VERSION "created by canmatrix"

NS_ :

BS_:

BU_: IPD

BO_ 172 RZCU_PTCANFD_10ms_FrP90: 20 Vector__XXX
 SG_ RZCU_10ms_Group90_CRC : 7|8@0+ (1,0) [0|255] "null" IPD
 SG_ RZCU_10ms_Group90_RC : 11|4@0+ (1,0) [0|15] "null" IPD
 SG_ RZCU_10ms_Group90_Reserved15 : 15|4@0+ (1,0) [0|15] "null" IPD
 SG_ RZCU_10ms_Group90_Reserved23 : 23|8@0+ (1,0) [0|255] "null" IPD
 SG_ RZCU_10ms_Group90_Reserved31 : 31|8@0+ (1,0) [0|255] "null" IPD
 SG_ RZCU_10ms_Group90_Reserved39 : 39|8@0+ (1,0) [0|255] "null" IPD
 SG_ RZCU_10ms_Group90_Reserved47 : 47|8@0+ (1,0) [0|255] "null" IPD
 SG_ RZCU_10ms_Group90_Reserved55 : 55|8@0+ (1,0) [0|255] "null" IPD
 SG_ RZCU_10ms_Group90_Reserved63 : 63|8@0+ (1,0) [0|255] "null" IPD
 SG_ RZCU_10ms_Group90_Reserved71 : 71|8@0+ (1,0) [0|255] "null" IPD
 SG_ RZCU_10ms_Group90_Reserved79 : 79|8@0+ (1,0) [0|255] "null" IPD
 SG_ RZCU_10ms_Group90_Reserved83 : 83|4@0+ (1,0) [0|15] "null" IPD
 SG_ VCU_ISAOvSpdOvRd : 85|2@0+ (1,0) [0|3] "null" IPD
 SG_ RZCU_10ms_Group90_Reserved87 : 87|2@0+ (1,0) [0|3] "null" IPD
 SG_ RZCU_10ms_Group90_Reserved95 : 95|8@0+ (1,0) [0|255] "null" IPD
 SG_ RZCU_10ms_Group90_Reserved103 : 103|8@0+ (1,0) [0|255] "null" IPD
 SG_ RZCU_10ms_Group90_Reserved111 : 111|8@0+ (1,0) [0|255] "null" IPD
 SG_ RZCU_10ms_Group90_Reserved119 : 119|8@0+ (1,0) [0|255] "null" IPD
 SG_ RZCU_10ms_Group90_Reserved127 : 127|8@0+ (1,0) [0|255] "null" IPD
 SG_ RZCU_10ms_Group90_Reserved135 : 135|8@0+ (1,0) [0|255] "null" IPD
 SG_ RZCU_10ms_Group90_Reserved143 : 143|8@0+ (1,0) [0|255] "null" IPD
 SG_ RZCU_10ms_Group90_Reserved151 : 151|8@0+ (1,0) [0|255] "null" IPD
 SG_ RZCU_10ms_Group90_Reserved159 : 159|8@0+ (1,0) [0|255] "null" IPD

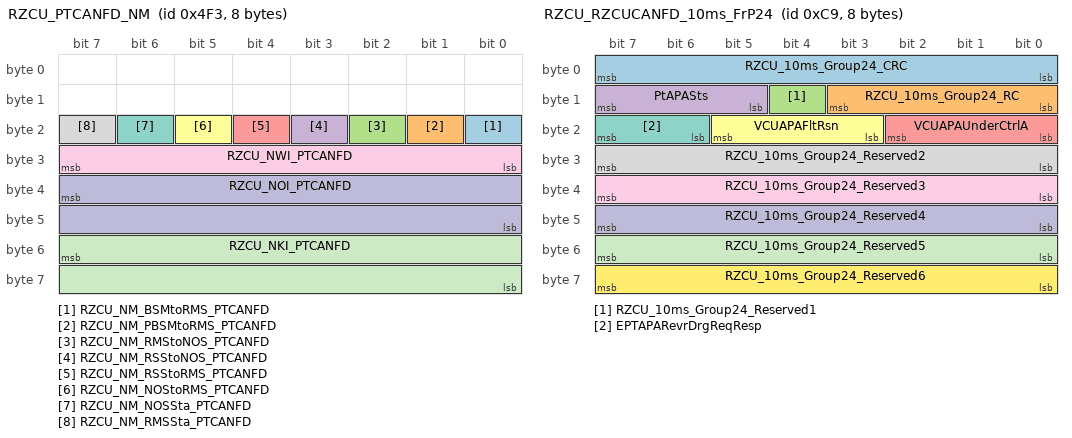
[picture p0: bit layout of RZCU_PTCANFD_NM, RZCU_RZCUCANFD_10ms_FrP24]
BO_ 1267 RZCU_PTCANFD_NM: 8 Vector__XXX
 SG_ RZCU_NM_BSMtoRMS_PTCANFD : 16|1@0+ (1,0) [0|1] "null" Vector__XXX
 SG_ RZCU_NM_PBSMtoRMS_PTCANFD : 17|1@0+ (1,0) [0|1] "null" Vector__XXX
 SG_ RZCU_NM_RMStoNOS_PTCANFD : 18|1@0+ (1,0) [0|1] "null" Vector__XXX
 SG_ RZCU_NM_RSStoNOS_PTCANFD : 19|1@0+ (1,0) [0|1] "null" Vector__XXX
 SG_ RZCU_NM_RSStoRMS_PTCANFD : 20|1@0+ (1,0) [0|1] "null" Vector__XXX
 SG_ RZCU_NM_NOStoRMS_PTCANFD : 21|1@0+ (1,0) [0|1] "null" Vector__XXX
 SG_ RZCU_NM_NOSSta_PTCANFD : 22|1@0+ (1,0) [0|1] "null" Vector__XXX
 SG_ RZCU_NM_RMSSta_PTCANFD : 23|1@0+ (1,0) [0|1] "null" Vector__XXX
 SG_ RZCU_NWI_PTCANFD : 31|8@0+ (1,0) [0|255] "null" Vector__XXX
 SG_ RZCU_NOI_PTCANFD : 39|16@0+ (1,0) [0|65535] "null" Vector__XXX
 SG_ RZCU_NKI_PTCANFD : 55|16@0+ (1,0) [0|65535] "null" Vector__XXX

BO_ 1611 RZCU_RZCUCANFD_1000ms_FrP67: 16 Vector__XXX
 SG_ IMU_SN : 16|96@1- (1,0) [-3.961408125713216879677197517E+028|3.961408125713216879677197517E+028] "null" IPD

BO_ 247 RZCU_RZCUCANFD_10ms_FrP22_NoSecO: 12 Vector__XXX
 SG_ RZCU_10ms_Group22_CRC : 7|8@0+ (1,0) [0|255] "null" IPD
 SG_ RZCU_10ms_Group22_RC : 11|4@0+ (1,0) [0|15] "null" IPD
 SG_ VMCTarWhlTqMaxLmtV : 12|1@0+ (1,0) [0|1] "null" IPD
 SG_ VMCTarReWhlTqMaxLmtV : 13|1@0+ (1,0) [0|1] "null" IPD
 SG_ EPTTrOtptShaftTotMinAvlblToqV : 14|1@0+ (1,0) [0|1] "null" IPD
 SG_ EPTTrOtptShaftTotMaxAvlblToqV : 15|1@0+ (1,0) [0|1] "null" IPD
 SG_ EPTTrOtptShaftTotMaxAvlblToq : 23|12@0+ (0.5,-848) [-848|1199.5] "Nm" IPD
 SG_ EPTTrOtptShaftTotMinAvlblToq : 27|12@0+ (0.5,-848) [-848|1199.5] "Nm" IPD
 SG_ EPTTrOtptShaftTotToq : 43|12@0+ (0.5,-848) [-848|1199.5] "Nm" IPD
 SG_ EPTTrOtptShaftTotToqV : 44|1@0+ (1,0) [0|1] "null" IPD
 SG_ RZCU_10ms_Group22_Reserved47 : 47|3@0+ (1,0) [0|7] "null" IPD
 SG_ VMCTarWhlTqMaxLmt : 63|16@0+ (1,-32767) [-32767|32768] "Nm" IPD
 SG_ VMCTarReWhlTqMaxLmt : 79|16@0+ (1,-32767) [-32767|32768] "Nm" IPD
 SG_ RZCU_10ms_Group22_Reserved95 : 95|8@0+ (1,0) [0|255] "null" IPD

BO_ 225 RZCU_RZCUCANFD_10ms_FrP23: 16 Vector__XXX
 SG_ RZCU_10ms_Group23_CRC : 7|8@0+ (1,0) [0|255] "null" IPD
 SG_ RZCU_10ms_Group23_RC : 11|4@0+ (1,0) [0|15] "null" IPD
 SG_ RZCU_10ms_Group23_Reserved1 : 12|1@0+ (1,0) [0|1] "null" IPD
 SG_ PtAPAToqReqResp : 15|3@0+ (1,0) [0|7] "null" IPD
 SG_ RZCU_10ms_Group23_Reserved3 : 18|3@0+ (1,0) [0|7] "null" IPD
 SG_ AutodDrvngToqReqResp : 21|3@0+ (1,0) [0|7] "null" IPD
 SG_ RZCU_10ms_Group23_Reserved2 : 23|2@0+ (1,0) [0|3] "null" IPD
 SG_ RZCU_10ms_Group23_Reserved4 : 28|5@0+ (1,0) [0|31] "null" IPD
 SG_ PtACCToqReqResp : 31|3@0+ (1,0) [0|7] "null" IPD
 SG_ AIPilotSysSaBrSts : 35|4@0+ (1,0) [0|15] "null" IPD
 SG_ AIPilotSysSaBrInh : 39|4@0+ (1,0) [0|15] "null" IPD
 SG_ RZCU_10ms_Group23_Reserved5 : 47|8@0+ (1,0) [0|255] "null" IPD
 SG_ RZCU_10ms_Group23_Reserved6 : 54|7@0+ (1,0) [0|127] "null" IPD
 SG_ AccelOvrd : 55|1@0+ (1,0) [0|1] "null" IPD
 SG_ RZCU_10ms_Group23_Reserved7 : 63|8@0+ (1,0) [0|255] "null" IPD
 SG_ RZCU_10ms_Group23_Reserved8 : 71|8@0+ (1,0) [0|255] "null" IPD
 SG_ RZCU_10ms_Group23_Reserved9 : 79|8@0+ (1,0) [0|255] "null" IPD
 SG_ RZCU_10ms_Group23_Reserved10 : 87|8@0+ (1,0) [0|255] "null" IPD
 SG_ RZCU_10ms_Group23_Reserved11 : 95|8@0+ (1,0) [0|255] "null" IPD
 SG_ RZCU_10ms_Group23_Reserved12 : 103|8@0+ (1,0) [0|255] "null" IPD
 SG_ RZCU_10ms_Group23_Reserved13 : 111|8@0+ (1,0) [0|255] "null" IPD
 SG_ RZCU_10ms_Group23_Reserved14 : 119|8@0+ (1,0) [0|255] "null" IPD
 SG_ RZCU_10ms_Group23_Reserved15 : 127|8@0+ (1,0) [0|255] "null" IPD

BO_ 201 RZCU_RZCUCANFD_10ms_FrP24: 8 Vector__XXX
 SG_ RZCU_10ms_Group24_CRC : 7|8@0+ (1,0) [0|255] "null" IPD
 SG_ RZCU_10ms_Group24_RC : 11|4@0+ (1,0) [0|15] "null" IPD
 SG_ RZCU_10ms_Group24_Reserved1 : 12|1@0+ (1,0) [0|1] "null" IPD
 SG_ PtAPASts : 15|3@0+ (1,0) [0|7] "null" IPD
 SG_ VCUAPAUnderCtrlA : 18|3@0+ (1,0) [0|7] "null" IPD
 SG_ VCUAPAFltRsn : 21|3@0+ (1,0) [0|7] "null" IPD
 SG_ EPTAPARevrDrgReqResp : 23|2@0+ (1,0) [0|3] "null" IPD
 SG_ RZCU_10ms_Group24_Reserved2 : 31|8@0+ (1,0) [0|255] "null" IPD
 SG_ RZCU_10ms_Group24_Reserved3 : 39|8@0+ (1,0) [0|255] "null" IPD
 SG_ RZCU_10ms_Group24_Reserved4 : 47|8@0+ (1,0) [0|255] "null" IPD
 SG_ RZCU_10ms_Group24_Reserved5 : 55|8@0+ (1,0) [0|255] "null" IPD
 SG_ RZCU_10ms_Group24_Reserved6 : 63|8@0+ (1,0) [0|255] "null" IPD

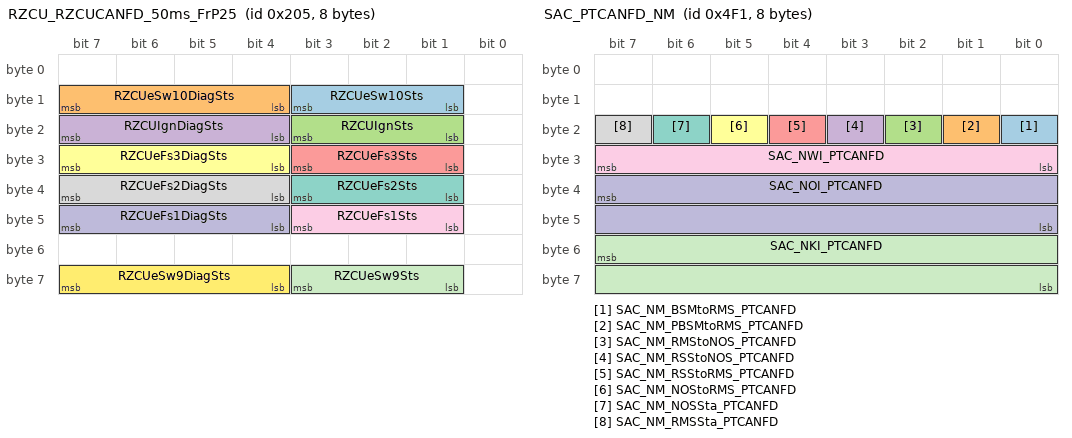
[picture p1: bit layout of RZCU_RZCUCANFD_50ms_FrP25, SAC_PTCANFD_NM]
BO_ 517 RZCU_RZCUCANFD_50ms_FrP25: 8 Vector__XXX
 SG_ RZCUeSw10Sts : 11|3@0+ (1,0) [0|7] "null" Vector__XXX
 SG_ RZCUeSw10DiagSts : 15|4@0+ (1,0) [0|15] "null" Vector__XXX
 SG_ RZCUIgnSts : 19|3@0+ (1,0) [0|7] "null" IPD
 SG_ RZCUIgnDiagSts : 23|4@0+ (1,0) [0|15] "null" IPD
 SG_ RZCUeFs3Sts : 27|3@0+ (1,0) [0|7] "null" Vector__XXX
 SG_ RZCUeFs3DiagSts : 31|4@0+ (1,0) [0|15] "null" Vector__XXX
 SG_ RZCUeFs2Sts : 35|3@0+ (1,0) [0|7] "null" Vector__XXX
 SG_ RZCUeFs2DiagSts : 39|4@0+ (1,0) [0|15] "null" Vector__XXX
 SG_ RZCUeFs1Sts : 43|3@0+ (1,0) [0|7] "null" Vector__XXX
 SG_ RZCUeFs1DiagSts : 47|4@0+ (1,0) [0|15] "null" Vector__XXX
 SG_ RZCUeSw9Sts : 59|3@0+ (1,0) [0|7] "null" Vector__XXX
 SG_ RZCUeSw9DiagSts : 63|4@0+ (1,0) [0|15] "null" Vector__XXX

BO_ 1265 SAC_PTCANFD_NM: 8 Vector__XXX
 SG_ SAC_NM_BSMtoRMS_PTCANFD : 16|1@0+ (1,0) [0|1] "null" Vector__XXX
 SG_ SAC_NM_PBSMtoRMS_PTCANFD : 17|1@0+ (1,0) [0|1] "null" Vector__XXX
 SG_ SAC_NM_RMStoNOS_PTCANFD : 18|1@0+ (1,0) [0|1] "null" Vector__XXX
 SG_ SAC_NM_RSStoNOS_PTCANFD : 19|1@0+ (1,0) [0|1] "null" Vector__XXX
 SG_ SAC_NM_RSStoRMS_PTCANFD : 20|1@0+ (1,0) [0|1] "null" Vector__XXX
 SG_ SAC_NM_NOStoRMS_PTCANFD : 21|1@0+ (1,0) [0|1] "null" Vector__XXX
 SG_ SAC_NM_NOSSta_PTCANFD : 22|1@0+ (1,0) [0|1] "null" Vector__XXX
 SG_ SAC_NM_RMSSta_PTCANFD : 23|1@0+ (1,0) [0|1] "null" Vector__XXX
 SG_ SAC_NWI_PTCANFD : 31|8@0+ (1,0) [0|255] "null" Vector__XXX
 SG_ SAC_NOI_PTCANFD : 39|16@0+ (1,0) [0|65535] "null" Vector__XXX
 SG_ SAC_NKI_PTCANFD : 55|16@0+ (1,0) [0|65535] "null" Vector__XXX

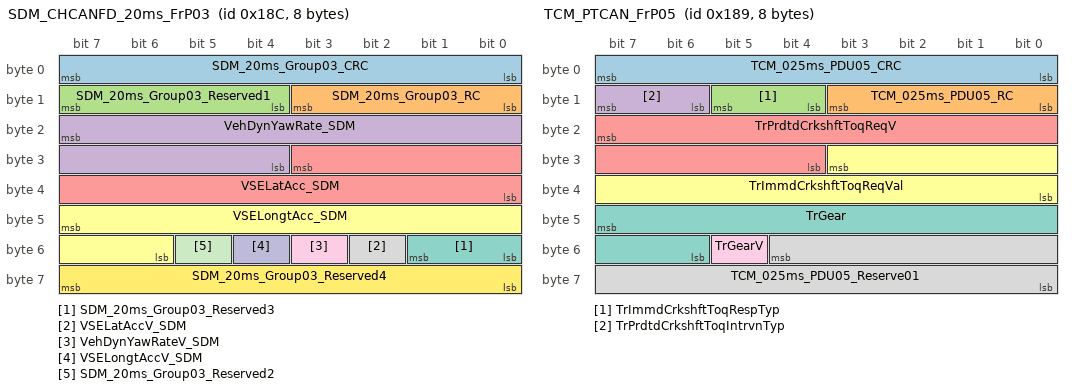
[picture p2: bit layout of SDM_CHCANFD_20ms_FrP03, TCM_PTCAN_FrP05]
BO_ 396 SDM_CHCANFD_20ms_FrP03: 8 Vector__XXX
 SG_ SDM_20ms_Group03_CRC : 7|8@0+ (1,0) [0|255] "null" IPD
 SG_ SDM_20ms_Group03_RC : 11|4@0+ (1,0) [0|15] "null" IPD
 SG_ SDM_20ms_Group03_Reserved1 : 15|4@0+ (1,0) [0|15] "null" IPD
 SG_ VehDynYawRate_SDM : 23|12@0- (0.0625,0) [-128.0000|127.9375] "°/s" IPD
 SG_ VSELatAcc_SDM : 27|12@0- (0.015625,0) [-32.000000|31.984375] "Acceleration" IPD
 SG_ VSELongtAcc_SDM : 47|10@0- (0.03,0) [-15.36|15.33] "Acceleration" IPD
 SG_ SDM_20ms_Group03_Reserved3 : 49|2@0+ (1,0) [0|3] "null" IPD
 SG_ VSELatAccV_SDM : 50|1@0+ (1,0) [0|1] "null" IPD
 SG_ VehDynYawRateV_SDM : 51|1@0+ (1,0) [0|1] "null" IPD
 SG_ VSELongtAccV_SDM : 52|1@0+ (1,0) [0|1] "null" IPD
 SG_ SDM_20ms_Group03_Reserved2 : 53|1@0+ (1,0) [0|1] "null" IPD
 SG_ SDM_20ms_Group03_Reserved4 : 63|8@0+ (1,0) [0|255] "null" IPD

BO_ 485 TCM_PTCAN_FrP02: 8 Vector__XXX
 SG_ TCM_025ms_PDU02_CRC : 7|8@0+ (1,0) [0|255] "null" IPD
 SG_ TCM_025ms_PDU02_RC : 11|4@0+ (1,0) [0|15] "null" IPD
 SG_ AutocTrCmddGear_TCM : 15|4@0+ (1,0) [0|15] "null" IPD
 SG_ DrvrShftCtrlTrgtGear_TCM : 19|4@0+ (1,0) [0|15] "null" IPD
 SG_ TrEPBAppReq : 20|1@0+ (1,0) [0|1] "null" IPD
 SG_ DrvrShftCtrlReqDndIO : 21|1@0+ (1,0) [0|1] "null" IPD
 SG_ TCM_025ms_Group02_Reserved1 : 23|2@0+ (1,0) [0|3] "null" IPD
 SG_ TrShftLvrPos_TCM : 27|4@0+ (1,0) [0|15] "null" IPD
 SG_ TrShftLvrPosV_TCM : 28|1@0+ (1,0) [0|1] "null" IPD
 SG_ TrPrkSysF : 29|1@0+ (1,0) [0|1] "null" IPD
 SG_ TrPrkPos : 31|2@0+ (1,0) [0|3] "null" IPD
 SG_ TrTrgtShftLvrPos : 35|4@0+ (1,0) [0|15] "null" IPD
 SG_ TrEstdGear_TCM : 39|4@0+ (1,0) [0|15] "null" IPD
 SG_ TrTapUpTapDwnMdSts_TCM : 41|2@0+ (1,0) [0|3] "null" IPD
 SG_ TrShftPtrnASts_TCM : 44|3@0+ (1,0) [0|7] "null" IPD
 SG_ TrEstdGearV_TCM : 45|1@0+ (1,0) [0|1] "null" IPD
 SG_ TrCrpMdA_TCM : 46|1@0+ (1,0) [0|1] "null" IPD
 SG_ TCM_025ms_Group02_Reserved2 : 47|1@0+ (1,0) [0|1] "null" IPD
 SG_ TrEngdSta_TCM : 49|2@0+ (1,0) [0|3] "null" IPD
 SG_ TrEngdStaV_TCM : 50|1@0+ (1,0) [0|1] "null" IPD
 SG_ TrIntnlSwPos : 54|4@0+ (1,0) [0|15] "null" IPD
 SG_ TrIntnlSwPosV : 55|1@0+ (1,0) [0|1] "null" IPD
 SG_ TCM_025ms_Group02_Reserved3 : 63|8@0+ (1,0) [0|255] "null" IPD

BO_ 393 TCM_PTCAN_FrP05: 8 Vector__XXX
 SG_ TCM_025ms_PDU05_CRC : 7|8@0+ (1,0) [0|255] "null" IPD
 SG_ TCM_025ms_PDU05_RC : 11|4@0+ (1,0) [0|15] "null" IPD
 SG_ TrImmdCrkshftToqRespTyp : 13|2@0+ (1,0) [0|3] "null" IPD
 SG_ TrPrdtdCrkshftToqIntrvnTyp : 15|2@0+ (1,0) [0|3] "null" IPD
 SG_ TrPrdtdCrkshftToqReqV : 23|12@0+ (0.5,-848) [-848|1199.5] "null" IPD
 SG_ TrImmdCrkshftToqReqVal : 27|12@0+ (0.5,-848) [-848|1199.5] "null" IPD
 SG_ TrGear : 47|10@0+ (0.03125,0) [0.00000|31.96875] "null" IPD
 SG_ TCM_025ms_PDU05_Reserve01 : 52|13@0+ (1,0) [0|8191] "null" IPD
 SG_ TrGearV : 53|1@0+ (1,0) [0|1] "null" IPD

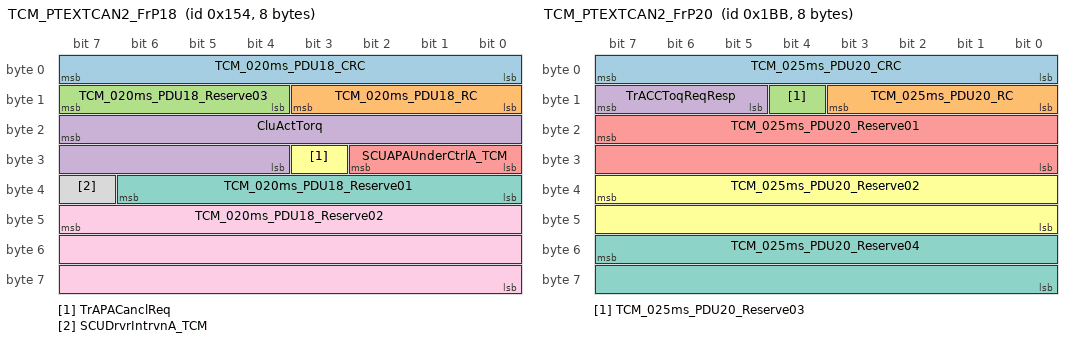
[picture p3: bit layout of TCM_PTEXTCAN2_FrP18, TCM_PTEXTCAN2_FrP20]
BO_ 340 TCM_PTEXTCAN2_FrP18: 8 Vector__XXX
 SG_ TCM_020ms_PDU18_CRC : 7|8@0+ (1,0) [0|255] "null" IPD
 SG_ TCM_020ms_PDU18_RC : 11|4@0+ (1,0) [0|15] "null" IPD
 SG_ TCM_020ms_PDU18_Reserve03 : 15|4@0+ (1,0) [0|15] "null" IPD
 SG_ CluActTorq : 23|12@0+ (1,0) [0|4095] "null" IPD
 SG_ SCUAPAUnderCtrlA_TCM : 26|3@0+ (1,0) [0|7] "null" IPD
 SG_ TrAPACanclReq : 27|1@0+ (1,0) [0|1] "null" IPD
 SG_ TCM_020ms_PDU18_Reserve01 : 38|7@0+ (1,0) [0|127] "null" IPD
 SG_ SCUDrvrIntrvnA_TCM : 39|1@0+ (1,0) [0|1] "null" IPD
 SG_ TCM_020ms_PDU18_Reserve02 : 47|24@0+ (1,0) [0|16777215] "null" IPD

BO_ 443 TCM_PTEXTCAN2_FrP20: 8 Vector__XXX
 SG_ TCM_025ms_PDU20_CRC : 7|8@0+ (1,0) [0|255] "null" IPD
 SG_ TCM_025ms_PDU20_RC : 11|4@0+ (1,0) [0|15] "null" IPD
 SG_ TCM_025ms_PDU20_Reserve03 : 12|1@0+ (1,0) [0|1] "null" IPD
 SG_ TrACCToqReqResp : 15|3@0+ (1,0) [0|7] "null" IPD
 SG_ TCM_025ms_PDU20_Reserve01 : 23|16@0+ (1,0) [0|65535] "null" IPD
 SG_ TCM_025ms_PDU20_Reserve02 : 39|16@0+ (1,0) [0|65535] "null" IPD
 SG_ TCM_025ms_PDU20_Reserve04 : 55|16@0+ (1,0) [0|65535] "null" IPD

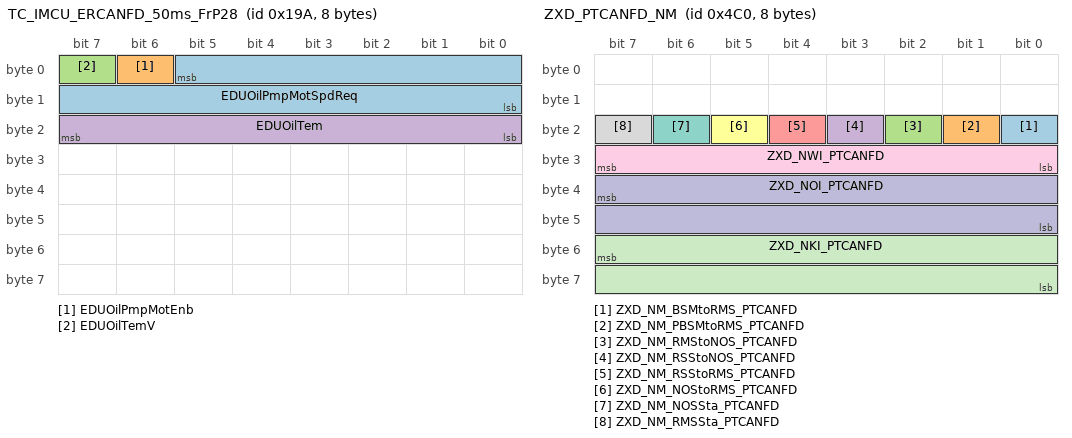
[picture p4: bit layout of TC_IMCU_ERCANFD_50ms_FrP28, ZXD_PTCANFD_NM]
BO_ 410 TC_IMCU_ERCANFD_50ms_FrP28: 8 Vector__XXX
 SG_ EDUOilPmpMotSpdReq : 5|14@0+ (1,-8191) [-8191|8192] "rpm" Vector__XXX
 SG_ EDUOilPmpMotEnb : 6|1@0+ (1,0) [0|1] "null" Vector__XXX
 SG_ EDUOilTemV : 7|1@0+ (1,0) [0|1] "null" IPD
 SG_ EDUOilTem : 23|8@0+ (1,-50) [-50|205] "null" IPD

BO_ 534 ZXD_BKBCANFD_50ms_FrP256: 16 Vector__XXX
 SG_ ICBVC_50ms_Group256_CRC : 7|8@0+ (1,0) [0|255] "null" IPD
 SG_ ICBVC_50ms_Group256_RC : 11|4@0+ (1,0) [0|15] "null" IPD
 SG_ SWSPB3SwStuckL : 12|1@0+ (1,0) [0|1] "null" IPD
 SG_ SWSSelRSwStuckL : 13|1@0+ (1,0) [0|1] "null" IPD
 SG_ SWSSelLSwStuckL : 14|1@0+ (1,0) [0|1] "null" IPD
 SG_ SWSPB2SwStuckL : 15|1@0+ (1,0) [0|1] "null" IPD
 SG_ RoadCrvt : 23|18@0+ (0.005,-655.36) [-655.360|655.355] "null" IPD
 SG_ RoadSlope : 35|12@0+ (0.2,-450) [-450|369] "null" IPD
 SG_ SWSLFnChngSwA : 36|1@0+ (1,0) [0|1] "null" IPD
 SG_ SWSCnfmSwStuckL : 37|1@0+ (1,0) [0|1] "null" IPD
 SG_ RoadCrvtDist : 55|10@0+ (1,0) [0|1023] "null" IPD
 SG_ RoadSlopeDist : 57|10@0+ (1,0) [0|1023] "null" IPD
 SG_ SWSPB1SwStuckL : 58|1@0+ (1,0) [0|1] "null" IPD
 SG_ DMSSts : 61|3@0+ (1,0) [0|7] "null" IPD
 SG_ RoughRoaddetectionDist : 79|10@0+ (1,0) [0|1023] "null" IPD
 SG_ ICBVC_50ms_Group256_Reserved85 : 85|6@0+ (1,0) [0|63] "null" IPD
 SG_ ICBVC_50ms_Group256_Reserved95 : 95|8@0+ (1,0) [0|255] "null" IPD
 SG_ ICBVC_50ms_Group256_Reserved96 : 96|1@0+ (1,0) [0|1] "null" IPD
 SG_ VehboardSetting : 98|2@0+ (1,0) [0|3] "null" IPD
 SG_ ICBVC_50ms_Group256_Reserved100 : 100|2@0+ (1,0) [0|3] "null" IPD
 SG_ RoughRoaddetection : 101|1@0+ (1,0) [0|1] "null" IPD
 SG_ ICBVC_50ms_Group256_Reserved103 : 103|2@0+ (1,0) [0|3] "null" IPD
 SG_ ICBVC_50ms_Group256_Reserved111 : 111|8@0+ (1,0) [0|255] "null" IPD
 SG_ ICBVC_50ms_Group256_Reserved119 : 119|8@0+ (1,0) [0|255] "null" IPD
 SG_ ICBVC_50ms_Group256_Reserved127 : 127|8@0+ (1,0) [0|255] "null" IPD

BO_ 1216 ZXD_PTCANFD_NM: 8 Vector__XXX
 SG_ ZXD_NM_BSMtoRMS_PTCANFD : 16|1@0+ (1,0) [0|1] "null" Vector__XXX
 SG_ ZXD_NM_PBSMtoRMS_PTCANFD : 17|1@0+ (1,0) [0|1] "null" Vector__XXX
 SG_ ZXD_NM_RMStoNOS_PTCANFD : 18|1@0+ (1,0) [0|1] "null" Vector__XXX
 SG_ ZXD_NM_RSStoNOS_PTCANFD : 19|1@0+ (1,0) [0|1] "null" Vector__XXX
 SG_ ZXD_NM_RSStoRMS_PTCANFD : 20|1@0+ (1,0) [0|1] "null" Vector__XXX
 SG_ ZXD_NM_NOStoRMS_PTCANFD : 21|1@0+ (1,0) [0|1] "null" Vector__XXX
 SG_ ZXD_NM_NOSSta_PTCANFD : 22|1@0+ (1,0) [0|1] "null" Vector__XXX
 SG_ ZXD_NM_RMSSta_PTCANFD : 23|1@0+ (1,0) [0|1] "null" Vector__XXX
 SG_ ZXD_NWI_PTCANFD : 31|8@0+ (1,0) [0|255] "null" Vector__XXX
 SG_ ZXD_NOI_PTCANFD : 39|16@0+ (1,0) [0|65535] "null" Vector__XXX
 SG_ ZXD_NKI_PTCANFD : 55|16@0+ (1,0) [0|65535] "null" Vector__XXX

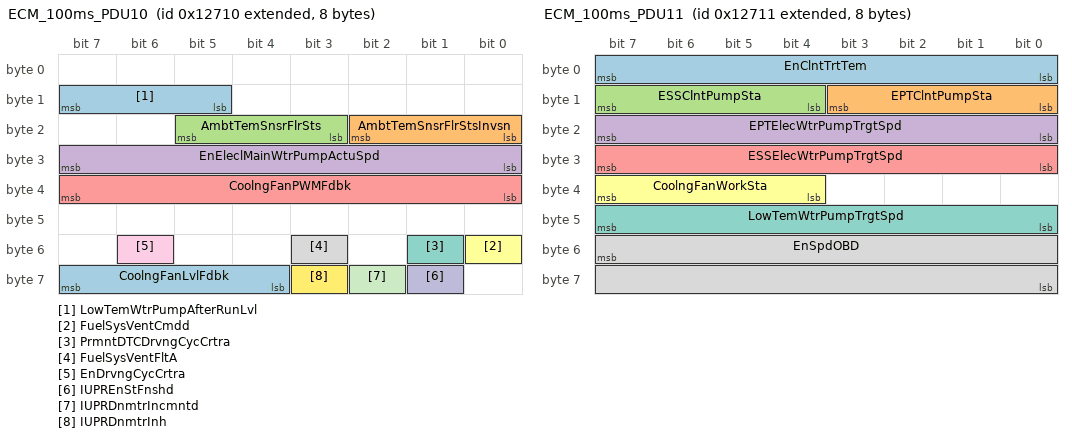
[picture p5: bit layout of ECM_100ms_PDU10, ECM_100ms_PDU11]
BO_ 2147559184 ECM_100ms_PDU10: 8 Vector__XXX
 SG_ LowTemWtrPumpAfterRunLvl : 15|3@0+ (1,0) [0|7] "null" Vector__XXX
 SG_ AmbtTemSnsrFlrStsInvsn : 18|3@0+ (1,0) [0|7] "null" Vector__XXX
 SG_ AmbtTemSnsrFlrSts : 21|3@0+ (1,0) [0|7] "null" Vector__XXX
 SG_ EnEleclMainWtrPumpActuSpd : 31|8@0+ (20,0) [0|5100] "RPM" Vector__XXX
 SG_ CoolngFanPWMFdbk : 39|8@0+ (0.4,0) [0|102] "null" Vector__XXX
 SG_ FuelSysVentCmdd : 48|1@0+ (1,0) [0|1] "null" Vector__XXX
 SG_ PrmntDTCDrvngCycCrtra : 49|1@0+ (1,0) [0|1] "null" Vector__XXX
 SG_ FuelSysVentFltA : 51|1@0+ (1,0) [0|1] "null" Vector__XXX
 SG_ EnDrvngCycCrtra : 54|1@0+ (1,0) [0|1] "null" Vector__XXX
 SG_ IUPREnStFnshd : 57|1@0+ (1,0) [0|1] "null" Vector__XXX
 SG_ IUPRDnmtrIncmntd : 58|1@0+ (1,0) [0|1] "null" Vector__XXX
 SG_ IUPRDnmtrInh : 59|1@0+ (1,0) [0|1] "null" Vector__XXX
 SG_ CoolngFanLvlFdbk : 63|4@0+ (1,0) [0|15] "null" Vector__XXX

BO_ 2147559185 ECM_100ms_PDU11: 8 Vector__XXX
 SG_ EnClntTrtTem : 7|8@0+ (1,-40) [-40|215] "null" Vector__XXX
 SG_ EPTClntPumpSta : 11|4@0+ (1,0) [0|15] "null" IPD
 SG_ ESSClntPumpSta : 15|4@0+ (1,0) [0|15] "null" Vector__XXX
 SG_ EPTElecWtrPumpTrgtSpd : 23|8@0+ (0.4,0) [0|102] "null" Vector__XXX
 SG_ ESSElecWtrPumpTrgtSpd : 31|8@0+ (0.4,0) [0|102] "null" Vector__XXX
 SG_ CoolngFanWorkSta : 39|4@0+ (1,0) [0|15] "null" Vector__XXX
 SG_ LowTemWtrPumpTrgtSpd : 47|8@0+ (0.4,0) [0|102] "null" Vector__XXX
 SG_ EnSpdOBD : 55|16@0+ (0.25,0) [0.00|16383.75] "null" Vector__XXX

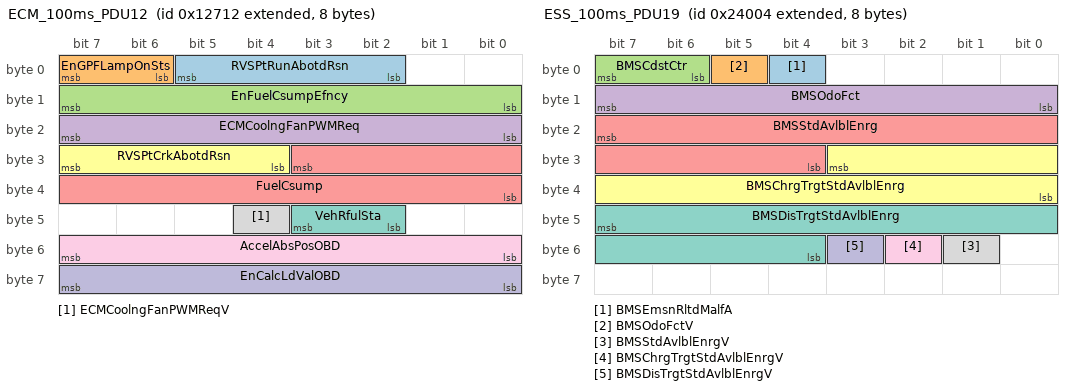
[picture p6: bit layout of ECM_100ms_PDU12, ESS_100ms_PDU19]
BO_ 2147559186 ECM_100ms_PDU12: 8 Vector__XXX
 SG_ RVSPtRunAbotdRsn : 5|4@0+ (1,0) [0|15] "null" Vector__XXX
 SG_ EnGPFLampOnSts : 7|2@0+ (1,0) [0|3] "null" Vector__XXX
 SG_ EnFuelCsumpEfncy : 15|8@0+ (0.392157,0) [0.000000|100.000035] "null" Vector__XXX
 SG_ ECMCoolngFanPWMReq : 23|8@0+ (0.4,0) [0|102] "null" Vector__XXX
 SG_ FuelCsump : 27|12@0+ (16,0) [0|65520] "null" Vector__XXX
 SG_ RVSPtCrkAbotdRsn : 31|4@0+ (1,0) [0|15] "null" Vector__XXX
 SG_ VehRfulSta : 43|2@0+ (1,0) [0|3] "null" Vector__XXX
 SG_ ECMCoolngFanPWMReqV : 44|1@0+ (1,0) [0|1] "null" Vector__XXX
 SG_ AccelAbsPosOBD : 55|8@0+ (0.392157,0) [0.000000|100.000035] "null" Vector__XXX
 SG_ EnCalcLdValOBD : 63|8@0+ (0.392157,0) [0.000000|100.000035] "null" Vector__XXX

BO_ 2147631108 ESS_100ms_PDU19: 8 Vector__XXX
 SG_ BMSEmsnRltdMalfA : 4|1@0+ (1,0) [0|1] "null" Vector__XXX
 SG_ BMSOdoFctV : 5|1@0+ (1,0) [0|1] "null" Vector__XXX
 SG_ BMSCdstCtr : 7|2@0+ (1,0) [0|3] "null" Vector__XXX
 SG_ BMSOdoFct : 15|8@0+ (0.5,0) [0|127.5] "Percent" Vector__XXX
 SG_ BMSStdAvlblEnrg : 23|12@0+ (0.05,0) [0.00|204.75] "kwh" Vector__XXX
 SG_ BMSChrgTrgtStdAvlblEnrg : 27|12@0+ (0.05,0) [0.00|204.75] "kwh" Vector__XXX
 SG_ BMSDisTrgtStdAvlblEnrg : 47|12@0+ (0.05,0) [0.00|204.75] "kwh" Vector__XXX
 SG_ BMSStdAvlblEnrgV : 49|1@0+ (1,0) [0|1] "null" Vector__XXX
 SG_ BMSChrgTrgtStdAvlblEnrgV : 50|1@0+ (1,0) [0|1] "null" Vector__XXX
 SG_ BMSDisTrgtStdAvlblEnrgV : 51|1@0+ (1,0) [0|1] "null" Vector__XXX

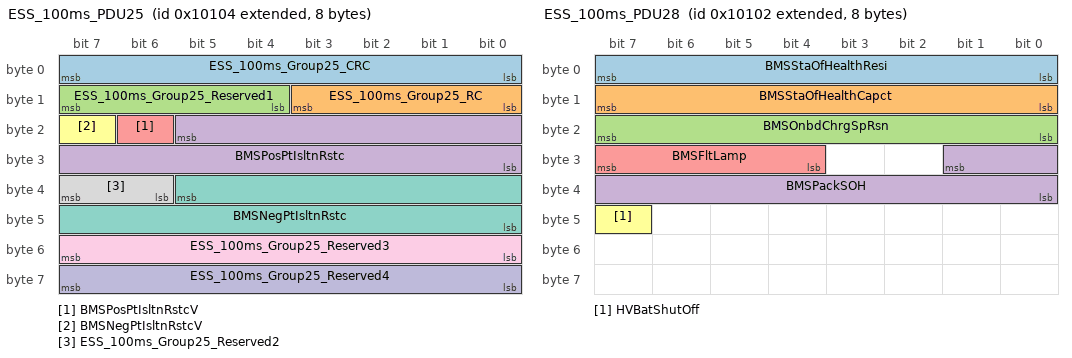
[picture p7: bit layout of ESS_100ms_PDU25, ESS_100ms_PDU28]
BO_ 2147549444 ESS_100ms_PDU25: 8 Vector__XXX
 SG_ ESS_100ms_Group25_CRC : 7|8@0+ (1,0) [0|255] "null" Vector__XXX
 SG_ ESS_100ms_Group25_RC : 11|4@0+ (1,0) [0|15] "null" Vector__XXX
 SG_ ESS_100ms_Group25_Reserved1 : 15|4@0+ (1,0) [0|15] "null" Vector__XXX
 SG_ BMSPosPtIsltnRstc : 21|14@0+ (0.5,0) [0|8191.5] "kOhm" Vector__XXX
 SG_ BMSPosPtIsltnRstcV : 22|1@0+ (1,0) [0|1] "null" Vector__XXX
 SG_ BMSNegPtIsltnRstcV : 23|1@0+ (1,0) [0|1] "null" Vector__XXX
 SG_ BMSNegPtIsltnRstc : 37|14@0+ (0.5,0) [0|8191.5] "kOhm" Vector__XXX
 SG_ ESS_100ms_Group25_Reserved2 : 39|2@0+ (1,0) [0|3] "null" Vector__XXX
 SG_ ESS_100ms_Group25_Reserved3 : 55|8@0+ (1,0) [0|255] "null" Vector__XXX
 SG_ ESS_100ms_Group25_Reserved4 : 63|8@0+ (1,0) [0|255] "null" Vector__XXX

BO_ 2147549442 ESS_100ms_PDU28: 8 Vector__XXX
 SG_ BMSStaOfHealthResi : 7|8@0+ (0.5,0) [0|127.5] "null" Vector__XXX
 SG_ BMSStaOfHealthCapct : 15|8@0+ (0.5,0) [0|127.5] "null" Vector__XXX
 SG_ BMSOnbdChrgSpRsn : 23|8@0+ (1,0) [0|255] "null" Vector__XXX
 SG_ BMSPackSOH : 25|10@0+ (0.1,0) [0|102.3] "null" Vector__XXX
 SG_ BMSFltLamp : 31|4@0+ (1,0) [0|15] "null" Vector__XXX
 SG_ HVBatShutOff : 47|1@0+ (1,0) [0|1] "null" Vector__XXX

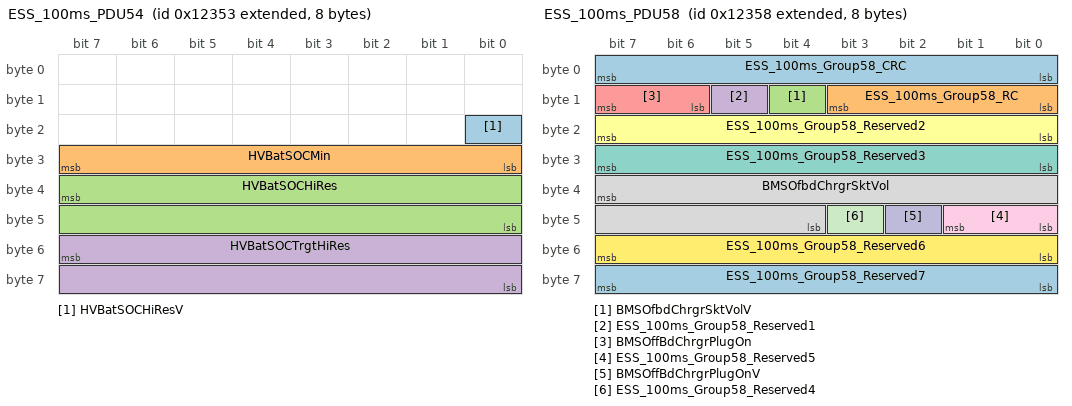
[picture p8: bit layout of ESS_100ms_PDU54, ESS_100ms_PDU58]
BO_ 2147558227 ESS_100ms_PDU54: 8 Vector__XXX
 SG_ HVBatSOCHiResV : 16|1@0+ (1,0) [0|1] "null" Vector__XXX
 SG_ HVBatSOCMin : 31|8@0+ (0.392157,0) [0.000000|100.000035] "null" Vector__XXX
 SG_ HVBatSOCHiRes : 39|16@0+ (0.00152593,0) [0E-008|100.00182255] "null" Vector__XXX
 SG_ HVBatSOCTrgtHiRes : 55|16@0+ (0.001526,0) [0.000000|100.006410] "null" Vector__XXX

BO_ 2147558232 ESS_100ms_PDU58: 8 Vector__XXX
 SG_ ESS_100ms_Group58_CRC : 7|8@0+ (1,0) [0|255] "null" IPD
 SG_ ESS_100ms_Group58_RC : 11|4@0+ (1,0) [0|15] "null" IPD
 SG_ BMSOfbdChrgrSktVolV : 12|1@0+ (1,0) [0|1] "null" IPD
 SG_ ESS_100ms_Group58_Reserved1 : 13|1@0+ (1,0) [0|1] "null" IPD
 SG_ BMSOffBdChrgrPlugOn : 15|2@0+ (1,0) [0|3] "null" IPD
 SG_ ESS_100ms_Group58_Reserved2 : 23|8@0+ (1,0) [0|255] "null" IPD
 SG_ ESS_100ms_Group58_Reserved3 : 31|8@0+ (1,0) [0|255] "null" IPD
 SG_ BMSOfbdChrgrSktVol : 39|12@0+ (0.25,0) [0.00|1023.75] "null" IPD
 SG_ ESS_100ms_Group58_Reserved5 : 41|2@0+ (1,0) [0|3] "null" IPD
 SG_ BMSOffBdChrgrPlugOnV : 42|1@0+ (1,0) [0|1] "null" IPD
 SG_ ESS_100ms_Group58_Reserved4 : 43|1@0+ (1,0) [0|1] "null" IPD
 SG_ ESS_100ms_Group58_Reserved6 : 55|8@0+ (1,0) [0|255] "null" IPD
 SG_ ESS_100ms_Group58_Reserved7 : 63|8@0+ (1,0) [0|255] "null" IPD

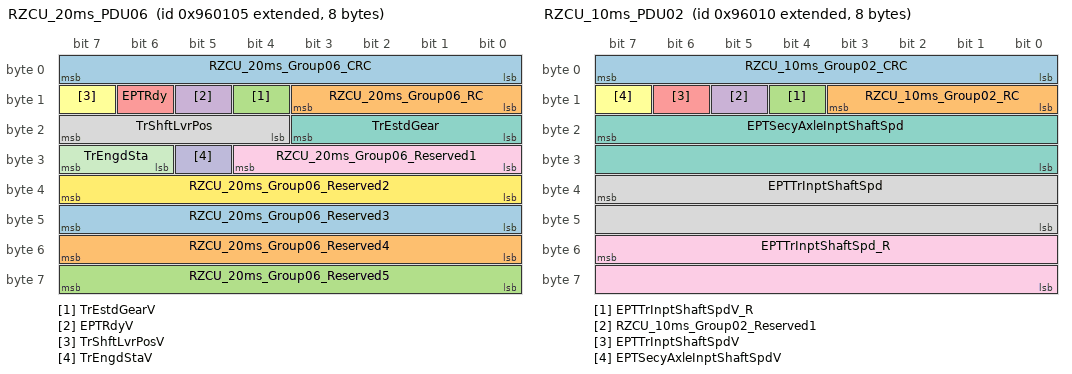
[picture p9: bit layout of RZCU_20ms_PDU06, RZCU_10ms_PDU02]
BO_ 2157314309 RZCU_20ms_PDU06: 8 Vector__XXX
 SG_ RZCU_20ms_Group06_CRC : 7|8@0+ (1,0) [0|255] "null" IPD
 SG_ RZCU_20ms_Group06_RC : 11|4@0+ (1,0) [0|15] "null" IPD
 SG_ TrEstdGearV : 12|1@0+ (1,0) [0|1] "null" IPD
 SG_ EPTRdyV : 13|1@0+ (1,0) [0|1] "null" IPD
 SG_ EPTRdy : 14|1@0+ (1,0) [0|1] "null" IPD
 SG_ TrShftLvrPosV : 15|1@0+ (1,0) [0|1] "null" IPD
 SG_ TrEstdGear : 19|4@0+ (1,0) [0|15] "null" IPD
 SG_ TrShftLvrPos : 23|4@0+ (1,0) [0|15] "null" IPD
 SG_ RZCU_20ms_Group06_Reserved1 : 28|5@0+ (1,0) [0|31] "null" IPD
 SG_ TrEngdStaV : 29|1@0+ (1,0) [0|1] "null" IPD
 SG_ TrEngdSta : 31|2@0+ (1,0) [0|3] "null" IPD
 SG_ RZCU_20ms_Group06_Reserved2 : 39|8@0+ (1,0) [0|255] "null" IPD
 SG_ RZCU_20ms_Group06_Reserved3 : 47|8@0+ (1,0) [0|255] "null" IPD
 SG_ RZCU_20ms_Group06_Reserved4 : 55|8@0+ (1,0) [0|255] "null" IPD
 SG_ RZCU_20ms_Group06_Reserved5 : 63|8@0+ (1,0) [0|255] "null" IPD

BO_ 2157314311 RZCU_20ms_PDU07: 8 Vector__XXX
 SG_ EPTRunCrkTrmlSts : 13|2@0+ (1,0) [0|3] "null" Vector__XXX
 SG_ EPTSimEnSpd : 23|16@0+ (0.25,0) [0.00|16383.75] "rpm" Vector__XXX

BO_ 2148098050 RZCU_10ms_PDU01: 8 Vector__XXX
 SG_ RZCU_10ms_Group01_CRC : 7|8@0+ (1,0) [0|255] "null" IPD
 SG_ RZCU_10ms_Group01_RC : 11|4@0+ (1,0) [0|15] "null" IPD
 SG_ ElecMotEmgcShutDwn : 12|1@0+ (1,0) [0|1] "null" IPD
 SG_ EPTHVEmgcPwrOffReq : 13|1@0+ (1,0) [0|1] "null" IPD
 SG_ EPTMainRelayDrvReq : 15|2@0+ (1,0) [0|3] "null" IPD
 SG_ EPTStCmdOn : 16|1@0+ (1,0) [0|1] "null" IPD
 SG_ EPTAccelActuPosV : 17|1@0+ (1,0) [0|1] "null" IPD
 SG_ AutoChrgngMngmnt : 19|2@0+ (1,0) [0|3] "null" IPD
 SG_ EPTBrkPdlDscrtInptStsV : 20|1@0+ (1,0) [0|1] "null" IPD
 SG_ EPTBrkPdlDscrtInptSts : 21|1@0+ (1,0) [0|1] "null" IPD
 SG_ RVSEPTRdy : 22|1@0+ (1,0) [0|1] "null" IPD
 SG_ EPTCrkAbotd : 23|1@0+ (1,0) [0|1] "null" IPD
 SG_ RZCU_10ms_Group01_Reserved1 : 28|5@0+ (1,0) [0|31] "null" IPD
 SG_ EPTHVDCDCMdReq : 31|3@0+ (1,0) [0|7] "null" IPD
 SG_ EPTAccelActuPos : 39|8@0+ (0.392157,0) [0.000000|100.000035] "null" IPD
 SG_ EPTAccelEfctvPos : 47|8@0+ (0.392157,0) [0.000000|100.000035] "Percent" IPD
 SG_ RZCU_10ms_Group01_Reserved2 : 55|8@0+ (1,0) [0|255] "null" IPD
 SG_ RZCU_10ms_Group01_Reserved3 : 63|8@0+ (1,0) [0|255] "null" IPD

BO_ 2148098064 RZCU_10ms_PDU02: 8 Vector__XXX
 SG_ RZCU_10ms_Group02_CRC : 7|8@0+ (1,0) [0|255] "null" IPD
 SG_ RZCU_10ms_Group02_RC : 11|4@0+ (1,0) [0|15] "null" IPD
 SG_ EPTTrInptShaftSpdV_R : 12|1@0+ (1,0) [0|1] "null" IPD
 SG_ RZCU_10ms_Group02_Reserved1 : 13|1@0+ (1,0) [0|1] "null" IPD
 SG_ EPTTrInptShaftSpdV : 14|1@0+ (1,0) [0|1] "null" IPD
 SG_ EPTSecyAxleInptShaftSpdV : 15|1@0+ (1,0) [0|1] "null" IPD
 SG_ EPTSecyAxleInptShaftSpd : 23|16@0+ (1,-32767) [-32767|32768] "rpm" IPD
 SG_ EPTTrInptShaftSpd : 39|16@0+ (1,-32767) [-32767|32768] "rpm" IPD
 SG_ EPTTrInptShaftSpd_R : 55|16@0+ (1,-32767) [-32767|32768] "rpm" IPD

BA_DEF_ BO_ "FrameTriggeringName" STRING;
BA_DEF_ BO_ "GenMsgCycleTime" INT 0 65535;
BA_DEF_ BO_ "GenMsgSendType" ENUM  "cyclicX","spontanX","cyclicIfActiveX","spontanWithDelay","cyclicAndSpontanX","cyclicAndSpontanWithDelay","spontanWithRepitition","cyclicIfActiveAndSpontanWD","cyclicIfActiveFast","cyclicWithRepeatOnDemand","none";
BA_DEF_ BO_ "GenMsgStartValue" STRING;
BA_DEF_ BO_ "PduName" STRING;
BA_DEF_ BO_ "SystemMessageLongSymbol" STRING;
BA_DEF_ BO_ "VFrameFormat" ENUM  "StandardCAN","ExtendedCAN","reserved","reserved","reserved","reserved","reserved","reserved","reserved","reserved","reserved","reserved","reserved","reserved","StandardCAN_FD","ExtendedCAN_FD";
BA_DEF_ SG_ "CompuMethodName" STRING;
BA_DEF_ SG_ "GenSigStartValue" FLOAT 0 100000000000;
BA_DEF_ SG_ "ISignalName" STRING;
BA_DEF_ SG_ "LongName" STRING;
BA_DEF_ SG_ "SysSignalName" STRING;
BA_DEF_ SG_ "SystemSignalLongSymbol" STRING;
BA_ "FrameTriggeringName" BO_ 172 "RZCU_PTCANFD_10ms_FrP90";
BA_ "GenMsgCycleTime" BO_ 172 10;
BA_ "GenMsgSendType" BO_ 172 0;
BA_ "GenMsgStartValue" BO_ 172 "00f0ffffffffffffffffcfffffffffffffffffff";
BA_ "PduName" BO_ 172 "RZCU_10ms_PDU90";
BA_ "VFrameFormat" BO_ 172 14;
BA_ "FrameTriggeringName" BO_ 1267 "RZCU_PTCANFD_NM";
BA_ "GenMsgSendType" BO_ 1267 1;
BA_ "GenMsgStartValue" BO_ 1267 "0000000000000000";
BA_ "PduName" BO_ 1267 "NmPDU_PTCANFD_RZCU";
BA_ "VFrameFormat" BO_ 1267 14;
BA_ "FrameTriggeringName" BO_ 1611 "RZCU_RZCUCANFD_1000ms_FrP67";
BA_ "GenMsgCycleTime" BO_ 1611 1000;
BA_ "GenMsgSendType" BO_ 1611 0;
BA_ "GenMsgStartValue" BO_ 1611 "00000000000000000000000000000000";
BA_ "PduName" BO_ 1611 "RZCU_1000ms_PDU67";
BA_ "VFrameFormat" BO_ 1611 14;
BA_ "FrameTriggeringName" BO_ 247 "RZCU_RZCUCANFD_10ms_FrP22_NoSecOC";
BA_ "GenMsgCycleTime" BO_ 247 10;
BA_ "GenMsgSendType" BO_ 247 0;
BA_ "GenMsgStartValue" BO_ 247 "00306a0000f0007fff7fffff";
BA_ "PduName" BO_ 247 "RZCU_10ms_PDU22";
BA_ "SystemMessageLongSymbol" BO_ 247 "RZCU_RZCUCANFD_10ms_FrP22_NoSecOC";
BA_ "VFrameFormat" BO_ 247 14;
BA_ "FrameTriggeringName" BO_ 225 "RZCU_RZCUCANFD_10ms_FrP23";
BA_ "GenMsgCycleTime" BO_ 225 10;
BA_ "GenMsgSendType" BO_ 225 0;
BA_ "GenMsgStartValue" BO_ 225 "0010c71f00ff7fffffffffffffffffff";
BA_ "PduName" BO_ 225 "RZCU_10ms_PDU23";
BA_ "VFrameFormat" BO_ 225 14;
BA_ "FrameTriggeringName" BO_ 201 "RZCU_RZCUCANFD_10ms_FrP24";
BA_ "GenMsgCycleTime" BO_ 201 10;
BA_ "GenMsgSendType" BO_ 201 0;
BA_ "GenMsgStartValue" BO_ 201 "001000ffffffffff";
BA_ "PduName" BO_ 201 "RZCU_10ms_PDU24";
BA_ "VFrameFormat" BO_ 201 14;
BA_ "FrameTriggeringName" BO_ 517 "RZCU_RZCUCANFD_50ms_FrP25";
BA_ "GenMsgCycleTime" BO_ 517 50;
BA_ "GenMsgSendType" BO_ 517 0;
BA_ "GenMsgStartValue" BO_ 517 "0000000000000000";
BA_ "PduName" BO_ 517 "RZCU_50ms_PDU25";
BA_ "VFrameFormat" BO_ 517 14;
BA_ "FrameTriggeringName" BO_ 1265 "SAC_PTCANFD_NM";
BA_ "GenMsgSendType" BO_ 1265 1;
BA_ "GenMsgStartValue" BO_ 1265 "0000000000000000";
BA_ "PduName" BO_ 1265 "NmPDU_PTCANFD_SAC";
BA_ "VFrameFormat" BO_ 1265 14;
BA_ "FrameTriggeringName" BO_ 396 "SDM_CHCANFD_20ms_FrP03";
BA_ "GenMsgCycleTime" BO_ 396 20;
BA_ "GenMsgSendType" BO_ 396 0;
BA_ "GenMsgStartValue" BO_ 396 "00f00000000023ff";
BA_ "PduName" BO_ 396 "SDM_20ms_PDU03";
BA_ "VFrameFormat" BO_ 396 14;
BA_ "FrameTriggeringName" BO_ 485 "TCM_PTCAN_FrP02";
BA_ "GenMsgCycleTime" BO_ 485 25;
BA_ "GenMsgSendType" BO_ 485 0;
BA_ "GenMsgStartValue" BO_ 485 "0000c000008000ff";
BA_ "PduName" BO_ 485 "TCM_025ms_PDU02";
BA_ "VFrameFormat" BO_ 485 14;
BA_ "FrameTriggeringName" BO_ 393 "TCM_PTCAN_FrP05";
BA_ "GenMsgCycleTime" BO_ 393 25;
BA_ "GenMsgSendType" BO_ 393 0;
BA_ "GenMsgStartValue" BO_ 393 "0000000000001fff";
BA_ "PduName" BO_ 393 "TCM_025ms_PDU05";
BA_ "VFrameFormat" BO_ 393 14;
BA_ "FrameTriggeringName" BO_ 340 "TCM_PTEXTCAN2_FrP18";
BA_ "GenMsgCycleTime" BO_ 340 20;
BA_ "GenMsgSendType" BO_ 340 0;
BA_ "GenMsgStartValue" BO_ 340 "00f000007fffffff";
BA_ "PduName" BO_ 340 "TCM_020ms_PDU18";
BA_ "VFrameFormat" BO_ 340 14;
BA_ "FrameTriggeringName" BO_ 443 "TCM_PTEXTCAN2_FrP20";
BA_ "GenMsgCycleTime" BO_ 443 25;
BA_ "GenMsgSendType" BO_ 443 0;
BA_ "GenMsgStartValue" BO_ 443 "0010ffffffffffff";
BA_ "PduName" BO_ 443 "TCM_025ms_PDU20";
BA_ "VFrameFormat" BO_ 443 14;
BA_ "FrameTriggeringName" BO_ 410 "TC_IMCU_ERCANFD_50ms_FrP28";
BA_ "GenMsgCycleTime" BO_ 410 50;
BA_ "GenMsgSendType" BO_ 410 0;
BA_ "GenMsgStartValue" BO_ 410 "9fff000000000000";
BA_ "PduName" BO_ 410 "TC_IMCU_50ms_PDU28";
BA_ "VFrameFormat" BO_ 410 14;
BA_ "FrameTriggeringName" BO_ 534 "ZXD_BKBCANFD_50ms_FrP256";
BA_ "GenMsgCycleTime" BO_ 534 50;
BA_ "GenMsgSendType" BO_ 534 0;
BA_ "GenMsgStartValue" BO_ 534 "008080003800000400003fffd9ffffff";
BA_ "PduName" BO_ 534 "ICBVC_50ms_PDU256";
BA_ "VFrameFormat" BO_ 534 14;
BA_ "FrameTriggeringName" BO_ 1216 "ZXD_PTCANFD_NM";
BA_ "GenMsgSendType" BO_ 1216 1;
BA_ "GenMsgStartValue" BO_ 1216 "0000000000000000";
BA_ "PduName" BO_ 1216 "NmPDU_PTCANFD_ZXD";
BA_ "VFrameFormat" BO_ 1216 14;
BA_ "FrameTriggeringName" BO_ 2147559184 "ECM_ERCANFD_100ms_ConFrP10__ECM_100ms_PDU10";
BA_ "GenMsgCycleTime" BO_ 2147559184 100;
BA_ "GenMsgSendType" BO_ 2147559184 1;
BA_ "PduName" BO_ 2147559184 "ECM_100ms_PDU10";
BA_ "VFrameFormat" BO_ 2147559184 15;
BA_ "FrameTriggeringName" BO_ 2147559185 "ECM_ERCANFD_100ms_ConFrP10__ECM_100ms_PDU11";
BA_ "GenMsgCycleTime" BO_ 2147559185 100;
BA_ "GenMsgSendType" BO_ 2147559185 1;
BA_ "PduName" BO_ 2147559185 "ECM_100ms_PDU11";
BA_ "VFrameFormat" BO_ 2147559185 15;
BA_ "FrameTriggeringName" BO_ 2147559186 "ECM_ERCANFD_100ms_ConFrP10__ECM_100ms_PDU12";
BA_ "GenMsgCycleTime" BO_ 2147559186 100;
BA_ "GenMsgSendType" BO_ 2147559186 1;
BA_ "PduName" BO_ 2147559186 "ECM_100ms_PDU12";
BA_ "VFrameFormat" BO_ 2147559186 15;
BA_ "FrameTriggeringName" BO_ 2147631108 "ESS_PTCANFD_100ms_ConFrP19__ESS_100ms_PDU19";
BA_ "GenMsgCycleTime" BO_ 2147631108 100;
BA_ "GenMsgSendType" BO_ 2147631108 1;
BA_ "PduName" BO_ 2147631108 "ESS_100ms_PDU19";
BA_ "VFrameFormat" BO_ 2147631108 15;
BA_ "FrameTriggeringName" BO_ 2147549444 "ESS_PTCANFD_100ms_ConFrP19__ESS_100ms_PDU25";
BA_ "GenMsgCycleTime" BO_ 2147549444 100;
BA_ "GenMsgSendType" BO_ 2147549444 1;
BA_ "PduName" BO_ 2147549444 "ESS_100ms_PDU25";
BA_ "VFrameFormat" BO_ 2147549444 15;
BA_ "FrameTriggeringName" BO_ 2147549442 "ESS_PTCANFD_100ms_ConFrP19__ESS_100ms_PDU28";
BA_ "GenMsgCycleTime" BO_ 2147549442 100;
BA_ "GenMsgSendType" BO_ 2147549442 1;
BA_ "PduName" BO_ 2147549442 "ESS_100ms_PDU28";
BA_ "VFrameFormat" BO_ 2147549442 15;
BA_ "FrameTriggeringName" BO_ 2147558227 "ESS_PTCANFD_100ms_ConFrP19__ESS_100ms_PDU54";
BA_ "GenMsgCycleTime" BO_ 2147558227 100;
BA_ "GenMsgSendType" BO_ 2147558227 1;
BA_ "PduName" BO_ 2147558227 "ESS_100ms_PDU54";
BA_ "VFrameFormat" BO_ 2147558227 15;
BA_ "FrameTriggeringName" BO_ 2147558232 "ESS_PTCANFD_100ms_ConFrP19__ESS_100ms_PDU58";
BA_ "GenMsgCycleTime" BO_ 2147558232 100;
BA_ "GenMsgSendType" BO_ 2147558232 1;
BA_ "PduName" BO_ 2147558232 "ESS_100ms_PDU58";
BA_ "VFrameFormat" BO_ 2147558232 15;
BA_ "FrameTriggeringName" BO_ 2157314309 "RZCU_PTCANFD_20ms_ConFrP06__RZCU_20ms_PDU06";
BA_ "GenMsgCycleTime" BO_ 2157314309 20;
BA_ "GenMsgSendType" BO_ 2157314309 1;
BA_ "PduName" BO_ 2157314309 "RZCU_20ms_PDU06";
BA_ "VFrameFormat" BO_ 2157314309 15;
BA_ "FrameTriggeringName" BO_ 2157314311 "RZCU_PTCANFD_20ms_ConFrP06__RZCU_20ms_PDU07";
BA_ "GenMsgCycleTime" BO_ 2157314311 20;
BA_ "GenMsgSendType" BO_ 2157314311 1;
BA_ "PduName" BO_ 2157314311 "RZCU_20ms_PDU07";
BA_ "VFrameFormat" BO_ 2157314311 15;
BA_ "FrameTriggeringName" BO_ 2148098050 "RZCU_SFCANFD_10ms_ConFrP08__RZCU_10ms_PDU01";
BA_ "GenMsgCycleTime" BO_ 2148098050 10;
BA_ "GenMsgSendType" BO_ 2148098050 1;
BA_ "PduName" BO_ 2148098050 "RZCU_10ms_PDU01";
BA_ "VFrameFormat" BO_ 2148098050 15;
BA_ "FrameTriggeringName" BO_ 2148098064 "RZCU_SFCANFD_10ms_ConFrP08__RZCU_10ms_PDU02";
BA_ "GenMsgCycleTime" BO_ 2148098064 10;
BA_ "GenMsgSendType" BO_ 2148098064 1;
BA_ "PduName" BO_ 2148098064 "RZCU_10ms_PDU02";
BA_ "VFrameFormat" BO_ 2148098064 15;
BA_ "CompuMethodName" SG_ 172 RZCU_10ms_Group90_CRC "RZCU_10ms_Group90_CRC";
BA_ "ISignalName" SG_ 172 RZCU_10ms_Group90_CRC "IRZCU_10ms_Group90_CRC";
BA_ "SysSignalName" SG_ 172 RZCU_10ms_Group90_CRC "RZCU_10ms_Group90_CRC";
BA_ "CompuMethodName" SG_ 172 RZCU_10ms_Group90_RC "RZCU_10ms_Group90_RC";
BA_ "ISignalName" SG_ 172 RZCU_10ms_Group90_RC "IRZCU_10ms_Group90_RC";
BA_ "SysSignalName" SG_ 172 RZCU_10ms_Group90_RC "RZCU_10ms_Group90_RC";
BA_ "CompuMethodName" SG_ 172 RZCU_10ms_Group90_Reserved15 "RZCU_10ms_Group90_Reserved15";
BA_ "GenSigStartValue" SG_ 172 RZCU_10ms_Group90_Reserved15 15;
BA_ "ISignalName" SG_ 172 RZCU_10ms_Group90_Reserved15 "IRZCU_10ms_Group90_Reserved15";
BA_ "SysSignalName" SG_ 172 RZCU_10ms_Group90_Reserved15 "RZCU_10ms_Group90_Reserved15";
BA_ "CompuMethodName" SG_ 172 RZCU_10ms_Group90_Reserved23 "RZCU_10ms_Group90_Reserved23";
BA_ "GenSigStartValue" SG_ 172 RZCU_10ms_Group90_Reserved23 255;
BA_ "ISignalName" SG_ 172 RZCU_10ms_Group90_Reserved23 "IRZCU_10ms_Group90_Reserved23";
BA_ "SysSignalName" SG_ 172 RZCU_10ms_Group90_Reserved23 "RZCU_10ms_Group90_Reserved23";
BA_ "CompuMethodName" SG_ 172 RZCU_10ms_Group90_Reserved31 "RZCU_10ms_Group90_Reserved31";
BA_ "GenSigStartValue" SG_ 172 RZCU_10ms_Group90_Reserved31 255;
BA_ "ISignalName" SG_ 172 RZCU_10ms_Group90_Reserved31 "IRZCU_10ms_Group90_Reserved31";
BA_ "SysSignalName" SG_ 172 RZCU_10ms_Group90_Reserved31 "RZCU_10ms_Group90_Reserved31";
BA_ "CompuMethodName" SG_ 172 RZCU_10ms_Group90_Reserved39 "RZCU_10ms_Group90_Reserved39";
BA_ "GenSigStartValue" SG_ 172 RZCU_10ms_Group90_Reserved39 255;
BA_ "ISignalName" SG_ 172 RZCU_10ms_Group90_Reserved39 "IRZCU_10ms_Group90_Reserved39";
BA_ "SysSignalName" SG_ 172 RZCU_10ms_Group90_Reserved39 "RZCU_10ms_Group90_Reserved39";
BA_ "CompuMethodName" SG_ 172 RZCU_10ms_Group90_Reserved47 "RZCU_10ms_Group90_Reserved47";
BA_ "GenSigStartValue" SG_ 172 RZCU_10ms_Group90_Reserved47 255;
BA_ "ISignalName" SG_ 172 RZCU_10ms_Group90_Reserved47 "IRZCU_10ms_Group90_Reserved47";
BA_ "SysSignalName" SG_ 172 RZCU_10ms_Group90_Reserved47 "RZCU_10ms_Group90_Reserved47";
BA_ "CompuMethodName" SG_ 172 RZCU_10ms_Group90_Reserved55 "RZCU_10ms_Group90_Reserved55";
BA_ "GenSigStartValue" SG_ 172 RZCU_10ms_Group90_Reserved55 255;
BA_ "ISignalName" SG_ 172 RZCU_10ms_Group90_Reserved55 "IRZCU_10ms_Group90_Reserved55";
BA_ "SysSignalName" SG_ 172 RZCU_10ms_Group90_Reserved55 "RZCU_10ms_Group90_Reserved55";
BA_ "CompuMethodName" SG_ 172 RZCU_10ms_Group90_Reserved63 "RZCU_10ms_Group90_Reserved63";
BA_ "GenSigStartValue" SG_ 172 RZCU_10ms_Group90_Reserved63 255;
BA_ "ISignalName" SG_ 172 RZCU_10ms_Group90_Reserved63 "IRZCU_10ms_Group90_Reserved63";
BA_ "SysSignalName" SG_ 172 RZCU_10ms_Group90_Reserved63 "RZCU_10ms_Group90_Reserved63";
BA_ "CompuMethodName" SG_ 172 RZCU_10ms_Group90_Reserved71 "RZCU_10ms_Group90_Reserved71";
BA_ "GenSigStartValue" SG_ 172 RZCU_10ms_Group90_Reserved71 255;
BA_ "ISignalName" SG_ 172 RZCU_10ms_Group90_Reserved71 "IRZCU_10ms_Group90_Reserved71";
BA_ "SysSignalName" SG_ 172 RZCU_10ms_Group90_Reserved71 "RZCU_10ms_Group90_Reserved71";
BA_ "CompuMethodName" SG_ 172 RZCU_10ms_Group90_Reserved79 "RZCU_10ms_Group90_Reserved79";
BA_ "GenSigStartValue" SG_ 172 RZCU_10ms_Group90_Reserved79 255;
BA_ "ISignalName" SG_ 172 RZCU_10ms_Group90_Reserved79 "IRZCU_10ms_Group90_Reserved79";
BA_ "SysSignalName" SG_ 172 RZCU_10ms_Group90_Reserved79 "RZCU_10ms_Group90_Reserved79";
BA_ "CompuMethodName" SG_ 172 RZCU_10ms_Group90_Reserved83 "RZCU_10ms_Group90_Reserved83";
BA_ "GenSigStartValue" SG_ 172 RZCU_10ms_Group90_Reserved83 15;
BA_ "ISignalName" SG_ 172 RZCU_10ms_Group90_Reserved83 "IRZCU_10ms_Group90_Reserved83";
BA_ "SysSignalName" SG_ 172 RZCU_10ms_Group90_Reserved83 "RZCU_10ms_Group90_Reserved83";
BA_ "CompuMethodName" SG_ 172 VCU_ISAOvSpdOvRd "VCU_ISAOvSpdOvRd";
BA_ "ISignalName" SG_ 172 VCU_ISAOvSpdOvRd "IVCU_ISAOvSpdOvRd";
BA_ "LongName" SG_ 172 VCU_ISAOvSpdOvRd "VCU_Intelligence_Speed_Assist_Overspeed_Override";
BA_ "SysSignalName" SG_ 172 VCU_ISAOvSpdOvRd "VCU_ISAOvSpdOvRd";
BA_ "CompuMethodName" SG_ 172 RZCU_10ms_Group90_Reserved87 "RZCU_10ms_Group90_Reserved87";
BA_ "GenSigStartValue" SG_ 172 RZCU_10ms_Group90_Reserved87 3;
BA_ "ISignalName" SG_ 172 RZCU_10ms_Group90_Reserved87 "IRZCU_10ms_Group90_Reserved87";
BA_ "SysSignalName" SG_ 172 RZCU_10ms_Group90_Reserved87 "RZCU_10ms_Group90_Reserved87";
BA_ "CompuMethodName" SG_ 172 RZCU_10ms_Group90_Reserved95 "RZCU_10ms_Group90_Reserved95";
BA_ "GenSigStartValue" SG_ 172 RZCU_10ms_Group90_Reserved95 255;
BA_ "ISignalName" SG_ 172 RZCU_10ms_Group90_Reserved95 "IRZCU_10ms_Group90_Reserved95";
BA_ "SysSignalName" SG_ 172 RZCU_10ms_Group90_Reserved95 "RZCU_10ms_Group90_Reserved95";
BA_ "CompuMethodName" SG_ 172 RZCU_10ms_Group90_Reserved103 "RZCU_10ms_Group90_Reserved103";
BA_ "GenSigStartValue" SG_ 172 RZCU_10ms_Group90_Reserved103 255;
BA_ "ISignalName" SG_ 172 RZCU_10ms_Group90_Reserved103 "IRZCU_10ms_Group90_Reserved103";
BA_ "SysSignalName" SG_ 172 RZCU_10ms_Group90_Reserved103 "RZCU_10ms_Group90_Reserved103";
BA_ "CompuMethodName" SG_ 172 RZCU_10ms_Group90_Reserved111 "RZCU_10ms_Group90_Reserved111";
BA_ "GenSigStartValue" SG_ 172 RZCU_10ms_Group90_Reserved111 255;
BA_ "ISignalName" SG_ 172 RZCU_10ms_Group90_Reserved111 "IRZCU_10ms_Group90_Reserved111";
BA_ "SysSignalName" SG_ 172 RZCU_10ms_Group90_Reserved111 "RZCU_10ms_Group90_Reserved111";
BA_ "CompuMethodName" SG_ 172 RZCU_10ms_Group90_Reserved119 "RZCU_10ms_Group90_Reserved119";
BA_ "GenSigStartValue" SG_ 172 RZCU_10ms_Group90_Reserved119 255;
BA_ "ISignalName" SG_ 172 RZCU_10ms_Group90_Reserved119 "IRZCU_10ms_Group90_Reserved119";
BA_ "SysSignalName" SG_ 172 RZCU_10ms_Group90_Reserved119 "RZCU_10ms_Group90_Reserved119";
BA_ "CompuMethodName" SG_ 172 RZCU_10ms_Group90_Reserved127 "RZCU_10ms_Group90_Reserved127";
BA_ "GenSigStartValue" SG_ 172 RZCU_10ms_Group90_Reserved127 255;
BA_ "ISignalName" SG_ 172 RZCU_10ms_Group90_Reserved127 "IRZCU_10ms_Group90_Reserved127";
BA_ "SysSignalName" SG_ 172 RZCU_10ms_Group90_Reserved127 "RZCU_10ms_Group90_Reserved127";
BA_ "CompuMethodName" SG_ 172 RZCU_10ms_Group90_Reserved135 "RZCU_10ms_Group90_Reserved135";
BA_ "GenSigStartValue" SG_ 172 RZCU_10ms_Group90_Reserved135 255;
BA_ "ISignalName" SG_ 172 RZCU_10ms_Group90_Reserved135 "IRZCU_10ms_Group90_Reserved135";
BA_ "SysSignalName" SG_ 172 RZCU_10ms_Group90_Reserved135 "RZCU_10ms_Group90_Reserved135";
BA_ "CompuMethodName" SG_ 172 RZCU_10ms_Group90_Reserved143 "RZCU_10ms_Group90_Reserved143";
BA_ "GenSigStartValue" SG_ 172 RZCU_10ms_Group90_Reserved143 255;
BA_ "ISignalName" SG_ 172 RZCU_10ms_Group90_Reserved143 "IRZCU_10ms_Group90_Reserved143";
BA_ "SysSignalName" SG_ 172 RZCU_10ms_Group90_Reserved143 "RZCU_10ms_Group90_Reserved143";
BA_ "CompuMethodName" SG_ 172 RZCU_10ms_Group90_Reserved151 "RZCU_10ms_Group90_Reserved151";
BA_ "GenSigStartValue" SG_ 172 RZCU_10ms_Group90_Reserved151 255;
BA_ "ISignalName" SG_ 172 RZCU_10ms_Group90_Reserved151 "IRZCU_10ms_Group90_Reserved151";
BA_ "SysSignalName" SG_ 172 RZCU_10ms_Group90_Reserved151 "RZCU_10ms_Group90_Reserved151";
BA_ "CompuMethodName" SG_ 172 RZCU_10ms_Group90_Reserved159 "RZCU_10ms_Group90_Reserved159";
BA_ "GenSigStartValue" SG_ 172 RZCU_10ms_Group90_Reserved159 255;
BA_ "ISignalName" SG_ 172 RZCU_10ms_Group90_Reserved159 "IRZCU_10ms_Group90_Reserved159";
BA_ "SysSignalName" SG_ 172 RZCU_10ms_Group90_Reserved159 "RZCU_10ms_Group90_Reserved159";
BA_ "CompuMethodName" SG_ 1267 RZCU_NM_BSMtoRMS_PTCANFD "RZCU_NM_BSMtoRMS_PTCANFD";
BA_ "ISignalName" SG_ 1267 RZCU_NM_BSMtoRMS_PTCANFD "IRZCU_NM_BSMtoRMS_PTCANFD";
BA_ "SysSignalName" SG_ 1267 RZCU_NM_BSMtoRMS_PTCANFD "RZCU_NM_BSMtoRMS_PTCANFD";
BA_ "CompuMethodName" SG_ 1267 RZCU_NM_PBSMtoRMS_PTCANFD "RZCU_NM_PBSMtoRMS_PTCANFD";
BA_ "ISignalName" SG_ 1267 RZCU_NM_PBSMtoRMS_PTCANFD "IRZCU_NM_PBSMtoRMS_PTCANFD";
BA_ "SysSignalName" SG_ 1267 RZCU_NM_PBSMtoRMS_PTCANFD "RZCU_NM_PBSMtoRMS_PTCANFD";
BA_ "CompuMethodName" SG_ 1267 RZCU_NM_RMStoNOS_PTCANFD "RZCU_NM_RMStoNOS_PTCANFD";
BA_ "ISignalName" SG_ 1267 RZCU_NM_RMStoNOS_PTCANFD "IRZCU_NM_RMStoNOS_PTCANFD";
BA_ "SysSignalName" SG_ 1267 RZCU_NM_RMStoNOS_PTCANFD "RZCU_NM_RMStoNOS_PTCANFD";
BA_ "CompuMethodName" SG_ 1267 RZCU_NM_RSStoNOS_PTCANFD "RZCU_NM_RSStoNOS_PTCANFD";
BA_ "ISignalName" SG_ 1267 RZCU_NM_RSStoNOS_PTCANFD "IRZCU_NM_RSStoNOS_PTCANFD";
BA_ "SysSignalName" SG_ 1267 RZCU_NM_RSStoNOS_PTCANFD "RZCU_NM_RSStoNOS_PTCANFD";
BA_ "CompuMethodName" SG_ 1267 RZCU_NM_RSStoRMS_PTCANFD "RZCU_NM_RSStoRMS_PTCANFD";
BA_ "ISignalName" SG_ 1267 RZCU_NM_RSStoRMS_PTCANFD "IRZCU_NM_RSStoRMS_PTCANFD";
BA_ "SysSignalName" SG_ 1267 RZCU_NM_RSStoRMS_PTCANFD "RZCU_NM_RSStoRMS_PTCANFD";
BA_ "CompuMethodName" SG_ 1267 RZCU_NM_NOStoRMS_PTCANFD "RZCU_NM_NOStoRMS_PTCANFD";
BA_ "ISignalName" SG_ 1267 RZCU_NM_NOStoRMS_PTCANFD "IRZCU_NM_NOStoRMS_PTCANFD";
BA_ "SysSignalName" SG_ 1267 RZCU_NM_NOStoRMS_PTCANFD "RZCU_NM_NOStoRMS_PTCANFD";
BA_ "CompuMethodName" SG_ 1267 RZCU_NM_NOSSta_PTCANFD "RZCU_NM_NOSSta_PTCANFD";
BA_ "ISignalName" SG_ 1267 RZCU_NM_NOSSta_PTCANFD "IRZCU_NM_NOSSta_PTCANFD";
BA_ "SysSignalName" SG_ 1267 RZCU_NM_NOSSta_PTCANFD "RZCU_NM_NOSSta_PTCANFD";
BA_ "CompuMethodName" SG_ 1267 RZCU_NM_RMSSta_PTCANFD "RZCU_NM_RMSSta_PTCANFD";
BA_ "ISignalName" SG_ 1267 RZCU_NM_RMSSta_PTCANFD "IRZCU_NM_RMSSta_PTCANFD";
BA_ "SysSignalName" SG_ 1267 RZCU_NM_RMSSta_PTCANFD "RZCU_NM_RMSSta_PTCANFD";
BA_ "CompuMethodName" SG_ 1267 RZCU_NWI_PTCANFD "RZCU_NWI_PTCANFD";
BA_ "ISignalName" SG_ 1267 RZCU_NWI_PTCANFD "IRZCU_NWI_PTCANFD";
BA_ "LongName" SG_ 1267 RZCU_NWI_PTCANFD "RZCU Network Wakeup Indication";
BA_ "SysSignalName" SG_ 1267 RZCU_NWI_PTCANFD "RZCU_NWI_PTCANFD";
BA_ "CompuMethodName" SG_ 1267 RZCU_NOI_PTCANFD "RZCU_NOI_PTCANFD";
BA_ "ISignalName" SG_ 1267 RZCU_NOI_PTCANFD "IRZCU_NOI_PTCANFD";
BA_ "SysSignalName" SG_ 1267 RZCU_NOI_PTCANFD "RZCU_NOI_PTCANFD";
BA_ "CompuMethodName" SG_ 1267 RZCU_NKI_PTCANFD "RZCU_NKI_PTCANFD";
BA_ "ISignalName" SG_ 1267 RZCU_NKI_PTCANFD "IRZCU_NKI_PTCANFD";
BA_ "LongName" SG_ 1267 RZCU_NKI_PTCANFD "RZCU Network Keep Indication";
BA_ "SysSignalName" SG_ 1267 RZCU_NKI_PTCANFD "RZCU_NKI_PTCANFD";
BA_ "CompuMethodName" SG_ 1611 IMU_SN "IMU_SN";
BA_ "ISignalName" SG_ 1611 IMU_SN "IIMU_SN";
BA_ "LongName" SG_ 1611 IMU_SN "IMU Serial Number";
BA_ "SysSignalName" SG_ 1611 IMU_SN "IMU_SN";
BA_ "CompuMethodName" SG_ 247 RZCU_10ms_Group22_CRC "RZCU_10ms_Group22_CRC";
BA_ "ISignalName" SG_ 247 RZCU_10ms_Group22_CRC "IRZCU_10ms_Group22_CRC";
BA_ "LongName" SG_ 247 RZCU_10ms_Group22_CRC "RZCU_10ms_Group22_CRC";
BA_ "SysSignalName" SG_ 247 RZCU_10ms_Group22_CRC "RZCU_10ms_Group22_CRC";
BA_ "CompuMethodName" SG_ 247 RZCU_10ms_Group22_RC "RZCU_10ms_Group22_RC";
BA_ "ISignalName" SG_ 247 RZCU_10ms_Group22_RC "IRZCU_10ms_Group22_RC";
BA_ "LongName" SG_ 247 RZCU_10ms_Group22_RC "RZCU_10ms_Group22_RC";
BA_ "SysSignalName" SG_ 247 RZCU_10ms_Group22_RC "RZCU_10ms_Group22_RC";
BA_ "CompuMethodName" SG_ 247 VMCTarWhlTqMaxLmtV "VMCTarWhlTqMaxLmtV";
BA_ "GenSigStartValue" SG_ 247 VMCTarWhlTqMaxLmtV 1;
BA_ "ISignalName" SG_ 247 VMCTarWhlTqMaxLmtV "IVMCTarWhlTqMaxLmtV";
BA_ "LongName" SG_ 247 VMCTarWhlTqMaxLmtV "Vehicle Motion Control Target Wheel Torque Maximum Limit Validity";
BA_ "SysSignalName" SG_ 247 VMCTarWhlTqMaxLmtV "VMCTarWhlTqMaxLmtV";
BA_ "CompuMethodName" SG_ 247 VMCTarReWhlTqMaxLmtV "VMCTarReWhlTqMaxLmtV";
BA_ "GenSigStartValue" SG_ 247 VMCTarReWhlTqMaxLmtV 1;
BA_ "ISignalName" SG_ 247 VMCTarReWhlTqMaxLmtV "IVMCTarReWhlTqMaxLmtV";
BA_ "LongName" SG_ 247 VMCTarReWhlTqMaxLmtV "Vehicle Motion Control Target Rear Wheel Torque  Maximum Limit Validity";
BA_ "SysSignalName" SG_ 247 VMCTarReWhlTqMaxLmtV "VMCTarReWhlTqMaxLmtV";
BA_ "CompuMethodName" SG_ 247 EPTTrOtptShaftTotMinAvlblToqV "EPTTrOtptShaftTotMinAvlblToqV";
BA_ "ISignalName" SG_ 247 EPTTrOtptShaftTotMinAvlblToqV "IEPTTrOtptShaftTotMinAvlblToqV";
BA_ "LongName" SG_ 247 EPTTrOtptShaftTotMinAvlblToqV "Electric_Powertrain_Transmission_Output_Shaft_Total_Minimum_Available_Torque_Validity";
BA_ "SysSignalName" SG_ 247 EPTTrOtptShaftTotMinAvlblToqV "EPTTrOtptShaftTotMinAvlblToqV";
BA_ "CompuMethodName" SG_ 247 EPTTrOtptShaftTotMaxAvlblToqV "EPTTrOtptShaftTotMaxAvlblToqV";
BA_ "ISignalName" SG_ 247 EPTTrOtptShaftTotMaxAvlblToqV "IEPTTrOtptShaftTotMaxAvlblToqV";
BA_ "LongName" SG_ 247 EPTTrOtptShaftTotMaxAvlblToqV "Electric_Powertrain_Transmission_Output_Shaft_Total_Maximum_Available_Torque_Validity";
BA_ "SysSignalName" SG_ 247 EPTTrOtptShaftTotMaxAvlblToqV "EPTTrOtptShaftTotMaxAvlblToqV";
BA_ "CompuMethodName" SG_ 247 EPTTrOtptShaftTotMaxAvlblToq "EPTTrOtptShaftTotMaxAvlblToq";
BA_ "GenSigStartValue" SG_ 247 EPTTrOtptShaftTotMaxAvlblToq 1696;
BA_ "ISignalName" SG_ 247 EPTTrOtptShaftTotMaxAvlblToq "IEPTTrOtptShaftTotMaxAvlblToq";
BA_ "LongName" SG_ 247 EPTTrOtptShaftTotMaxAvlblToq "Electric_Powertrain_Transmission_Output_Shaft_Total_Maximum_Available_Torque";
BA_ "SysSignalName" SG_ 247 EPTTrOtptShaftTotMaxAvlblToq "EPTTrOtptShaftTotMaxAvlblToq";
BA_ "CompuMethodName" SG_ 247 EPTTrOtptShaftTotMinAvlblToq "EPTTrOtptShaftTotMinAvlblToq";
BA_ "ISignalName" SG_ 247 EPTTrOtptShaftTotMinAvlblToq "IEPTTrOtptShaftTotMinAvlblToq";
BA_ "LongName" SG_ 247 EPTTrOtptShaftTotMinAvlblToq "Electric_Powertrain_Transmission_Output_Shaft_Total_Minimum_Available_Torque";
BA_ "SysSignalName" SG_ 247 EPTTrOtptShaftTotMinAvlblToq "EPTTrOtptShaftTotMinAvlblToq";
BA_ "CompuMethodName" SG_ 247 EPTTrOtptShaftTotToq "EPTTrOtptShaftTotToq";
BA_ "ISignalName" SG_ 247 EPTTrOtptShaftTotToq "IEPTTrOtptShaftTotToq";
BA_ "LongName" SG_ 247 EPTTrOtptShaftTotToq "Electric_Powertrain_Transmission_Output_Shaft_Total_Torque";
BA_ "SysSignalName" SG_ 247 EPTTrOtptShaftTotToq "EPTTrOtptShaftTotToq";
BA_ "CompuMethodName" SG_ 247 EPTTrOtptShaftTotToqV "EPTTrOtptShaftTotToqV";
BA_ "GenSigStartValue" SG_ 247 EPTTrOtptShaftTotToqV 1;
BA_ "ISignalName" SG_ 247 EPTTrOtptShaftTotToqV "IEPTTrOtptShaftTotToqV";
BA_ "LongName" SG_ 247 EPTTrOtptShaftTotToqV "Electric_Powertrain_Transmission_Output_Shaft_Total_Torque_Validity";
BA_ "SysSignalName" SG_ 247 EPTTrOtptShaftTotToqV "EPTTrOtptShaftTotToqV";
BA_ "CompuMethodName" SG_ 247 RZCU_10ms_Group22_Reserved47 "RZCU_10ms_Group22_Reserved47";
BA_ "GenSigStartValue" SG_ 247 RZCU_10ms_Group22_Reserved47 7;
BA_ "ISignalName" SG_ 247 RZCU_10ms_Group22_Reserved47 "IRZCU_10ms_Group22_Reserved47";
BA_ "SysSignalName" SG_ 247 RZCU_10ms_Group22_Reserved47 "RZCU_10ms_Group22_Reserved47";
BA_ "CompuMethodName" SG_ 247 VMCTarWhlTqMaxLmt "VMCTarWhlTqMaxLmt";
BA_ "GenSigStartValue" SG_ 247 VMCTarWhlTqMaxLmt 32767;
BA_ "ISignalName" SG_ 247 VMCTarWhlTqMaxLmt "IVMCTarWhlTqMaxLmt";
BA_ "LongName" SG_ 247 VMCTarWhlTqMaxLmt "Vehicle Motion Control Target Wheel Torque Maximum Limit";
BA_ "SysSignalName" SG_ 247 VMCTarWhlTqMaxLmt "VMCTarWhlTqMaxLmt";
BA_ "CompuMethodName" SG_ 247 VMCTarReWhlTqMaxLmt "VMCTarReWhlTqMaxLmt";
BA_ "GenSigStartValue" SG_ 247 VMCTarReWhlTqMaxLmt 32767;
BA_ "ISignalName" SG_ 247 VMCTarReWhlTqMaxLmt "IVMCTarReWhlTqMaxLmt";
BA_ "LongName" SG_ 247 VMCTarReWhlTqMaxLmt "Vehicle Motion Control Target Rear Wheel Torque Maximum Limit";
BA_ "SysSignalName" SG_ 247 VMCTarReWhlTqMaxLmt "VMCTarReWhlTqMaxLmt";
BA_ "CompuMethodName" SG_ 247 RZCU_10ms_Group22_Reserved95 "RZCU_10ms_Group22_Reserved95";
BA_ "GenSigStartValue" SG_ 247 RZCU_10ms_Group22_Reserved95 255;
BA_ "ISignalName" SG_ 247 RZCU_10ms_Group22_Reserved95 "IRZCU_10ms_Group22_Reserved95";
BA_ "SysSignalName" SG_ 247 RZCU_10ms_Group22_Reserved95 "RZCU_10ms_Group22_Reserved95";
BA_ "CompuMethodName" SG_ 225 RZCU_10ms_Group23_CRC "RZCU_10ms_Group23_CRC";
BA_ "ISignalName" SG_ 225 RZCU_10ms_Group23_CRC "IRZCU_10ms_Group23_CRC";
BA_ "LongName" SG_ 225 RZCU_10ms_Group23_CRC "RZCU_10ms_Group23_CRC";
BA_ "SysSignalName" SG_ 225 RZCU_10ms_Group23_CRC "RZCU_10ms_Group23_CRC";
BA_ "CompuMethodName" SG_ 225 RZCU_10ms_Group23_RC "RZCU_10ms_Group23_RC";
BA_ "ISignalName" SG_ 225 RZCU_10ms_Group23_RC "IRZCU_10ms_Group23_RC";
BA_ "LongName" SG_ 225 RZCU_10ms_Group23_RC "RZCU_10ms_Group23_RC";
BA_ "SysSignalName" SG_ 225 RZCU_10ms_Group23_RC "RZCU_10ms_Group23_RC";
BA_ "CompuMethodName" SG_ 225 RZCU_10ms_Group23_Reserved1 "RZCU_10ms_Group23_Reserved1";
BA_ "GenSigStartValue" SG_ 225 RZCU_10ms_Group23_Reserved1 1;
BA_ "ISignalName" SG_ 225 RZCU_10ms_Group23_Reserved1 "IRZCU_10ms_Group23_Reserved1";
BA_ "SysSignalName" SG_ 225 RZCU_10ms_Group23_Reserved1 "RZCU_10ms_Group23_Reserved1";
BA_ "CompuMethodName" SG_ 225 PtAPAToqReqResp "PtAPAToqReqResp";
BA_ "ISignalName" SG_ 225 PtAPAToqReqResp "IPtAPAToqReqResp";
BA_ "LongName" SG_ 225 PtAPAToqReqResp "Powertrain Advanced Park Assist Torque Request Response";
BA_ "SysSignalName" SG_ 225 PtAPAToqReqResp "PtAPAToqReqResp";
BA_ "CompuMethodName" SG_ 225 RZCU_10ms_Group23_Reserved3 "RZCU_10ms_Group23_Reserved3";
BA_ "GenSigStartValue" SG_ 225 RZCU_10ms_Group23_Reserved3 7;
BA_ "ISignalName" SG_ 225 RZCU_10ms_Group23_Reserved3 "IRZCU_10ms_Group23_Reserved3";
BA_ "SysSignalName" SG_ 225 RZCU_10ms_Group23_Reserved3 "RZCU_10ms_Group23_Reserved3";
BA_ "CompuMethodName" SG_ 225 AutodDrvngToqReqResp "AutodDrvngToqReqResp";
BA_ "ISignalName" SG_ 225 AutodDrvngToqReqResp "IAutodDrvngToqReqResp";
BA_ "LongName" SG_ 225 AutodDrvngToqReqResp "Automated_Driving_Torque_Request_Response";
BA_ "SysSignalName" SG_ 225 AutodDrvngToqReqResp "AutodDrvngToqReqResp";
BA_ "CompuMethodName" SG_ 225 RZCU_10ms_Group23_Reserved2 "RZCU_10ms_Group23_Reserved2";
BA_ "GenSigStartValue" SG_ 225 RZCU_10ms_Group23_Reserved2 3;
BA_ "ISignalName" SG_ 225 RZCU_10ms_Group23_Reserved2 "IRZCU_10ms_Group23_Reserved2";
BA_ "SysSignalName" SG_ 225 RZCU_10ms_Group23_Reserved2 "RZCU_10ms_Group23_Reserved2";
BA_ "CompuMethodName" SG_ 225 RZCU_10ms_Group23_Reserved4 "RZCU_10ms_Group23_Reserved4";
BA_ "GenSigStartValue" SG_ 225 RZCU_10ms_Group23_Reserved4 31;
BA_ "ISignalName" SG_ 225 RZCU_10ms_Group23_Reserved4 "IRZCU_10ms_Group23_Reserved4";
BA_ "SysSignalName" SG_ 225 RZCU_10ms_Group23_Reserved4 "RZCU_10ms_Group23_Reserved4";
BA_ "CompuMethodName" SG_ 225 PtACCToqReqResp "PtACCToqReqResp";
BA_ "ISignalName" SG_ 225 PtACCToqReqResp "IPtACCToqReqResp";
BA_ "LongName" SG_ 225 PtACCToqReqResp "Powertrain_Adaptive_Cruise_Control_Torque_Request_Response";
BA_ "SysSignalName" SG_ 225 PtACCToqReqResp "PtACCToqReqResp";
BA_ "CompuMethodName" SG_ 225 AIPilotSysSaBrSts "AIPilotSysSaBrSts";
BA_ "ISignalName" SG_ 225 AIPilotSysSaBrSts "IAIPilotSysSaBrSts";
BA_ "LongName" SG_ 225 AIPilotSysSaBrSts "Ai Pilot Control System High Level Safety Braking Status";
BA_ "SysSignalName" SG_ 225 AIPilotSysSaBrSts "AIPilotSysSaBrSts";
BA_ "CompuMethodName" SG_ 225 AIPilotSysSaBrInh "AIPilotSysSaBrInh";
BA_ "ISignalName" SG_ 225 AIPilotSysSaBrInh "IAIPilotSysSaBrInh";
BA_ "LongName" SG_ 225 AIPilotSysSaBrInh "Ai Pilot Control System High Level Safety Braking Fault Inhibit Reason";
BA_ "SysSignalName" SG_ 225 AIPilotSysSaBrInh "AIPilotSysSaBrInh";
BA_ "CompuMethodName" SG_ 225 RZCU_10ms_Group23_Reserved5 "RZCU_10ms_Group23_Reserved5";
BA_ "GenSigStartValue" SG_ 225 RZCU_10ms_Group23_Reserved5 255;
BA_ "ISignalName" SG_ 225 RZCU_10ms_Group23_Reserved5 "IRZCU_10ms_Group23_Reserved5";
BA_ "SysSignalName" SG_ 225 RZCU_10ms_Group23_Reserved5 "RZCU_10ms_Group23_Reserved5";
BA_ "CompuMethodName" SG_ 225 RZCU_10ms_Group23_Reserved6 "RZCU_10ms_Group23_Reserved6";
BA_ "GenSigStartValue" SG_ 225 RZCU_10ms_Group23_Reserved6 127;
BA_ "ISignalName" SG_ 225 RZCU_10ms_Group23_Reserved6 "IRZCU_10ms_Group23_Reserved6";
BA_ "SysSignalName" SG_ 225 RZCU_10ms_Group23_Reserved6 "RZCU_10ms_Group23_Reserved6";
BA_ "CompuMethodName" SG_ 225 AccelOvrd "AccelOvrd";
BA_ "ISignalName" SG_ 225 AccelOvrd "IAccelOvrd";
BA_ "LongName" SG_ 225 AccelOvrd "Accelerator_Override";
BA_ "SysSignalName" SG_ 225 AccelOvrd "AccelOvrd";
BA_ "CompuMethodName" SG_ 225 RZCU_10ms_Group23_Reserved7 "RZCU_10ms_Group23_Reserved7";
BA_ "GenSigStartValue" SG_ 225 RZCU_10ms_Group23_Reserved7 255;
BA_ "ISignalName" SG_ 225 RZCU_10ms_Group23_Reserved7 "IRZCU_10ms_Group23_Reserved7";
BA_ "SysSignalName" SG_ 225 RZCU_10ms_Group23_Reserved7 "RZCU_10ms_Group23_Reserved7";
BA_ "CompuMethodName" SG_ 225 RZCU_10ms_Group23_Reserved8 "RZCU_10ms_Group23_Reserved8";
BA_ "GenSigStartValue" SG_ 225 RZCU_10ms_Group23_Reserved8 255;
BA_ "ISignalName" SG_ 225 RZCU_10ms_Group23_Reserved8 "IRZCU_10ms_Group23_Reserved8";
BA_ "SysSignalName" SG_ 225 RZCU_10ms_Group23_Reserved8 "RZCU_10ms_Group23_Reserved8";
BA_ "CompuMethodName" SG_ 225 RZCU_10ms_Group23_Reserved9 "RZCU_10ms_Group23_Reserved9";
BA_ "GenSigStartValue" SG_ 225 RZCU_10ms_Group23_Reserved9 255;
BA_ "ISignalName" SG_ 225 RZCU_10ms_Group23_Reserved9 "IRZCU_10ms_Group23_Reserved9";
BA_ "SysSignalName" SG_ 225 RZCU_10ms_Group23_Reserved9 "RZCU_10ms_Group23_Reserved9";
BA_ "CompuMethodName" SG_ 225 RZCU_10ms_Group23_Reserved10 "RZCU_10ms_Group23_Reserved10";
BA_ "GenSigStartValue" SG_ 225 RZCU_10ms_Group23_Reserved10 255;
BA_ "ISignalName" SG_ 225 RZCU_10ms_Group23_Reserved10 "IRZCU_10ms_Group23_Reserved10";
BA_ "SysSignalName" SG_ 225 RZCU_10ms_Group23_Reserved10 "RZCU_10ms_Group23_Reserved10";
BA_ "CompuMethodName" SG_ 225 RZCU_10ms_Group23_Reserved11 "RZCU_10ms_Group23_Reserved11";
BA_ "GenSigStartValue" SG_ 225 RZCU_10ms_Group23_Reserved11 255;
BA_ "ISignalName" SG_ 225 RZCU_10ms_Group23_Reserved11 "IRZCU_10ms_Group23_Reserved11";
BA_ "SysSignalName" SG_ 225 RZCU_10ms_Group23_Reserved11 "RZCU_10ms_Group23_Reserved11";
BA_ "CompuMethodName" SG_ 225 RZCU_10ms_Group23_Reserved12 "RZCU_10ms_Group23_Reserved12";
BA_ "GenSigStartValue" SG_ 225 RZCU_10ms_Group23_Reserved12 255;
BA_ "ISignalName" SG_ 225 RZCU_10ms_Group23_Reserved12 "IRZCU_10ms_Group23_Reserved12";
BA_ "SysSignalName" SG_ 225 RZCU_10ms_Group23_Reserved12 "RZCU_10ms_Group23_Reserved12";
BA_ "CompuMethodName" SG_ 225 RZCU_10ms_Group23_Reserved13 "RZCU_10ms_Group23_Reserved13";
BA_ "GenSigStartValue" SG_ 225 RZCU_10ms_Group23_Reserved13 255;
BA_ "ISignalName" SG_ 225 RZCU_10ms_Group23_Reserved13 "IRZCU_10ms_Group23_Reserved13";
BA_ "SysSignalName" SG_ 225 RZCU_10ms_Group23_Reserved13 "RZCU_10ms_Group23_Reserved13";
BA_ "CompuMethodName" SG_ 225 RZCU_10ms_Group23_Reserved14 "RZCU_10ms_Group23_Reserved14";
BA_ "GenSigStartValue" SG_ 225 RZCU_10ms_Group23_Reserved14 255;
BA_ "ISignalName" SG_ 225 RZCU_10ms_Group23_Reserved14 "IRZCU_10ms_Group23_Reserved14";
BA_ "SysSignalName" SG_ 225 RZCU_10ms_Group23_Reserved14 "RZCU_10ms_Group23_Reserved14";
BA_ "CompuMethodName" SG_ 225 RZCU_10ms_Group23_Reserved15 "RZCU_10ms_Group23_Reserved15";
BA_ "GenSigStartValue" SG_ 225 RZCU_10ms_Group23_Reserved15 255;
BA_ "ISignalName" SG_ 225 RZCU_10ms_Group23_Reserved15 "IRZCU_10ms_Group23_Reserved15";
BA_ "SysSignalName" SG_ 225 RZCU_10ms_Group23_Reserved15 "RZCU_10ms_Group23_Reserved15";
BA_ "CompuMethodName" SG_ 201 RZCU_10ms_Group24_CRC "RZCU_10ms_Group24_CRC";
BA_ "ISignalName" SG_ 201 RZCU_10ms_Group24_CRC "IRZCU_10ms_Group24_CRC";
BA_ "LongName" SG_ 201 RZCU_10ms_Group24_CRC "RZCU_10ms_Group24_CRC";
BA_ "SysSignalName" SG_ 201 RZCU_10ms_Group24_CRC "RZCU_10ms_Group24_CRC";
BA_ "CompuMethodName" SG_ 201 RZCU_10ms_Group24_RC "RZCU_10ms_Group24_RC";
BA_ "ISignalName" SG_ 201 RZCU_10ms_Group24_RC "IRZCU_10ms_Group24_RC";
BA_ "LongName" SG_ 201 RZCU_10ms_Group24_RC "RZCU_10ms_Group24_RC";
BA_ "SysSignalName" SG_ 201 RZCU_10ms_Group24_RC "RZCU_10ms_Group24_RC";
BA_ "CompuMethodName" SG_ 201 RZCU_10ms_Group24_Reserved1 "RZCU_10ms_Group24_Reserved1";
BA_ "GenSigStartValue" SG_ 201 RZCU_10ms_Group24_Reserved1 1;
BA_ "ISignalName" SG_ 201 RZCU_10ms_Group24_Reserved1 "IRZCU_10ms_Group24_Reserved1";
BA_ "SysSignalName" SG_ 201 RZCU_10ms_Group24_Reserved1 "RZCU_10ms_Group24_Reserved1";
BA_ "CompuMethodName" SG_ 201 PtAPASts "PtAPASts";
BA_ "ISignalName" SG_ 201 PtAPASts "IPtAPASts";
BA_ "LongName" SG_ 201 PtAPASts "Powertrain APA Status";
BA_ "SysSignalName" SG_ 201 PtAPASts "PtAPASts";
BA_ "CompuMethodName" SG_ 201 VCUAPAUnderCtrlA "VCUAPAUnderCtrlA";
BA_ "ISignalName" SG_ 201 VCUAPAUnderCtrlA "IVCUAPAUnderCtrlA";
BA_ "LongName" SG_ 201 VCUAPAUnderCtrlA "VCU APA Under Control Active";
BA_ "SysSignalName" SG_ 201 VCUAPAUnderCtrlA "VCUAPAUnderCtrlA";
BA_ "CompuMethodName" SG_ 201 VCUAPAFltRsn "VCUAPAFltRsn";
BA_ "ISignalName" SG_ 201 VCUAPAFltRsn "IVCUAPAFltRsn";
BA_ "LongName" SG_ 201 VCUAPAFltRsn "VCU APA Fault Reason";
BA_ "SysSignalName" SG_ 201 VCUAPAFltRsn "VCUAPAFltRsn";
BA_ "CompuMethodName" SG_ 201 EPTAPARevrDrgReqResp "EPTAPARevrDrgReqResp";
BA_ "ISignalName" SG_ 201 EPTAPARevrDrgReqResp "IEPTAPARevrDrgReqResp";
BA_ "LongName" SG_ 201 EPTAPARevrDrgReqResp "EPT APA Reverse Drag Request Response";
BA_ "SysSignalName" SG_ 201 EPTAPARevrDrgReqResp "EPTAPARevrDrgReqResp";
BA_ "CompuMethodName" SG_ 201 RZCU_10ms_Group24_Reserved2 "RZCU_10ms_Group24_Reserved2";
BA_ "GenSigStartValue" SG_ 201 RZCU_10ms_Group24_Reserved2 255;
BA_ "ISignalName" SG_ 201 RZCU_10ms_Group24_Reserved2 "IRZCU_10ms_Group24_Reserved2";
BA_ "SysSignalName" SG_ 201 RZCU_10ms_Group24_Reserved2 "RZCU_10ms_Group24_Reserved2";
BA_ "CompuMethodName" SG_ 201 RZCU_10ms_Group24_Reserved3 "RZCU_10ms_Group24_Reserved3";
BA_ "GenSigStartValue" SG_ 201 RZCU_10ms_Group24_Reserved3 255;
BA_ "ISignalName" SG_ 201 RZCU_10ms_Group24_Reserved3 "IRZCU_10ms_Group24_Reserved3";
BA_ "SysSignalName" SG_ 201 RZCU_10ms_Group24_Reserved3 "RZCU_10ms_Group24_Reserved3";
BA_ "CompuMethodName" SG_ 201 RZCU_10ms_Group24_Reserved4 "RZCU_10ms_Group24_Reserved4";
BA_ "GenSigStartValue" SG_ 201 RZCU_10ms_Group24_Reserved4 255;
BA_ "ISignalName" SG_ 201 RZCU_10ms_Group24_Reserved4 "IRZCU_10ms_Group24_Reserved4";
BA_ "SysSignalName" SG_ 201 RZCU_10ms_Group24_Reserved4 "RZCU_10ms_Group24_Reserved4";
BA_ "CompuMethodName" SG_ 201 RZCU_10ms_Group24_Reserved5 "RZCU_10ms_Group24_Reserved5";
BA_ "GenSigStartValue" SG_ 201 RZCU_10ms_Group24_Reserved5 255;
BA_ "ISignalName" SG_ 201 RZCU_10ms_Group24_Reserved5 "IRZCU_10ms_Group24_Reserved5";
BA_ "SysSignalName" SG_ 201 RZCU_10ms_Group24_Reserved5 "RZCU_10ms_Group24_Reserved5";
BA_ "CompuMethodName" SG_ 201 RZCU_10ms_Group24_Reserved6 "RZCU_10ms_Group24_Reserved6";
BA_ "GenSigStartValue" SG_ 201 RZCU_10ms_Group24_Reserved6 255;
BA_ "ISignalName" SG_ 201 RZCU_10ms_Group24_Reserved6 "IRZCU_10ms_Group24_Reserved6";
BA_ "SysSignalName" SG_ 201 RZCU_10ms_Group24_Reserved6 "RZCU_10ms_Group24_Reserved6";
BA_ "CompuMethodName" SG_ 517 RZCUeSw10Sts "RZCUeSw10Sts";
BA_ "ISignalName" SG_ 517 RZCUeSw10Sts "IRZCUeSw10Sts";
BA_ "LongName" SG_ 517 RZCUeSw10Sts "RZCU eSwitch10 Status";
BA_ "SysSignalName" SG_ 517 RZCUeSw10Sts "RZCUeSw10Sts";
BA_ "CompuMethodName" SG_ 517 RZCUeSw10DiagSts "RZCUeSw10DiagSts";
BA_ "ISignalName" SG_ 517 RZCUeSw10DiagSts "IRZCUeSw10DiagSts";
BA_ "LongName" SG_ 517 RZCUeSw10DiagSts "RZCU eSwitch10 Diagnostic Status";
BA_ "SysSignalName" SG_ 517 RZCUeSw10DiagSts "RZCUeSw10DiagSts";
BA_ "CompuMethodName" SG_ 517 RZCUIgnSts "RZCUIgnSts";
BA_ "ISignalName" SG_ 517 RZCUIgnSts "IRZCUIgnSts";
BA_ "LongName" SG_ 517 RZCUIgnSts "RZCU Ignition Status";
BA_ "SysSignalName" SG_ 517 RZCUIgnSts "RZCUIgnSts";
BA_ "CompuMethodName" SG_ 517 RZCUIgnDiagSts "RZCUIgnDiagSts";
BA_ "ISignalName" SG_ 517 RZCUIgnDiagSts "IRZCUIgnDiagSts";
BA_ "LongName" SG_ 517 RZCUIgnDiagSts "RZCU Ignition Diagnostic Status";
BA_ "SysSignalName" SG_ 517 RZCUIgnDiagSts "RZCUIgnDiagSts";
BA_ "CompuMethodName" SG_ 517 RZCUeFs3Sts "RZCUeFs3Sts";
BA_ "ISignalName" SG_ 517 RZCUeFs3Sts "IRZCUeFs3Sts";
BA_ "LongName" SG_ 517 RZCUeFs3Sts "RZCU eFuse3 Status";
BA_ "SysSignalName" SG_ 517 RZCUeFs3Sts "RZCUeFs3Sts";
BA_ "CompuMethodName" SG_ 517 RZCUeFs3DiagSts "RZCUeFs3DiagSts";
BA_ "ISignalName" SG_ 517 RZCUeFs3DiagSts "IRZCUeFs3DiagSts";
BA_ "LongName" SG_ 517 RZCUeFs3DiagSts "RZCU eFuse3 Diagnostic Status";
BA_ "SysSignalName" SG_ 517 RZCUeFs3DiagSts "RZCUeFs3DiagSts";
BA_ "CompuMethodName" SG_ 517 RZCUeFs2Sts "RZCUeFs2Sts";
BA_ "ISignalName" SG_ 517 RZCUeFs2Sts "IRZCUeFs2Sts";
BA_ "LongName" SG_ 517 RZCUeFs2Sts "RZCU eFuse2 Status";
BA_ "SysSignalName" SG_ 517 RZCUeFs2Sts "RZCUeFs2Sts";
BA_ "CompuMethodName" SG_ 517 RZCUeFs2DiagSts "RZCUeFs2DiagSts";
BA_ "ISignalName" SG_ 517 RZCUeFs2DiagSts "IRZCUeFs2DiagSts";
BA_ "LongName" SG_ 517 RZCUeFs2DiagSts "RZCU eFuse2 Diagnostic Status";
BA_ "SysSignalName" SG_ 517 RZCUeFs2DiagSts "RZCUeFs2DiagSts";
BA_ "CompuMethodName" SG_ 517 RZCUeFs1Sts "RZCUeFs1Sts";
BA_ "ISignalName" SG_ 517 RZCUeFs1Sts "IRZCUeFs1Sts";
BA_ "LongName" SG_ 517 RZCUeFs1Sts "RZCU eFuse1 Status";
BA_ "SysSignalName" SG_ 517 RZCUeFs1Sts "RZCUeFs1Sts";
BA_ "CompuMethodName" SG_ 517 RZCUeFs1DiagSts "RZCUeFs1DiagSts";
BA_ "ISignalName" SG_ 517 RZCUeFs1DiagSts "IRZCUeFs1DiagSts";
BA_ "LongName" SG_ 517 RZCUeFs1DiagSts "RZCU eFuse1 Diagnostic Status";
BA_ "SysSignalName" SG_ 517 RZCUeFs1DiagSts "RZCUeFs1DiagSts";
BA_ "CompuMethodName" SG_ 517 RZCUeSw9Sts "RZCUeSw9Sts";
BA_ "ISignalName" SG_ 517 RZCUeSw9Sts "IRZCUeSw9Sts";
BA_ "LongName" SG_ 517 RZCUeSw9Sts "RZCU eSwitch9 Status";
BA_ "SysSignalName" SG_ 517 RZCUeSw9Sts "RZCUeSw9Sts";
BA_ "CompuMethodName" SG_ 517 RZCUeSw9DiagSts "RZCUeSw9DiagSts";
BA_ "ISignalName" SG_ 517 RZCUeSw9DiagSts "IRZCUeSw9DiagSts";
BA_ "LongName" SG_ 517 RZCUeSw9DiagSts "RZCU eSwitch9 Diagnostic Status";
BA_ "SysSignalName" SG_ 517 RZCUeSw9DiagSts "RZCUeSw9DiagSts";
BA_ "CompuMethodName" SG_ 1265 SAC_NM_BSMtoRMS_PTCANFD "SAC_NM_BSMtoRMS_PTCANFD";
BA_ "ISignalName" SG_ 1265 SAC_NM_BSMtoRMS_PTCANFD "ISAC_NM_BSMtoRMS_PTCANFD";
BA_ "LongName" SG_ 1265 SAC_NM_BSMtoRMS_PTCANFD "SAC NM BSMtoRMS PTCANFD";
BA_ "SysSignalName" SG_ 1265 SAC_NM_BSMtoRMS_PTCANFD "SAC_NM_BSMtoRMS_PTCANFD";
BA_ "CompuMethodName" SG_ 1265 SAC_NM_PBSMtoRMS_PTCANFD "SAC_NM_PBSMtoRMS_PTCANFD";
BA_ "ISignalName" SG_ 1265 SAC_NM_PBSMtoRMS_PTCANFD "ISAC_NM_PBSMtoRMS_PTCANFD";
BA_ "LongName" SG_ 1265 SAC_NM_PBSMtoRMS_PTCANFD "SAC NM PBSMtoRMS PTCANFD";
BA_ "SysSignalName" SG_ 1265 SAC_NM_PBSMtoRMS_PTCANFD "SAC_NM_PBSMtoRMS_PTCANFD";
BA_ "CompuMethodName" SG_ 1265 SAC_NM_RMStoNOS_PTCANFD "SAC_NM_RMStoNOS_PTCANFD";
BA_ "ISignalName" SG_ 1265 SAC_NM_RMStoNOS_PTCANFD "ISAC_NM_RMStoNOS_PTCANFD";
BA_ "LongName" SG_ 1265 SAC_NM_RMStoNOS_PTCANFD "SAC NM RMStoNOS PTCANFD";
BA_ "SysSignalName" SG_ 1265 SAC_NM_RMStoNOS_PTCANFD "SAC_NM_RMStoNOS_PTCANFD";
BA_ "CompuMethodName" SG_ 1265 SAC_NM_RSStoNOS_PTCANFD "SAC_NM_RSStoNOS_PTCANFD";
BA_ "ISignalName" SG_ 1265 SAC_NM_RSStoNOS_PTCANFD "ISAC_NM_RSStoNOS_PTCANFD";
BA_ "LongName" SG_ 1265 SAC_NM_RSStoNOS_PTCANFD "SAC NM RSStoNOS PTCANFD";
BA_ "SysSignalName" SG_ 1265 SAC_NM_RSStoNOS_PTCANFD "SAC_NM_RSStoNOS_PTCANFD";
BA_ "CompuMethodName" SG_ 1265 SAC_NM_RSStoRMS_PTCANFD "SAC_NM_RSStoRMS_PTCANFD";
BA_ "ISignalName" SG_ 1265 SAC_NM_RSStoRMS_PTCANFD "ISAC_NM_RSStoRMS_PTCANFD";
BA_ "LongName" SG_ 1265 SAC_NM_RSStoRMS_PTCANFD "SAC NM RSStoRMS PTCANFD";
BA_ "SysSignalName" SG_ 1265 SAC_NM_RSStoRMS_PTCANFD "SAC_NM_RSStoRMS_PTCANFD";
BA_ "CompuMethodName" SG_ 1265 SAC_NM_NOStoRMS_PTCANFD "SAC_NM_NOStoRMS_PTCANFD";
BA_ "ISignalName" SG_ 1265 SAC_NM_NOStoRMS_PTCANFD "ISAC_NM_NOStoRMS_PTCANFD";
BA_ "LongName" SG_ 1265 SAC_NM_NOStoRMS_PTCANFD "SAC NM NOStoRMS PTCANFD";
BA_ "SysSignalName" SG_ 1265 SAC_NM_NOStoRMS_PTCANFD "SAC_NM_NOStoRMS_PTCANFD";
BA_ "CompuMethodName" SG_ 1265 SAC_NM_NOSSta_PTCANFD "SAC_NM_NOSSta_PTCANFD";
BA_ "ISignalName" SG_ 1265 SAC_NM_NOSSta_PTCANFD "ISAC_NM_NOSSta_PTCANFD";
BA_ "LongName" SG_ 1265 SAC_NM_NOSSta_PTCANFD "SAC NM NOSSta PTCANFD";
BA_ "SysSignalName" SG_ 1265 SAC_NM_NOSSta_PTCANFD "SAC_NM_NOSSta_PTCANFD";
BA_ "CompuMethodName" SG_ 1265 SAC_NM_RMSSta_PTCANFD "SAC_NM_RMSSta_PTCANFD";
BA_ "ISignalName" SG_ 1265 SAC_NM_RMSSta_PTCANFD "ISAC_NM_RMSSta_PTCANFD";
BA_ "LongName" SG_ 1265 SAC_NM_RMSSta_PTCANFD "SAC NM RMSSta PTCANFD";
BA_ "SysSignalName" SG_ 1265 SAC_NM_RMSSta_PTCANFD "SAC_NM_RMSSta_PTCANFD";
BA_ "CompuMethodName" SG_ 1265 SAC_NWI_PTCANFD "SAC_NWI_PTCANFD";
BA_ "ISignalName" SG_ 1265 SAC_NWI_PTCANFD "ISAC_NWI_PTCANFD";
BA_ "LongName" SG_ 1265 SAC_NWI_PTCANFD "SAC PTCANFD Network Wakeup Indication";
BA_ "SysSignalName" SG_ 1265 SAC_NWI_PTCANFD "SAC_NWI_PTCANFD";
BA_ "CompuMethodName" SG_ 1265 SAC_NOI_PTCANFD "SAC_NOI_PTCANFD";
BA_ "ISignalName" SG_ 1265 SAC_NOI_PTCANFD "ISAC_NOI_PTCANFD";
BA_ "LongName" SG_ 1265 SAC_NOI_PTCANFD "SAC PTCANFD Network Operation Indication";
BA_ "SysSignalName" SG_ 1265 SAC_NOI_PTCANFD "SAC_NOI_PTCANFD";
BA_ "CompuMethodName" SG_ 1265 SAC_NKI_PTCANFD "SAC_NKI_PTCANFD";
BA_ "ISignalName" SG_ 1265 SAC_NKI_PTCANFD "ISAC_NKI_PTCANFD";
BA_ "LongName" SG_ 1265 SAC_NKI_PTCANFD "SAC PTCANFD Network Keep Indication";
BA_ "SysSignalName" SG_ 1265 SAC_NKI_PTCANFD "SAC_NKI_PTCANFD";
BA_ "CompuMethodName" SG_ 396 SDM_20ms_Group03_CRC "SDM_20ms_Group03_CRC";
BA_ "ISignalName" SG_ 396 SDM_20ms_Group03_CRC "ISDM_20ms_Group03_CRC";
BA_ "LongName" SG_ 396 SDM_20ms_Group03_CRC "SDM_20ms_Group03_CRC";
BA_ "SysSignalName" SG_ 396 SDM_20ms_Group03_CRC "SDM_20ms_Group03_CRC";
BA_ "CompuMethodName" SG_ 396 SDM_20ms_Group03_RC "SDM_20ms_Group03_RC";
BA_ "ISignalName" SG_ 396 SDM_20ms_Group03_RC "ISDM_20ms_Group03_RC";
BA_ "LongName" SG_ 396 SDM_20ms_Group03_RC "SDM_20ms_Group03_RC";
BA_ "SysSignalName" SG_ 396 SDM_20ms_Group03_RC "SDM_20ms_Group03_RC";
BA_ "CompuMethodName" SG_ 396 SDM_20ms_Group03_Reserved1 "SDM_20ms_Group03_Reserved1";
BA_ "GenSigStartValue" SG_ 396 SDM_20ms_Group03_Reserved1 15;
BA_ "ISignalName" SG_ 396 SDM_20ms_Group03_Reserved1 "ISDM_20ms_Group03_Reserved1";
BA_ "SysSignalName" SG_ 396 SDM_20ms_Group03_Reserved1 "SDM_20ms_Group03_Reserved1";
BA_ "CompuMethodName" SG_ 396 VehDynYawRate_SDM "VehDynYawRate_SDM";
BA_ "ISignalName" SG_ 396 VehDynYawRate_SDM "IVehDynYawRate_SDM";
BA_ "LongName" SG_ 396 VehDynYawRate_SDM "Vehicle Dynamics Yaw Rate";
BA_ "SysSignalName" SG_ 396 VehDynYawRate_SDM "VehDynYawRate_SDM";
BA_ "CompuMethodName" SG_ 396 VSELatAcc_SDM "VSELatAcc_SDM";
BA_ "ISignalName" SG_ 396 VSELatAcc_SDM "IVSELatAcc_SDM";
BA_ "LongName" SG_ 396 VSELatAcc_SDM "Vehicle Stability Enhancement Lateral Acceleration";
BA_ "SysSignalName" SG_ 396 VSELatAcc_SDM "VSELatAcc_SDM";
BA_ "CompuMethodName" SG_ 396 VSELongtAcc_SDM "VSELongtAcc_SDM";
BA_ "ISignalName" SG_ 396 VSELongtAcc_SDM "IVSELongtAcc_SDM";
BA_ "LongName" SG_ 396 VSELongtAcc_SDM "Vehicle Stability Enhancement Longitudinal Acceleration";
BA_ "SysSignalName" SG_ 396 VSELongtAcc_SDM "VSELongtAcc_SDM";
BA_ "CompuMethodName" SG_ 396 SDM_20ms_Group03_Reserved3 "SDM_20ms_Group03_Reserved3";
BA_ "GenSigStartValue" SG_ 396 SDM_20ms_Group03_Reserved3 3;
BA_ "ISignalName" SG_ 396 SDM_20ms_Group03_Reserved3 "ISDM_20ms_Group03_Reserved3";
BA_ "SysSignalName" SG_ 396 SDM_20ms_Group03_Reserved3 "SDM_20ms_Group03_Reserved3";
BA_ "CompuMethodName" SG_ 396 VSELatAccV_SDM "VSELatAccV_SDM";
BA_ "ISignalName" SG_ 396 VSELatAccV_SDM "IVSELatAccV_SDM";
BA_ "LongName" SG_ 396 VSELatAccV_SDM "Vehicle Stability Enhancement Lateral Acceleration Validity";
BA_ "SysSignalName" SG_ 396 VSELatAccV_SDM "VSELatAccV_SDM";
BA_ "CompuMethodName" SG_ 396 VehDynYawRateV_SDM "VehDynYawRateV_SDM";
BA_ "ISignalName" SG_ 396 VehDynYawRateV_SDM "IVehDynYawRateV_SDM";
BA_ "LongName" SG_ 396 VehDynYawRateV_SDM "Vehicle Dynamics Yaw Rate Validity";
BA_ "SysSignalName" SG_ 396 VehDynYawRateV_SDM "VehDynYawRateV_SDM";
BA_ "CompuMethodName" SG_ 396 VSELongtAccV_SDM "VSELongtAccV_SDM";
BA_ "ISignalName" SG_ 396 VSELongtAccV_SDM "IVSELongtAccV_SDM";
BA_ "LongName" SG_ 396 VSELongtAccV_SDM "Vehicle Stability Enhancement Longitudinal Acceleration Validity";
BA_ "SysSignalName" SG_ 396 VSELongtAccV_SDM "VSELongtAccV_SDM";
BA_ "CompuMethodName" SG_ 396 SDM_20ms_Group03_Reserved2 "SDM_20ms_Group03_Reserved2";
BA_ "GenSigStartValue" SG_ 396 SDM_20ms_Group03_Reserved2 1;
BA_ "ISignalName" SG_ 396 SDM_20ms_Group03_Reserved2 "ISDM_20ms_Group03_Reserved2";
BA_ "SysSignalName" SG_ 396 SDM_20ms_Group03_Reserved2 "SDM_20ms_Group03_Reserved2";
BA_ "CompuMethodName" SG_ 396 SDM_20ms_Group03_Reserved4 "SDM_20ms_Group03_Reserved4";
BA_ "GenSigStartValue" SG_ 396 SDM_20ms_Group03_Reserved4 255;
BA_ "ISignalName" SG_ 396 SDM_20ms_Group03_Reserved4 "ISDM_20ms_Group03_Reserved4";
BA_ "SysSignalName" SG_ 396 SDM_20ms_Group03_Reserved4 "SDM_20ms_Group03_Reserved4";
BA_ "CompuMethodName" SG_ 485 TCM_025ms_PDU02_CRC "TCM_025ms_PDU02_CRC";
BA_ "ISignalName" SG_ 485 TCM_025ms_PDU02_CRC "ITCM_025ms_PDU02_CRC";
BA_ "SysSignalName" SG_ 485 TCM_025ms_PDU02_CRC "TCM_025ms_PDU02_CRC";
BA_ "CompuMethodName" SG_ 485 TCM_025ms_PDU02_RC "TCM_025ms_PDU02_RC";
BA_ "ISignalName" SG_ 485 TCM_025ms_PDU02_RC "ITCM_025ms_PDU02_RC";
BA_ "SysSignalName" SG_ 485 TCM_025ms_PDU02_RC "TCM_025ms_PDU02_RC";
BA_ "CompuMethodName" SG_ 485 AutocTrCmddGear_TCM "AutocTrCmddGear_TCM";
BA_ "ISignalName" SG_ 485 AutocTrCmddGear_TCM "IAutocTrCmddGear_TCM";
BA_ "SysSignalName" SG_ 485 AutocTrCmddGear_TCM "AutocTrCmddGear_TCM";
BA_ "CompuMethodName" SG_ 485 DrvrShftCtrlTrgtGear_TCM "DrvrShftCtrlTrgtGear_TCM";
BA_ "ISignalName" SG_ 485 DrvrShftCtrlTrgtGear_TCM "IDrvrShftCtrlTrgtGear_TCM";
BA_ "SysSignalName" SG_ 485 DrvrShftCtrlTrgtGear_TCM "DrvrShftCtrlTrgtGear_TCM";
BA_ "CompuMethodName" SG_ 485 TrEPBAppReq "TrEPBAppReq";
BA_ "ISignalName" SG_ 485 TrEPBAppReq "ITrEPBAppReq";
BA_ "SysSignalName" SG_ 485 TrEPBAppReq "TrEPBAppReq";
BA_ "CompuMethodName" SG_ 485 DrvrShftCtrlReqDndIO "DrvrShftCtrlReqDndIO";
BA_ "ISignalName" SG_ 485 DrvrShftCtrlReqDndIO "IDrvrShftCtrlReqDndIO";
BA_ "SysSignalName" SG_ 485 DrvrShftCtrlReqDndIO "DrvrShftCtrlReqDndIO";
BA_ "CompuMethodName" SG_ 485 TCM_025ms_Group02_Reserved1 "TCM_025ms_Group02_Reserved1";
BA_ "GenSigStartValue" SG_ 485 TCM_025ms_Group02_Reserved1 3;
BA_ "ISignalName" SG_ 485 TCM_025ms_Group02_Reserved1 "ITCM_025ms_Group02_Reserved1";
BA_ "SysSignalName" SG_ 485 TCM_025ms_Group02_Reserved1 "TCM_025ms_Group02_Reserved1";
BA_ "CompuMethodName" SG_ 485 TrShftLvrPos_TCM "TrShftLvrPos_TCM";
BA_ "ISignalName" SG_ 485 TrShftLvrPos_TCM "ITrShftLvrPos_TCM";
BA_ "SysSignalName" SG_ 485 TrShftLvrPos_TCM "TrShftLvrPos_TCM";
BA_ "CompuMethodName" SG_ 485 TrShftLvrPosV_TCM "TrShftLvrPosV_TCM";
BA_ "ISignalName" SG_ 485 TrShftLvrPosV_TCM "ITrShftLvrPosV_TCM";
BA_ "SysSignalName" SG_ 485 TrShftLvrPosV_TCM "TrShftLvrPosV_TCM";
BA_ "CompuMethodName" SG_ 485 TrPrkSysF "TrPrkSysF";
BA_ "ISignalName" SG_ 485 TrPrkSysF "ITrPrkSysF";
BA_ "SysSignalName" SG_ 485 TrPrkSysF "TrPrkSysF";
BA_ "CompuMethodName" SG_ 485 TrPrkPos "TrPrkPos";
BA_ "ISignalName" SG_ 485 TrPrkPos "ITrPrkPos";
BA_ "SysSignalName" SG_ 485 TrPrkPos "TrPrkPos";
BA_ "CompuMethodName" SG_ 485 TrTrgtShftLvrPos "TrTrgtShftLvrPos";
BA_ "ISignalName" SG_ 485 TrTrgtShftLvrPos "ITrTrgtShftLvrPos";
BA_ "SysSignalName" SG_ 485 TrTrgtShftLvrPos "TrTrgtShftLvrPos";
BA_ "CompuMethodName" SG_ 485 TrEstdGear_TCM "TrEstdGear_TCM";
BA_ "ISignalName" SG_ 485 TrEstdGear_TCM "ITrEstdGear_TCM";
BA_ "SysSignalName" SG_ 485 TrEstdGear_TCM "TrEstdGear_TCM";
BA_ "CompuMethodName" SG_ 485 TrTapUpTapDwnMdSts_TCM "TrTapUpTapDwnMdSts_TCM";
BA_ "ISignalName" SG_ 485 TrTapUpTapDwnMdSts_TCM "ITrTapUpTapDwnMdSts_TCM";
BA_ "SysSignalName" SG_ 485 TrTapUpTapDwnMdSts_TCM "TrTapUpTapDwnMdSts_TCM";
BA_ "CompuMethodName" SG_ 485 TrShftPtrnASts_TCM "TrShftPtrnASts_TCM";
BA_ "ISignalName" SG_ 485 TrShftPtrnASts_TCM "ITrShftPtrnASts_TCM";
BA_ "SysSignalName" SG_ 485 TrShftPtrnASts_TCM "TrShftPtrnASts_TCM";
BA_ "CompuMethodName" SG_ 485 TrEstdGearV_TCM "TrEstdGearV_TCM";
BA_ "ISignalName" SG_ 485 TrEstdGearV_TCM "ITrEstdGearV_TCM";
BA_ "SysSignalName" SG_ 485 TrEstdGearV_TCM "TrEstdGearV_TCM";
BA_ "CompuMethodName" SG_ 485 TrCrpMdA_TCM "TrCrpMdA_TCM";
BA_ "ISignalName" SG_ 485 TrCrpMdA_TCM "ITrCrpMdA_TCM";
BA_ "SysSignalName" SG_ 485 TrCrpMdA_TCM "TrCrpMdA_TCM";
BA_ "CompuMethodName" SG_ 485 TCM_025ms_Group02_Reserved2 "TCM_025ms_Group02_Reserved2";
BA_ "GenSigStartValue" SG_ 485 TCM_025ms_Group02_Reserved2 1;
BA_ "ISignalName" SG_ 485 TCM_025ms_Group02_Reserved2 "ITCM_025ms_Group02_Reserved2";
BA_ "SysSignalName" SG_ 485 TCM_025ms_Group02_Reserved2 "TCM_025ms_Group02_Reserved2";
BA_ "CompuMethodName" SG_ 485 TrEngdSta_TCM "TrEngdSta_TCM";
BA_ "ISignalName" SG_ 485 TrEngdSta_TCM "ITrEngdSta_TCM";
BA_ "SysSignalName" SG_ 485 TrEngdSta_TCM "TrEngdSta_TCM";
BA_ "CompuMethodName" SG_ 485 TrEngdStaV_TCM "TrEngdStaV_TCM";
BA_ "ISignalName" SG_ 485 TrEngdStaV_TCM "ITrEngdStaV_TCM";
BA_ "SysSignalName" SG_ 485 TrEngdStaV_TCM "TrEngdStaV_TCM";
BA_ "CompuMethodName" SG_ 485 TrIntnlSwPos "TrIntnlSwPos";
BA_ "ISignalName" SG_ 485 TrIntnlSwPos "ITrIntnlSwPos";
BA_ "SysSignalName" SG_ 485 TrIntnlSwPos "TrIntnlSwPos";
BA_ "CompuMethodName" SG_ 485 TrIntnlSwPosV "TrIntnlSwPosV";
BA_ "ISignalName" SG_ 485 TrIntnlSwPosV "ITrIntnlSwPosV";
BA_ "SysSignalName" SG_ 485 TrIntnlSwPosV "TrIntnlSwPosV";
BA_ "CompuMethodName" SG_ 485 TCM_025ms_Group02_Reserved3 "TCM_025ms_Group02_Reserved3";
BA_ "GenSigStartValue" SG_ 485 TCM_025ms_Group02_Reserved3 255;
BA_ "ISignalName" SG_ 485 TCM_025ms_Group02_Reserved3 "ITCM_025ms_Group02_Reserved3";
BA_ "SysSignalName" SG_ 485 TCM_025ms_Group02_Reserved3 "TCM_025ms_Group02_Reserved3";
BA_ "CompuMethodName" SG_ 393 TCM_025ms_PDU05_CRC "TCM_025ms_PDU05_CRC";
BA_ "ISignalName" SG_ 393 TCM_025ms_PDU05_CRC "ITCM_025ms_PDU05_CRC";
BA_ "SysSignalName" SG_ 393 TCM_025ms_PDU05_CRC "TCM_025ms_PDU05_CRC";
BA_ "CompuMethodName" SG_ 393 TCM_025ms_PDU05_RC "TCM_025ms_PDU05_RC";
BA_ "ISignalName" SG_ 393 TCM_025ms_PDU05_RC "ITCM_025ms_PDU05_RC";
BA_ "SysSignalName" SG_ 393 TCM_025ms_PDU05_RC "TCM_025ms_PDU05_RC";
BA_ "CompuMethodName" SG_ 393 TrImmdCrkshftToqRespTyp "TrImmdCrkshftToqRespTyp";
BA_ "ISignalName" SG_ 393 TrImmdCrkshftToqRespTyp "ITrImmdCrkshftToqRespTyp";
BA_ "LongName" SG_ 393 TrImmdCrkshftToqRespTyp "Transmission Immediate Crankshaft Torque Response Type";
BA_ "SysSignalName" SG_ 393 TrImmdCrkshftToqRespTyp "TrImmdCrkshftToqRespTyp";
BA_ "CompuMethodName" SG_ 393 TrPrdtdCrkshftToqIntrvnTyp "TrPrdtdCrkshftToqIntrvnTyp";
BA_ "ISignalName" SG_ 393 TrPrdtdCrkshftToqIntrvnTyp "ITrPrdtdCrkshftToqIntrvnTyp";
BA_ "LongName" SG_ 393 TrPrdtdCrkshftToqIntrvnTyp "Transmission Predicted Crankshaft Torque Intervention Type";
BA_ "SysSignalName" SG_ 393 TrPrdtdCrkshftToqIntrvnTyp "TrPrdtdCrkshftToqIntrvnTyp";
BA_ "CompuMethodName" SG_ 393 TrPrdtdCrkshftToqReqV "TrPrdtdCrkshftToqReqV";
BA_ "ISignalName" SG_ 393 TrPrdtdCrkshftToqReqV "ITrPrdtdCrkshftToqReqV";
BA_ "LongName" SG_ 393 TrPrdtdCrkshftToqReqV "Transmission Predicted Crankshaft Torque Request Value";
BA_ "SysSignalName" SG_ 393 TrPrdtdCrkshftToqReqV "TrPrdtdCrkshftToqReqV";
BA_ "CompuMethodName" SG_ 393 TrImmdCrkshftToqReqVal "TrImmdCrkshftToqReqVal";
BA_ "ISignalName" SG_ 393 TrImmdCrkshftToqReqVal "ITrImmdCrkshftToqReqVal";
BA_ "LongName" SG_ 393 TrImmdCrkshftToqReqVal "Transmission Immediate Crankshaft Torque Request Value";
BA_ "SysSignalName" SG_ 393 TrImmdCrkshftToqReqVal "TrImmdCrkshftToqReqVal";
BA_ "CompuMethodName" SG_ 393 TrGear "TrGear";
BA_ "ISignalName" SG_ 393 TrGear "ITrGear";
BA_ "SysSignalName" SG_ 393 TrGear "TrGear";
BA_ "CompuMethodName" SG_ 393 TCM_025ms_PDU05_Reserve01 "TCM_025ms_PDU05_Reserve01";
BA_ "GenSigStartValue" SG_ 393 TCM_025ms_PDU05_Reserve01 8191;
BA_ "ISignalName" SG_ 393 TCM_025ms_PDU05_Reserve01 "ITCM_025ms_PDU05_Reserve01";
BA_ "SysSignalName" SG_ 393 TCM_025ms_PDU05_Reserve01 "TCM_025ms_PDU05_Reserve01";
BA_ "CompuMethodName" SG_ 393 TrGearV "TrGearV";
BA_ "ISignalName" SG_ 393 TrGearV "ITrGearV";
BA_ "SysSignalName" SG_ 393 TrGearV "TrGearV";
BA_ "CompuMethodName" SG_ 340 TCM_020ms_PDU18_CRC "TCM_020ms_PDU18_CRC";
BA_ "ISignalName" SG_ 340 TCM_020ms_PDU18_CRC "ITCM_020ms_PDU18_CRC";
BA_ "SysSignalName" SG_ 340 TCM_020ms_PDU18_CRC "TCM_020ms_PDU18_CRC";
BA_ "CompuMethodName" SG_ 340 TCM_020ms_PDU18_RC "TCM_020ms_PDU18_RC";
BA_ "ISignalName" SG_ 340 TCM_020ms_PDU18_RC "ITCM_020ms_PDU18_RC";
BA_ "SysSignalName" SG_ 340 TCM_020ms_PDU18_RC "TCM_020ms_PDU18_RC";
BA_ "CompuMethodName" SG_ 340 TCM_020ms_PDU18_Reserve03 "TCM_020ms_PDU18_Reserve03";
BA_ "GenSigStartValue" SG_ 340 TCM_020ms_PDU18_Reserve03 15;
BA_ "ISignalName" SG_ 340 TCM_020ms_PDU18_Reserve03 "ITCM_020ms_PDU18_Reserve03";
BA_ "SysSignalName" SG_ 340 TCM_020ms_PDU18_Reserve03 "TCM_020ms_PDU18_Reserve03";
BA_ "CompuMethodName" SG_ 340 CluActTorq "CluActTorq";
BA_ "ISignalName" SG_ 340 CluActTorq "ICluActTorq";
BA_ "SysSignalName" SG_ 340 CluActTorq "CluActTorq";
BA_ "CompuMethodName" SG_ 340 SCUAPAUnderCtrlA_TCM "SCUAPAUnderCtrlA_TCM";
BA_ "ISignalName" SG_ 340 SCUAPAUnderCtrlA_TCM "ISCUAPAUnderCtrlA_TCM";
BA_ "SysSignalName" SG_ 340 SCUAPAUnderCtrlA_TCM "SCUAPAUnderCtrlA_TCM";
BA_ "CompuMethodName" SG_ 340 TrAPACanclReq "TrAPACanclReq";
BA_ "ISignalName" SG_ 340 TrAPACanclReq "ITrAPACanclReq";
BA_ "SysSignalName" SG_ 340 TrAPACanclReq "TrAPACanclReq";
BA_ "CompuMethodName" SG_ 340 TCM_020ms_PDU18_Reserve01 "TCM_020ms_PDU18_Reserve01";
BA_ "GenSigStartValue" SG_ 340 TCM_020ms_PDU18_Reserve01 127;
BA_ "ISignalName" SG_ 340 TCM_020ms_PDU18_Reserve01 "ITCM_020ms_PDU18_Reserve01";
BA_ "SysSignalName" SG_ 340 TCM_020ms_PDU18_Reserve01 "TCM_020ms_PDU18_Reserve01";
BA_ "CompuMethodName" SG_ 340 SCUDrvrIntrvnA_TCM "SCUDrvrIntrvnA_TCM";
BA_ "ISignalName" SG_ 340 SCUDrvrIntrvnA_TCM "ISCUDrvrIntrvnA_TCM";
BA_ "LongName" SG_ 340 SCUDrvrIntrvnA_TCM "Shifter Control Unit Driver Intervention Active_TCM";
BA_ "SysSignalName" SG_ 340 SCUDrvrIntrvnA_TCM "SCUDrvrIntrvnA_TCM";
BA_ "CompuMethodName" SG_ 340 TCM_020ms_PDU18_Reserve02 "TCM_020ms_PDU18_Reserve02";
BA_ "GenSigStartValue" SG_ 340 TCM_020ms_PDU18_Reserve02 16777215;
BA_ "ISignalName" SG_ 340 TCM_020ms_PDU18_Reserve02 "ITCM_020ms_PDU18_Reserve02";
BA_ "SysSignalName" SG_ 340 TCM_020ms_PDU18_Reserve02 "TCM_020ms_PDU18_Reserve02";
BA_ "CompuMethodName" SG_ 443 TCM_025ms_PDU20_CRC "TCM_025ms_PDU20_CRC";
BA_ "ISignalName" SG_ 443 TCM_025ms_PDU20_CRC "ITCM_025ms_PDU20_CRC";
BA_ "SysSignalName" SG_ 443 TCM_025ms_PDU20_CRC "TCM_025ms_PDU20_CRC";
BA_ "CompuMethodName" SG_ 443 TCM_025ms_PDU20_RC "TCM_025ms_PDU20_RC";
BA_ "ISignalName" SG_ 443 TCM_025ms_PDU20_RC "ITCM_025ms_PDU20_RC";
BA_ "SysSignalName" SG_ 443 TCM_025ms_PDU20_RC "TCM_025ms_PDU20_RC";
BA_ "CompuMethodName" SG_ 443 TCM_025ms_PDU20_Reserve03 "TCM_025ms_PDU20_Reserve03";
BA_ "GenSigStartValue" SG_ 443 TCM_025ms_PDU20_Reserve03 1;
BA_ "ISignalName" SG_ 443 TCM_025ms_PDU20_Reserve03 "ITCM_025ms_PDU20_Reserve03";
BA_ "SysSignalName" SG_ 443 TCM_025ms_PDU20_Reserve03 "TCM_025ms_PDU20_Reserve03";
BA_ "CompuMethodName" SG_ 443 TrACCToqReqResp "TrACCToqReqResp";
BA_ "ISignalName" SG_ 443 TrACCToqReqResp "ITrACCToqReqResp";
BA_ "SysSignalName" SG_ 443 TrACCToqReqResp "TrACCToqReqResp";
BA_ "CompuMethodName" SG_ 443 TCM_025ms_PDU20_Reserve01 "TCM_025ms_PDU20_Reserve01";
BA_ "GenSigStartValue" SG_ 443 TCM_025ms_PDU20_Reserve01 65535;
BA_ "ISignalName" SG_ 443 TCM_025ms_PDU20_Reserve01 "ITCM_025ms_PDU20_Reserve01";
BA_ "SysSignalName" SG_ 443 TCM_025ms_PDU20_Reserve01 "TCM_025ms_PDU20_Reserve01";
BA_ "CompuMethodName" SG_ 443 TCM_025ms_PDU20_Reserve02 "TCM_025ms_PDU20_Reserve02";
BA_ "GenSigStartValue" SG_ 443 TCM_025ms_PDU20_Reserve02 65535;
BA_ "ISignalName" SG_ 443 TCM_025ms_PDU20_Reserve02 "ITCM_025ms_PDU20_Reserve02";
BA_ "SysSignalName" SG_ 443 TCM_025ms_PDU20_Reserve02 "TCM_025ms_PDU20_Reserve02";
BA_ "CompuMethodName" SG_ 443 TCM_025ms_PDU20_Reserve04 "TCM_025ms_PDU20_Reserve04";
BA_ "GenSigStartValue" SG_ 443 TCM_025ms_PDU20_Reserve04 65535;
BA_ "ISignalName" SG_ 443 TCM_025ms_PDU20_Reserve04 "ITCM_025ms_PDU20_Reserve04";
BA_ "SysSignalName" SG_ 443 TCM_025ms_PDU20_Reserve04 "TCM_025ms_PDU20_Reserve04";
BA_ "CompuMethodName" SG_ 410 EDUOilPmpMotSpdReq "EDUOilPmpMotSpdReq";
BA_ "GenSigStartValue" SG_ 410 EDUOilPmpMotSpdReq 8191;
BA_ "ISignalName" SG_ 410 EDUOilPmpMotSpdReq "IEDUOilPmpMotSpdReq";
BA_ "LongName" SG_ 410 EDUOilPmpMotSpdReq "Electric Drive Unit  Oil Pump Motor Speed Request";
BA_ "SysSignalName" SG_ 410 EDUOilPmpMotSpdReq "EDUOilPmpMotSpdReq";
BA_ "CompuMethodName" SG_ 410 EDUOilPmpMotEnb "EDUOilPmpMotEnb";
BA_ "ISignalName" SG_ 410 EDUOilPmpMotEnb "IEDUOilPmpMotEnb";
BA_ "LongName" SG_ 410 EDUOilPmpMotEnb "Electric Drive Unit  Oil Pump Motor Enable";
BA_ "SysSignalName" SG_ 410 EDUOilPmpMotEnb "EDUOilPmpMotEnb";
BA_ "CompuMethodName" SG_ 410 EDUOilTemV "EDUOilTemV";
BA_ "GenSigStartValue" SG_ 410 EDUOilTemV 1;
BA_ "ISignalName" SG_ 410 EDUOilTemV "IEDUOilTemV";
BA_ "LongName" SG_ 410 EDUOilTemV "Electric Drive Unit Oil Temperature Valid";
BA_ "SysSignalName" SG_ 410 EDUOilTemV "EDUOilTemV";
BA_ "CompuMethodName" SG_ 410 EDUOilTem "EDUOilTem";
BA_ "ISignalName" SG_ 410 EDUOilTem "IEDUOilTem";
BA_ "LongName" SG_ 410 EDUOilTem "Electric Drive Unit Oil Temperature";
BA_ "SysSignalName" SG_ 410 EDUOilTem "EDUOilTem";
BA_ "CompuMethodName" SG_ 534 ICBVC_50ms_Group256_CRC "ICBVC_50ms_Group256_CRC";
BA_ "ISignalName" SG_ 534 ICBVC_50ms_Group256_CRC "IICBVC_50ms_Group256_CRC";
BA_ "SysSignalName" SG_ 534 ICBVC_50ms_Group256_CRC "ICBVC_50ms_Group256_CRC";
BA_ "CompuMethodName" SG_ 534 ICBVC_50ms_Group256_RC "ICBVC_50ms_Group256_RC";
BA_ "ISignalName" SG_ 534 ICBVC_50ms_Group256_RC "IICBVC_50ms_Group256_RC";
BA_ "SysSignalName" SG_ 534 ICBVC_50ms_Group256_RC "ICBVC_50ms_Group256_RC";
BA_ "CompuMethodName" SG_ 534 SWSPB3SwStuckL "SWSPB3SwStuckL";
BA_ "ISignalName" SG_ 534 SWSPB3SwStuckL "ISWSPB3SwStuckL";
BA_ "LongName" SG_ 534 SWSPB3SwStuckL "Steering Wheel Switch Push Button 3 Switch Stuck
      Left";
BA_ "SysSignalName" SG_ 534 SWSPB3SwStuckL "SWSPB3SwStuckL";
BA_ "CompuMethodName" SG_ 534 SWSSelRSwStuckL "SWSSelRSwStuckL";
BA_ "ISignalName" SG_ 534 SWSSelRSwStuckL "ISWSSelRSwStuckL";
BA_ "LongName" SG_ 534 SWSSelRSwStuckL "Steering Wheel Switch Select Right Switch Stuck
      Left";
BA_ "SysSignalName" SG_ 534 SWSSelRSwStuckL "SWSSelRSwStuckL";
BA_ "CompuMethodName" SG_ 534 SWSSelLSwStuckL "SWSSelLSwStuckL";
BA_ "ISignalName" SG_ 534 SWSSelLSwStuckL "ISWSSelLSwStuckL";
BA_ "LongName" SG_ 534 SWSSelLSwStuckL "Steering Wheel Switch Select Left Switch Stuck
      Left";
BA_ "SysSignalName" SG_ 534 SWSSelLSwStuckL "SWSSelLSwStuckL";
BA_ "CompuMethodName" SG_ 534 SWSPB2SwStuckL "SWSPB2SwStuckL";
BA_ "GenSigStartValue" SG_ 534 SWSPB2SwStuckL 1;
BA_ "ISignalName" SG_ 534 SWSPB2SwStuckL "ISWSPB2SwStuckL";
BA_ "LongName" SG_ 534 SWSPB2SwStuckL "Steering Wheel Switch Push Button 2 Switch Stuck Left";
BA_ "SysSignalName" SG_ 534 SWSPB2SwStuckL "SWSPB2SwStuckL";
BA_ "CompuMethodName" SG_ 534 RoadCrvt "RoadCrvt";
BA_ "GenSigStartValue" SG_ 534 RoadCrvt 131072;
BA_ "ISignalName" SG_ 534 RoadCrvt "IRoadCrvt";
BA_ "LongName" SG_ 534 RoadCrvt "Road Curvature";
BA_ "SysSignalName" SG_ 534 RoadCrvt "RoadCrvt";
BA_ "CompuMethodName" SG_ 534 RoadSlope "RoadSlope";
BA_ "GenSigStartValue" SG_ 534 RoadSlope 2048;
BA_ "ISignalName" SG_ 534 RoadSlope "IRoadSlope";
BA_ "LongName" SG_ 534 RoadSlope "Road Slope";
BA_ "SysSignalName" SG_ 534 RoadSlope "RoadSlope";
BA_ "CompuMethodName" SG_ 534 SWSLFnChngSwA "SWSLFnChngSwA";
BA_ "GenSigStartValue" SG_ 534 SWSLFnChngSwA 1;
BA_ "ISignalName" SG_ 534 SWSLFnChngSwA "ISWSLFnChngSwA";
BA_ "LongName" SG_ 534 SWSLFnChngSwA "Steering Wheel Switch Left Function Change Switch Active";
BA_ "SysSignalName" SG_ 534 SWSLFnChngSwA "SWSLFnChngSwA";
BA_ "CompuMethodName" SG_ 534 SWSCnfmSwStuckL "SWSCnfmSwStuckL";
BA_ "GenSigStartValue" SG_ 534 SWSCnfmSwStuckL 1;
BA_ "ISignalName" SG_ 534 SWSCnfmSwStuckL "ISWSCnfmSwStuckL";
BA_ "LongName" SG_ 534 SWSCnfmSwStuckL "Steering Wheel Switch Confirm Switch Stuck Left";
BA_ "SysSignalName" SG_ 534 SWSCnfmSwStuckL "SWSCnfmSwStuckL";
BA_ "CompuMethodName" SG_ 534 RoadCrvtDist "RoadCrvtDist";
BA_ "ISignalName" SG_ 534 RoadCrvtDist "IRoadCrvtDist";
BA_ "LongName" SG_ 534 RoadCrvtDist "Road Curvature Distance";
BA_ "SysSignalName" SG_ 534 RoadCrvtDist "RoadCrvtDist";
BA_ "CompuMethodName" SG_ 534 RoadSlopeDist "RoadSlopeDist";
BA_ "ISignalName" SG_ 534 RoadSlopeDist "IRoadSlopeDist";
BA_ "LongName" SG_ 534 RoadSlopeDist "Road Slope Distance";
BA_ "SysSignalName" SG_ 534 RoadSlopeDist "RoadSlopeDist";
BA_ "CompuMethodName" SG_ 534 SWSPB1SwStuckL "SWSPB1SwStuckL";
BA_ "GenSigStartValue" SG_ 534 SWSPB1SwStuckL 1;
BA_ "ISignalName" SG_ 534 SWSPB1SwStuckL "ISWSPB1SwStuckL";
BA_ "LongName" SG_ 534 SWSPB1SwStuckL "Steering Wheel Switch Push Button 1 Switch Stuck Left";
BA_ "SysSignalName" SG_ 534 SWSPB1SwStuckL "SWSPB1SwStuckL";
BA_ "CompuMethodName" SG_ 534 DMSSts "DMSSts";
BA_ "ISignalName" SG_ 534 DMSSts "IDMSSts";
BA_ "LongName" SG_ 534 DMSSts "DMS_Status";
BA_ "SysSignalName" SG_ 534 DMSSts "DMSSts";
BA_ "CompuMethodName" SG_ 534 RoughRoaddetectionDist "RoughRoaddetectionDist";
BA_ "ISignalName" SG_ 534 RoughRoaddetectionDist "IRoughRoaddetectionDist";
BA_ "LongName" SG_ 534 RoughRoaddetectionDist "An_indication_that_a_rough Road_feature_has_been_detected_distence";
BA_ "SysSignalName" SG_ 534 RoughRoaddetectionDist "RoughRoaddetectionDist";
BA_ "CompuMethodName" SG_ 534 ICBVC_50ms_Group256_Reserved85 "ICBVC_50ms_Group256_Reserved85";
BA_ "GenSigStartValue" SG_ 534 ICBVC_50ms_Group256_Reserved85 63;
BA_ "ISignalName" SG_ 534 ICBVC_50ms_Group256_Reserved85 "IICBVC_50ms_Group256_Reserved85";
BA_ "SysSignalName" SG_ 534 ICBVC_50ms_Group256_Reserved85 "ICBVC_50ms_Group256_Reserved85";
BA_ "CompuMethodName" SG_ 534 ICBVC_50ms_Group256_Reserved95 "ICBVC_50ms_Group256_Reserved95";
BA_ "GenSigStartValue" SG_ 534 ICBVC_50ms_Group256_Reserved95 255;
BA_ "ISignalName" SG_ 534 ICBVC_50ms_Group256_Reserved95 "IICBVC_50ms_Group256_Reserved95";
BA_ "SysSignalName" SG_ 534 ICBVC_50ms_Group256_Reserved95 "ICBVC_50ms_Group256_Reserved95";
BA_ "CompuMethodName" SG_ 534 ICBVC_50ms_Group256_Reserved96 "ICBVC_50ms_Group256_Reserved96";
BA_ "GenSigStartValue" SG_ 534 ICBVC_50ms_Group256_Reserved96 1;
BA_ "ISignalName" SG_ 534 ICBVC_50ms_Group256_Reserved96 "IICBVC_50ms_Group256_Reserved96";
BA_ "SysSignalName" SG_ 534 ICBVC_50ms_Group256_Reserved96 "ICBVC_50ms_Group256_Reserved96";
BA_ "CompuMethodName" SG_ 534 VehboardSetting "VehboardSetting";
BA_ "ISignalName" SG_ 534 VehboardSetting "IVehboardSetting";
BA_ "LongName" SG_ 534 VehboardSetting "Vehicle dashboard Setting";
BA_ "SysSignalName" SG_ 534 VehboardSetting "VehboardSetting";
BA_ "CompuMethodName" SG_ 534 ICBVC_50ms_Group256_Reserved100 "ICBVC_50ms_Group256_Reserved100";
BA_ "GenSigStartValue" SG_ 534 ICBVC_50ms_Group256_Reserved100 3;
BA_ "ISignalName" SG_ 534 ICBVC_50ms_Group256_Reserved100 "IICBVC_50ms_Group256_Reserved100";
BA_ "SysSignalName" SG_ 534 ICBVC_50ms_Group256_Reserved100 "ICBVC_50ms_Group256_Reserved100";
BA_ "CompuMethodName" SG_ 534 RoughRoaddetection "RoughRoaddetection";
BA_ "ISignalName" SG_ 534 RoughRoaddetection "IRoughRoaddetection";
BA_ "LongName" SG_ 534 RoughRoaddetection "An_indication_that_a_rough Road_feature_has_been_detected";
BA_ "SysSignalName" SG_ 534 RoughRoaddetection "RoughRoaddetection";
BA_ "CompuMethodName" SG_ 534 ICBVC_50ms_Group256_Reserved103 "ICBVC_50ms_Group256_Reserved103";
BA_ "GenSigStartValue" SG_ 534 ICBVC_50ms_Group256_Reserved103 3;
BA_ "ISignalName" SG_ 534 ICBVC_50ms_Group256_Reserved103 "IICBVC_50ms_Group256_Reserved103";
BA_ "SysSignalName" SG_ 534 ICBVC_50ms_Group256_Reserved103 "ICBVC_50ms_Group256_Reserved103";
BA_ "CompuMethodName" SG_ 534 ICBVC_50ms_Group256_Reserved111 "ICBVC_50ms_Group256_Reserved111";
BA_ "GenSigStartValue" SG_ 534 ICBVC_50ms_Group256_Reserved111 255;
BA_ "ISignalName" SG_ 534 ICBVC_50ms_Group256_Reserved111 "IICBVC_50ms_Group256_Reserved111";
BA_ "SysSignalName" SG_ 534 ICBVC_50ms_Group256_Reserved111 "ICBVC_50ms_Group256_Reserved111";
BA_ "CompuMethodName" SG_ 534 ICBVC_50ms_Group256_Reserved119 "ICBVC_50ms_Group256_Reserved119";
BA_ "GenSigStartValue" SG_ 534 ICBVC_50ms_Group256_Reserved119 255;
BA_ "ISignalName" SG_ 534 ICBVC_50ms_Group256_Reserved119 "IICBVC_50ms_Group256_Reserved119";
BA_ "SysSignalName" SG_ 534 ICBVC_50ms_Group256_Reserved119 "ICBVC_50ms_Group256_Reserved119";
BA_ "CompuMethodName" SG_ 534 ICBVC_50ms_Group256_Reserved127 "ICBVC_50ms_Group256_Reserved127";
BA_ "GenSigStartValue" SG_ 534 ICBVC_50ms_Group256_Reserved127 255;
BA_ "ISignalName" SG_ 534 ICBVC_50ms_Group256_Reserved127 "IICBVC_50ms_Group256_Reserved127";
BA_ "SysSignalName" SG_ 534 ICBVC_50ms_Group256_Reserved127 "ICBVC_50ms_Group256_Reserved127";
BA_ "CompuMethodName" SG_ 1216 ZXD_NM_BSMtoRMS_PTCANFD "ZXD_NM_BSMtoRMS_PTCANFD";
BA_ "ISignalName" SG_ 1216 ZXD_NM_BSMtoRMS_PTCANFD "IZXD_NM_BSMtoRMS_PTCANFD";
BA_ "LongName" SG_ 1216 ZXD_NM_BSMtoRMS_PTCANFD "ZXD_NM_BSMtoRMS_PTCANFD";
BA_ "SysSignalName" SG_ 1216 ZXD_NM_BSMtoRMS_PTCANFD "ZXD_NM_BSMtoRMS_PTCANFD";
BA_ "CompuMethodName" SG_ 1216 ZXD_NM_PBSMtoRMS_PTCANFD "ZXD_NM_PBSMtoRMS_PTCANFD";
BA_ "ISignalName" SG_ 1216 ZXD_NM_PBSMtoRMS_PTCANFD "IZXD_NM_PBSMtoRMS_PTCANFD";
BA_ "LongName" SG_ 1216 ZXD_NM_PBSMtoRMS_PTCANFD "ZXD_NM_PBSMtoRMS_PTCANFD";
BA_ "SysSignalName" SG_ 1216 ZXD_NM_PBSMtoRMS_PTCANFD "ZXD_NM_PBSMtoRMS_PTCANFD";
BA_ "CompuMethodName" SG_ 1216 ZXD_NM_RMStoNOS_PTCANFD "ZXD_NM_RMStoNOS_PTCANFD";
BA_ "ISignalName" SG_ 1216 ZXD_NM_RMStoNOS_PTCANFD "IZXD_NM_RMStoNOS_PTCANFD";
BA_ "LongName" SG_ 1216 ZXD_NM_RMStoNOS_PTCANFD "ZXD_NM_RMStoNOS_PTCANFD";
BA_ "SysSignalName" SG_ 1216 ZXD_NM_RMStoNOS_PTCANFD "ZXD_NM_RMStoNOS_PTCANFD";
BA_ "CompuMethodName" SG_ 1216 ZXD_NM_RSStoNOS_PTCANFD "ZXD_NM_RSStoNOS_PTCANFD";
BA_ "ISignalName" SG_ 1216 ZXD_NM_RSStoNOS_PTCANFD "IZXD_NM_RSStoNOS_PTCANFD";
BA_ "LongName" SG_ 1216 ZXD_NM_RSStoNOS_PTCANFD "ZXD_NM_RSStoNOS_PTCANFD";
BA_ "SysSignalName" SG_ 1216 ZXD_NM_RSStoNOS_PTCANFD "ZXD_NM_RSStoNOS_PTCANFD";
BA_ "CompuMethodName" SG_ 1216 ZXD_NM_RSStoRMS_PTCANFD "ZXD_NM_RSStoRMS_PTCANFD";
BA_ "ISignalName" SG_ 1216 ZXD_NM_RSStoRMS_PTCANFD "IZXD_NM_RSStoRMS_PTCANFD";
BA_ "LongName" SG_ 1216 ZXD_NM_RSStoRMS_PTCANFD "ZXD_NM_RSStoRMS_PTCANFD";
BA_ "SysSignalName" SG_ 1216 ZXD_NM_RSStoRMS_PTCANFD "ZXD_NM_RSStoRMS_PTCANFD";
BA_ "CompuMethodName" SG_ 1216 ZXD_NM_NOStoRMS_PTCANFD "ZXD_NM_NOStoRMS_PTCANFD";
BA_ "ISignalName" SG_ 1216 ZXD_NM_NOStoRMS_PTCANFD "IZXD_NM_NOStoRMS_PTCANFD";
BA_ "LongName" SG_ 1216 ZXD_NM_NOStoRMS_PTCANFD "ZXD_NM_NOStoRMS_PTCANFD";
BA_ "SysSignalName" SG_ 1216 ZXD_NM_NOStoRMS_PTCANFD "ZXD_NM_NOStoRMS_PTCANFD";
BA_ "CompuMethodName" SG_ 1216 ZXD_NM_NOSSta_PTCANFD "ZXD_NM_NOSSta_PTCANFD";
BA_ "ISignalName" SG_ 1216 ZXD_NM_NOSSta_PTCANFD "IZXD_NM_NOSSta_PTCANFD";
BA_ "LongName" SG_ 1216 ZXD_NM_NOSSta_PTCANFD "ZXD_NM_NOSSta_PTCANFD";
BA_ "SysSignalName" SG_ 1216 ZXD_NM_NOSSta_PTCANFD "ZXD_NM_NOSSta_PTCANFD";
BA_ "CompuMethodName" SG_ 1216 ZXD_NM_RMSSta_PTCANFD "ZXD_NM_RMSSta_PTCANFD";
BA_ "ISignalName" SG_ 1216 ZXD_NM_RMSSta_PTCANFD "IZXD_NM_RMSSta_PTCANFD";
BA_ "LongName" SG_ 1216 ZXD_NM_RMSSta_PTCANFD "ZXD_NM_RMSSta_PTCANFD";
BA_ "SysSignalName" SG_ 1216 ZXD_NM_RMSSta_PTCANFD "ZXD_NM_RMSSta_PTCANFD";
BA_ "CompuMethodName" SG_ 1216 ZXD_NWI_PTCANFD "ZXD_NWI_PTCANFD";
BA_ "ISignalName" SG_ 1216 ZXD_NWI_PTCANFD "IZXD_NWI_PTCANFD";
BA_ "LongName" SG_ 1216 ZXD_NWI_PTCANFD "ZXD RZCUCANFD Network_Wakeup_Indication";
BA_ "SysSignalName" SG_ 1216 ZXD_NWI_PTCANFD "ZXD_NWI_PTCANFD";
BA_ "CompuMethodName" SG_ 1216 ZXD_NOI_PTCANFD "ZXD_NOI_PTCANFD";
BA_ "ISignalName" SG_ 1216 ZXD_NOI_PTCANFD "IZXD_NOI_PTCANFD";
BA_ "LongName" SG_ 1216 ZXD_NOI_PTCANFD "ZXD RZCUCANFD Network Operation Indication";
BA_ "SysSignalName" SG_ 1216 ZXD_NOI_PTCANFD "ZXD_NOI_PTCANFD";
BA_ "CompuMethodName" SG_ 1216 ZXD_NKI_PTCANFD "ZXD_NKI_PTCANFD";
BA_ "ISignalName" SG_ 1216 ZXD_NKI_PTCANFD "IZXD_NKI_PTCANFD";
BA_ "LongName" SG_ 1216 ZXD_NKI_PTCANFD "ZXD RZCUCANFD Network Keep Indication";
BA_ "SysSignalName" SG_ 1216 ZXD_NKI_PTCANFD "ZXD_NKI_PTCANFD";
BA_ "CompuMethodName" SG_ 2147559184 LowTemWtrPumpAfterRunLvl "LowTemWtrPumpAfterRunLvl";
BA_ "ISignalName" SG_ 2147559184 LowTemWtrPumpAfterRunLvl "ILowTemWtrPumpAfterRunLvl";
BA_ "LongName" SG_ 2147559184 LowTemWtrPumpAfterRunLvl "Low Temperature Water Pump After Run Level";
BA_ "SysSignalName" SG_ 2147559184 LowTemWtrPumpAfterRunLvl "LowTemWtrPumpAfterRunLvl";
BA_ "CompuMethodName" SG_ 2147559184 AmbtTemSnsrFlrStsInvsn "AmbtTemSnsrFlrStsInvsn";
BA_ "GenSigStartValue" SG_ 2147559184 AmbtTemSnsrFlrStsInvsn 7;
BA_ "ISignalName" SG_ 2147559184 AmbtTemSnsrFlrStsInvsn "IAmbtTemSnsrFlrStsInvsn";
BA_ "LongName" SG_ 2147559184 AmbtTemSnsrFlrStsInvsn "Ambient Temperature Sensor Failure Status Inversion";
BA_ "SysSignalName" SG_ 2147559184 AmbtTemSnsrFlrStsInvsn "AmbtTemSnsrFlrStsInvsn";
BA_ "CompuMethodName" SG_ 2147559184 AmbtTemSnsrFlrSts "AmbtTemSnsrFlrSts";
BA_ "ISignalName" SG_ 2147559184 AmbtTemSnsrFlrSts "IAmbtTemSnsrFlrSts";
BA_ "LongName" SG_ 2147559184 AmbtTemSnsrFlrSts "Ambient Temperature Sensor Failure Status";
BA_ "SysSignalName" SG_ 2147559184 AmbtTemSnsrFlrSts "AmbtTemSnsrFlrSts";
BA_ "CompuMethodName" SG_ 2147559184 EnEleclMainWtrPumpActuSpd "EnEleclMainWtrPumpActuSpd";
BA_ "ISignalName" SG_ 2147559184 EnEleclMainWtrPumpActuSpd "IEnEleclMainWtrPumpActuSpd";
BA_ "LongName" SG_ 2147559184 EnEleclMainWtrPumpActuSpd "Engine Electrical Main Water Pump Actual Speed";
BA_ "SysSignalName" SG_ 2147559184 EnEleclMainWtrPumpActuSpd "EnEleclMainWtrPumpActuSpd";
BA_ "CompuMethodName" SG_ 2147559184 CoolngFanPWMFdbk "CoolngFanPWMFdbk";
BA_ "ISignalName" SG_ 2147559184 CoolngFanPWMFdbk "ICoolngFanPWMFdbk";
BA_ "LongName" SG_ 2147559184 CoolngFanPWMFdbk "Cooling Fan Pulse Width Modulation Feedback";
BA_ "SysSignalName" SG_ 2147559184 CoolngFanPWMFdbk "CoolngFanPWMFdbk";
BA_ "CompuMethodName" SG_ 2147559184 FuelSysVentCmdd "FuelSysVentCmdd";
BA_ "ISignalName" SG_ 2147559184 FuelSysVentCmdd "IFuelSysVentCmdd";
BA_ "LongName" SG_ 2147559184 FuelSysVentCmdd "Fuel System Vent Commanded";
BA_ "SysSignalName" SG_ 2147559184 FuelSysVentCmdd "FuelSysVentCmdd";
BA_ "CompuMethodName" SG_ 2147559184 PrmntDTCDrvngCycCrtra "PrmntDTCDrvngCycCrtra";
BA_ "ISignalName" SG_ 2147559184 PrmntDTCDrvngCycCrtra "IPrmntDTCDrvngCycCrtra";
BA_ "LongName" SG_ 2147559184 PrmntDTCDrvngCycCrtra "Permanent Diagnostic Trouble Code Driving Cycle Criteria";
BA_ "SysSignalName" SG_ 2147559184 PrmntDTCDrvngCycCrtra "PrmntDTCDrvngCycCrtra";
BA_ "CompuMethodName" SG_ 2147559184 FuelSysVentFltA "FuelSysVentFltA";
BA_ "ISignalName" SG_ 2147559184 FuelSysVentFltA "IFuelSysVentFltA";
BA_ "LongName" SG_ 2147559184 FuelSysVentFltA "Fuel System Vent Fault Active";
BA_ "SysSignalName" SG_ 2147559184 FuelSysVentFltA "FuelSysVentFltA";
BA_ "CompuMethodName" SG_ 2147559184 EnDrvngCycCrtra "EnDrvngCycCrtra";
BA_ "ISignalName" SG_ 2147559184 EnDrvngCycCrtra "IEnDrvngCycCrtra";
BA_ "LongName" SG_ 2147559184 EnDrvngCycCrtra "Engine Driving Cycle Criteria";
BA_ "SysSignalName" SG_ 2147559184 EnDrvngCycCrtra "EnDrvngCycCrtra";
BA_ "CompuMethodName" SG_ 2147559184 IUPREnStFnshd "IUPREnStFnshd";
BA_ "ISignalName" SG_ 2147559184 IUPREnStFnshd "IIUPREnStFnshd";
BA_ "LongName" SG_ 2147559184 IUPREnStFnshd "In User Performance Ratio Engine Start Finished";
BA_ "SysSignalName" SG_ 2147559184 IUPREnStFnshd "IUPREnStFnshd";
BA_ "CompuMethodName" SG_ 2147559184 IUPRDnmtrIncmntd "IUPRDnmtrIncmntd";
BA_ "ISignalName" SG_ 2147559184 IUPRDnmtrIncmntd "IIUPRDnmtrIncmntd";
BA_ "LongName" SG_ 2147559184 IUPRDnmtrIncmntd "In User Performance Ratio Denominator Incremented";
BA_ "SysSignalName" SG_ 2147559184 IUPRDnmtrIncmntd "IUPRDnmtrIncmntd";
BA_ "CompuMethodName" SG_ 2147559184 IUPRDnmtrInh "IUPRDnmtrInh";
BA_ "ISignalName" SG_ 2147559184 IUPRDnmtrInh "IIUPRDnmtrInh";
BA_ "LongName" SG_ 2147559184 IUPRDnmtrInh "In User Performance Ratio Denominator Inhibit";
BA_ "SysSignalName" SG_ 2147559184 IUPRDnmtrInh "IUPRDnmtrInh";
BA_ "CompuMethodName" SG_ 2147559184 CoolngFanLvlFdbk "CoolngFanLvlFdbk";
BA_ "ISignalName" SG_ 2147559184 CoolngFanLvlFdbk "ICoolngFanLvlFdbk";
BA_ "LongName" SG_ 2147559184 CoolngFanLvlFdbk "Cooling Fan Level Feedback";
BA_ "SysSignalName" SG_ 2147559184 CoolngFanLvlFdbk "CoolngFanLvlFdbk";
BA_ "CompuMethodName" SG_ 2147559185 EnClntTrtTem "EnClntTrtTem";
BA_ "GenSigStartValue" SG_ 2147559185 EnClntTrtTem 140;
BA_ "ISignalName" SG_ 2147559185 EnClntTrtTem "IEnClntTrtTem";
BA_ "SysSignalName" SG_ 2147559185 EnClntTrtTem "EnClntTrtTem";
BA_ "CompuMethodName" SG_ 2147559185 EPTClntPumpSta "EPTClntPumpSta";
BA_ "GenSigStartValue" SG_ 2147559185 EPTClntPumpSta 15;
BA_ "ISignalName" SG_ 2147559185 EPTClntPumpSta "IEPTClntPumpSta";
BA_ "LongName" SG_ 2147559185 EPTClntPumpSta "EPT ClntPump Work Status";
BA_ "SysSignalName" SG_ 2147559185 EPTClntPumpSta "EPTClntPumpSta";
BA_ "CompuMethodName" SG_ 2147559185 ESSClntPumpSta "ESSClntPumpSta";
BA_ "GenSigStartValue" SG_ 2147559185 ESSClntPumpSta 15;
BA_ "ISignalName" SG_ 2147559185 ESSClntPumpSta "IESSClntPumpSta";
BA_ "LongName" SG_ 2147559185 ESSClntPumpSta "ESSClntPump Work Status";
BA_ "SysSignalName" SG_ 2147559185 ESSClntPumpSta "ESSClntPumpSta";
BA_ "CompuMethodName" SG_ 2147559185 EPTElecWtrPumpTrgtSpd "EPTElecWtrPumpTrgtSpd";
BA_ "GenSigStartValue" SG_ 2147559185 EPTElecWtrPumpTrgtSpd 255;
BA_ "ISignalName" SG_ 2147559185 EPTElecWtrPumpTrgtSpd "IEPTElecWtrPumpTrgtSpd";
BA_ "LongName" SG_ 2147559185 EPTElecWtrPumpTrgtSpd "Ept Electric Water Pump Target Speed";
BA_ "SysSignalName" SG_ 2147559185 EPTElecWtrPumpTrgtSpd "EPTElecWtrPumpTrgtSpd";
BA_ "CompuMethodName" SG_ 2147559185 ESSElecWtrPumpTrgtSpd "ESSElecWtrPumpTrgtSpd";
BA_ "GenSigStartValue" SG_ 2147559185 ESSElecWtrPumpTrgtSpd 255;
BA_ "ISignalName" SG_ 2147559185 ESSElecWtrPumpTrgtSpd "IESSElecWtrPumpTrgtSpd";
BA_ "LongName" SG_ 2147559185 ESSElecWtrPumpTrgtSpd "Ess Electric Water Pump Target Speed";
BA_ "SysSignalName" SG_ 2147559185 ESSElecWtrPumpTrgtSpd "ESSElecWtrPumpTrgtSpd";
BA_ "CompuMethodName" SG_ 2147559185 CoolngFanWorkSta "CoolngFanWorkSta";
BA_ "GenSigStartValue" SG_ 2147559185 CoolngFanWorkSta 15;
BA_ "ISignalName" SG_ 2147559185 CoolngFanWorkSta "ICoolngFanWorkSta";
BA_ "LongName" SG_ 2147559185 CoolngFanWorkSta "Cooling Fan Work Status";
BA_ "SysSignalName" SG_ 2147559185 CoolngFanWorkSta "CoolngFanWorkSta";
BA_ "CompuMethodName" SG_ 2147559185 LowTemWtrPumpTrgtSpd "LowTemWtrPumpTrgtSpd";
BA_ "GenSigStartValue" SG_ 2147559185 LowTemWtrPumpTrgtSpd 255;
BA_ "ISignalName" SG_ 2147559185 LowTemWtrPumpTrgtSpd "ILowTemWtrPumpTrgtSpd";
BA_ "SysSignalName" SG_ 2147559185 LowTemWtrPumpTrgtSpd "LowTemWtrPumpTrgtSpd";
BA_ "CompuMethodName" SG_ 2147559185 EnSpdOBD "EnSpdOBD";
BA_ "ISignalName" SG_ 2147559185 EnSpdOBD "IEnSpdOBD";
BA_ "LongName" SG_ 2147559185 EnSpdOBD "Engine Speed On Board Diagnostics";
BA_ "SysSignalName" SG_ 2147559185 EnSpdOBD "EnSpdOBD";
BA_ "CompuMethodName" SG_ 2147559186 RVSPtRunAbotdRsn "RVSPtRunAbotdRsn";
BA_ "ISignalName" SG_ 2147559186 RVSPtRunAbotdRsn "IRVSPtRunAbotdRsn";
BA_ "SysSignalName" SG_ 2147559186 RVSPtRunAbotdRsn "RVSPtRunAbotdRsn";
BA_ "CompuMethodName" SG_ 2147559186 EnGPFLampOnSts "EnGPFLampOnSts";
BA_ "ISignalName" SG_ 2147559186 EnGPFLampOnSts "IEnGPFLampOnSts";
BA_ "LongName" SG_ 2147559186 EnGPFLampOnSts "Engine Gasoline Particulate Filter Lamp On Status";
BA_ "SysSignalName" SG_ 2147559186 EnGPFLampOnSts "EnGPFLampOnSts";
BA_ "CompuMethodName" SG_ 2147559186 EnFuelCsumpEfncy "EnFuelCsumpEfncy";
BA_ "ISignalName" SG_ 2147559186 EnFuelCsumpEfncy "IEnFuelCsumpEfncy";
BA_ "LongName" SG_ 2147559186 EnFuelCsumpEfncy "Engine Fuel Consumption Efficiency";
BA_ "SysSignalName" SG_ 2147559186 EnFuelCsumpEfncy "EnFuelCsumpEfncy";
BA_ "CompuMethodName" SG_ 2147559186 ECMCoolngFanPWMReq "ECMCoolngFanPWMReq";
BA_ "ISignalName" SG_ 2147559186 ECMCoolngFanPWMReq "IECMCoolngFanPWMReq";
BA_ "LongName" SG_ 2147559186 ECMCoolngFanPWMReq "Ecm Cooling Fan Pulse Width Modulation Request";
BA_ "SysSignalName" SG_ 2147559186 ECMCoolngFanPWMReq "ECMCoolngFanPWMReq";
BA_ "CompuMethodName" SG_ 2147559186 FuelCsump "FuelCsump";
BA_ "ISignalName" SG_ 2147559186 FuelCsump "IFuelCsump";
BA_ "LongName" SG_ 2147559186 FuelCsump "Fuel Consumption";
BA_ "SysSignalName" SG_ 2147559186 FuelCsump "FuelCsump";
BA_ "CompuMethodName" SG_ 2147559186 RVSPtCrkAbotdRsn "RVSPtCrkAbotdRsn";
BA_ "ISignalName" SG_ 2147559186 RVSPtCrkAbotdRsn "IRVSPtCrkAbotdRsn";
BA_ "SysSignalName" SG_ 2147559186 RVSPtCrkAbotdRsn "RVSPtCrkAbotdRsn";
BA_ "CompuMethodName" SG_ 2147559186 VehRfulSta "VehRfulSta";
BA_ "ISignalName" SG_ 2147559186 VehRfulSta "IVehRfulSta";
BA_ "LongName" SG_ 2147559186 VehRfulSta "Vehicle Refuel State";
BA_ "SysSignalName" SG_ 2147559186 VehRfulSta "VehRfulSta";
BA_ "CompuMethodName" SG_ 2147559186 ECMCoolngFanPWMReqV "ECMCoolngFanPWMReqV";
BA_ "GenSigStartValue" SG_ 2147559186 ECMCoolngFanPWMReqV 1;
BA_ "ISignalName" SG_ 2147559186 ECMCoolngFanPWMReqV "IECMCoolngFanPWMReqV";
BA_ "LongName" SG_ 2147559186 ECMCoolngFanPWMReqV "Ecm Cooling Fan Pulse Width Modulation Request Validity";
BA_ "SysSignalName" SG_ 2147559186 ECMCoolngFanPWMReqV "ECMCoolngFanPWMReqV";
BA_ "CompuMethodName" SG_ 2147559186 AccelAbsPosOBD "AccelAbsPosOBD";
BA_ "ISignalName" SG_ 2147559186 AccelAbsPosOBD "IAccelAbsPosOBD";
BA_ "LongName" SG_ 2147559186 AccelAbsPosOBD "Accelerator Absolute Position On Board Diagnostics";
BA_ "SysSignalName" SG_ 2147559186 AccelAbsPosOBD "AccelAbsPosOBD";
BA_ "CompuMethodName" SG_ 2147559186 EnCalcLdValOBD "EnCalcLdValOBD";
BA_ "ISignalName" SG_ 2147559186 EnCalcLdValOBD "IEnCalcLdValOBD";
BA_ "LongName" SG_ 2147559186 EnCalcLdValOBD "Engine Calculated Load Value On Board Diagnostics";
BA_ "SysSignalName" SG_ 2147559186 EnCalcLdValOBD "EnCalcLdValOBD";
BA_ "CompuMethodName" SG_ 2147631108 BMSEmsnRltdMalfA "BMSEmsnRltdMalfA";
BA_ "ISignalName" SG_ 2147631108 BMSEmsnRltdMalfA "IBMSEmsnRltdMalfA";
BA_ "LongName" SG_ 2147631108 BMSEmsnRltdMalfA "Battery Management System Emissions Related Malfunction Active";
BA_ "SysSignalName" SG_ 2147631108 BMSEmsnRltdMalfA "BMSEmsnRltdMalfA";
BA_ "CompuMethodName" SG_ 2147631108 BMSOdoFctV "BMSOdoFctV";
BA_ "GenSigStartValue" SG_ 2147631108 BMSOdoFctV 1;
BA_ "ISignalName" SG_ 2147631108 BMSOdoFctV "IBMSOdoFctV";
BA_ "LongName" SG_ 2147631108 BMSOdoFctV "Battery Management System Odometer Factor Validity";
BA_ "SysSignalName" SG_ 2147631108 BMSOdoFctV "BMSOdoFctV";
BA_ "CompuMethodName" SG_ 2147631108 BMSCdstCtr "BMSCdstCtr";
BA_ "ISignalName" SG_ 2147631108 BMSCdstCtr "IBMSCdstCtr";
BA_ "LongName" SG_ 2147631108 BMSCdstCtr "Battery Management System Coldstart Counter";
BA_ "SysSignalName" SG_ 2147631108 BMSCdstCtr "BMSCdstCtr";
BA_ "CompuMethodName" SG_ 2147631108 BMSOdoFct "BMSOdoFct";
BA_ "GenSigStartValue" SG_ 2147631108 BMSOdoFct 255;
BA_ "ISignalName" SG_ 2147631108 BMSOdoFct "IBMSOdoFct";
BA_ "LongName" SG_ 2147631108 BMSOdoFct "Battery Management System Odometer Factor";
BA_ "SysSignalName" SG_ 2147631108 BMSOdoFct "BMSOdoFct";
BA_ "CompuMethodName" SG_ 2147631108 BMSStdAvlblEnrg "BMSStdAvlblEnrg";
BA_ "GenSigStartValue" SG_ 2147631108 BMSStdAvlblEnrg 4095;
BA_ "ISignalName" SG_ 2147631108 BMSStdAvlblEnrg "IBMSStdAvlblEnrg";
BA_ "LongName" SG_ 2147631108 BMSStdAvlblEnrg "Battery Management System Standard Available Energy";
BA_ "SysSignalName" SG_ 2147631108 BMSStdAvlblEnrg "BMSStdAvlblEnrg";
BA_ "CompuMethodName" SG_ 2147631108 BMSChrgTrgtStdAvlblEnrg "BMSChrgTrgtStdAvlblEnrg";
BA_ "GenSigStartValue" SG_ 2147631108 BMSChrgTrgtStdAvlblEnrg 4095;
BA_ "ISignalName" SG_ 2147631108 BMSChrgTrgtStdAvlblEnrg "IBMSChrgTrgtStdAvlblEnrg";
BA_ "LongName" SG_ 2147631108 BMSChrgTrgtStdAvlblEnrg "Battery Management System Charge Target Standard Available Energy";
BA_ "SysSignalName" SG_ 2147631108 BMSChrgTrgtStdAvlblEnrg "BMSChrgTrgtStdAvlblEnrg";
BA_ "CompuMethodName" SG_ 2147631108 BMSDisTrgtStdAvlblEnrg "BMSDisTrgtStdAvlblEnrg";
BA_ "GenSigStartValue" SG_ 2147631108 BMSDisTrgtStdAvlblEnrg 4095;
BA_ "ISignalName" SG_ 2147631108 BMSDisTrgtStdAvlblEnrg "IBMSDisTrgtStdAvlblEnrg";
BA_ "LongName" SG_ 2147631108 BMSDisTrgtStdAvlblEnrg "Battery Management System Discharge Standard CLTC Available Energy";
BA_ "SysSignalName" SG_ 2147631108 BMSDisTrgtStdAvlblEnrg "BMSDisTrgtStdAvlblEnrg";
BA_ "CompuMethodName" SG_ 2147631108 BMSStdAvlblEnrgV "BMSStdAvlblEnrgV";
BA_ "GenSigStartValue" SG_ 2147631108 BMSStdAvlblEnrgV 1;
BA_ "ISignalName" SG_ 2147631108 BMSStdAvlblEnrgV "IBMSStdAvlblEnrgV";
BA_ "LongName" SG_ 2147631108 BMSStdAvlblEnrgV "Battery Management System Standard Available Energy Validity";
BA_ "SysSignalName" SG_ 2147631108 BMSStdAvlblEnrgV "BMSStdAvlblEnrgV";
BA_ "CompuMethodName" SG_ 2147631108 BMSChrgTrgtStdAvlblEnrgV "BMSChrgTrgtStdAvlblEnrgV";
BA_ "GenSigStartValue" SG_ 2147631108 BMSChrgTrgtStdAvlblEnrgV 1;
BA_ "ISignalName" SG_ 2147631108 BMSChrgTrgtStdAvlblEnrgV "IBMSChrgTrgtStdAvlblEnrgV";
BA_ "LongName" SG_ 2147631108 BMSChrgTrgtStdAvlblEnrgV "Battery Management System Charge Target Standard Available Energy Validity";
BA_ "SysSignalName" SG_ 2147631108 BMSChrgTrgtStdAvlblEnrgV "BMSChrgTrgtStdAvlblEnrgV";
BA_ "CompuMethodName" SG_ 2147631108 BMSDisTrgtStdAvlblEnrgV "BMSDisTrgtStdAvlblEnrgV";
BA_ "GenSigStartValue" SG_ 2147631108 BMSDisTrgtStdAvlblEnrgV 1;
BA_ "ISignalName" SG_ 2147631108 BMSDisTrgtStdAvlblEnrgV "IBMSDisTrgtStdAvlblEnrgV";
BA_ "LongName" SG_ 2147631108 BMSDisTrgtStdAvlblEnrgV "Battery Management System Discharge Standard CLTC Available Energy Validity";
BA_ "SysSignalName" SG_ 2147631108 BMSDisTrgtStdAvlblEnrgV "BMSDisTrgtStdAvlblEnrgV";
BA_ "CompuMethodName" SG_ 2147549444 ESS_100ms_Group25_CRC "ESS_100ms_Group25_CRC";
BA_ "ISignalName" SG_ 2147549444 ESS_100ms_Group25_CRC "IESS_100ms_Group25_CRC";
BA_ "LongName" SG_ 2147549444 ESS_100ms_Group25_CRC "ESS_100ms_Group25_CRC";
BA_ "SysSignalName" SG_ 2147549444 ESS_100ms_Group25_CRC "ESS_100ms_Group25_CRC";
BA_ "CompuMethodName" SG_ 2147549444 ESS_100ms_Group25_RC "ESS_100ms_Group25_RC";
BA_ "ISignalName" SG_ 2147549444 ESS_100ms_Group25_RC "IESS_100ms_Group25_RC";
BA_ "LongName" SG_ 2147549444 ESS_100ms_Group25_RC "ESS_100ms_Group25_RC";
BA_ "SysSignalName" SG_ 2147549444 ESS_100ms_Group25_RC "ESS_100ms_Group25_RC";
BA_ "CompuMethodName" SG_ 2147549444 ESS_100ms_Group25_Reserved1 "ESS_100ms_Group25_Reserved1";
BA_ "GenSigStartValue" SG_ 2147549444 ESS_100ms_Group25_Reserved1 15;
BA_ "ISignalName" SG_ 2147549444 ESS_100ms_Group25_Reserved1 "IESS_100ms_Group25_Reserved1";
BA_ "SysSignalName" SG_ 2147549444 ESS_100ms_Group25_Reserved1 "ESS_100ms_Group25_Reserved1";
BA_ "CompuMethodName" SG_ 2147549444 BMSPosPtIsltnRstc "BMSPosPtIsltnRstc";
BA_ "GenSigStartValue" SG_ 2147549444 BMSPosPtIsltnRstc 16383;
BA_ "ISignalName" SG_ 2147549444 BMSPosPtIsltnRstc "IBMSPosPtIsltnRstc";
BA_ "LongName" SG_ 2147549444 BMSPosPtIsltnRstc "Battery Management System Positive Powertrain Isolation Resistance";
BA_ "SysSignalName" SG_ 2147549444 BMSPosPtIsltnRstc "BMSPosPtIsltnRstc";
BA_ "CompuMethodName" SG_ 2147549444 BMSPosPtIsltnRstcV "BMSPosPtIsltnRstcV";
BA_ "GenSigStartValue" SG_ 2147549444 BMSPosPtIsltnRstcV 1;
BA_ "ISignalName" SG_ 2147549444 BMSPosPtIsltnRstcV "IBMSPosPtIsltnRstcV";
BA_ "LongName" SG_ 2147549444 BMSPosPtIsltnRstcV "Battery Management System Postive Powertrain Isolation Resistance Validity";
BA_ "SysSignalName" SG_ 2147549444 BMSPosPtIsltnRstcV "BMSPosPtIsltnRstcV";
BA_ "CompuMethodName" SG_ 2147549444 BMSNegPtIsltnRstcV "BMSNegPtIsltnRstcV";
BA_ "GenSigStartValue" SG_ 2147549444 BMSNegPtIsltnRstcV 1;
BA_ "ISignalName" SG_ 2147549444 BMSNegPtIsltnRstcV "IBMSNegPtIsltnRstcV";
BA_ "LongName" SG_ 2147549444 BMSNegPtIsltnRstcV "Battery Management System Negative Powertrain Isolation Resistance Validity";
BA_ "SysSignalName" SG_ 2147549444 BMSNegPtIsltnRstcV "BMSNegPtIsltnRstcV";
BA_ "CompuMethodName" SG_ 2147549444 BMSNegPtIsltnRstc "BMSNegPtIsltnRstc";
BA_ "GenSigStartValue" SG_ 2147549444 BMSNegPtIsltnRstc 16383;
BA_ "ISignalName" SG_ 2147549444 BMSNegPtIsltnRstc "IBMSNegPtIsltnRstc";
BA_ "LongName" SG_ 2147549444 BMSNegPtIsltnRstc "Battery Management System Negative Powertrain Isolation Resistance";
BA_ "SysSignalName" SG_ 2147549444 BMSNegPtIsltnRstc "BMSNegPtIsltnRstc";
BA_ "CompuMethodName" SG_ 2147549444 ESS_100ms_Group25_Reserved2 "ESS_100ms_Group25_Reserved2";
BA_ "GenSigStartValue" SG_ 2147549444 ESS_100ms_Group25_Reserved2 3;
BA_ "ISignalName" SG_ 2147549444 ESS_100ms_Group25_Reserved2 "IESS_100ms_Group25_Reserved2";
BA_ "SysSignalName" SG_ 2147549444 ESS_100ms_Group25_Reserved2 "ESS_100ms_Group25_Reserved2";
BA_ "CompuMethodName" SG_ 2147549444 ESS_100ms_Group25_Reserved3 "ESS_100ms_Group25_Reserved3";
BA_ "GenSigStartValue" SG_ 2147549444 ESS_100ms_Group25_Reserved3 255;
BA_ "ISignalName" SG_ 2147549444 ESS_100ms_Group25_Reserved3 "IESS_100ms_Group25_Reserved3";
BA_ "SysSignalName" SG_ 2147549444 ESS_100ms_Group25_Reserved3 "ESS_100ms_Group25_Reserved3";
BA_ "CompuMethodName" SG_ 2147549444 ESS_100ms_Group25_Reserved4 "ESS_100ms_Group25_Reserved4";
BA_ "GenSigStartValue" SG_ 2147549444 ESS_100ms_Group25_Reserved4 255;
BA_ "ISignalName" SG_ 2147549444 ESS_100ms_Group25_Reserved4 "IESS_100ms_Group25_Reserved4";
BA_ "SysSignalName" SG_ 2147549444 ESS_100ms_Group25_Reserved4 "ESS_100ms_Group25_Reserved4";
BA_ "CompuMethodName" SG_ 2147549442 BMSStaOfHealthResi "BMSStaOfHealthResi";
BA_ "GenSigStartValue" SG_ 2147549442 BMSStaOfHealthResi 254;
BA_ "ISignalName" SG_ 2147549442 BMSStaOfHealthResi "IBMSStaOfHealthResi";
BA_ "LongName" SG_ 2147549442 BMSStaOfHealthResi "Battery Management System State Of Health Resistance";
BA_ "SysSignalName" SG_ 2147549442 BMSStaOfHealthResi "BMSStaOfHealthResi";
BA_ "CompuMethodName" SG_ 2147549442 BMSStaOfHealthCapct "BMSStaOfHealthCapct";
BA_ "GenSigStartValue" SG_ 2147549442 BMSStaOfHealthCapct 254;
BA_ "ISignalName" SG_ 2147549442 BMSStaOfHealthCapct "IBMSStaOfHealthCapct";
BA_ "LongName" SG_ 2147549442 BMSStaOfHealthCapct "Battery Management System State Of Health Capacity";
BA_ "SysSignalName" SG_ 2147549442 BMSStaOfHealthCapct "BMSStaOfHealthCapct";
BA_ "CompuMethodName" SG_ 2147549442 BMSOnbdChrgSpRsn "BMSOnbdChrgSpRsn";
BA_ "ISignalName" SG_ 2147549442 BMSOnbdChrgSpRsn "IBMSOnbdChrgSpRsn";
BA_ "LongName" SG_ 2147549442 BMSOnbdChrgSpRsn "Battery Management System Onboard Charge Stop Reason";
BA_ "SysSignalName" SG_ 2147549442 BMSOnbdChrgSpRsn "BMSOnbdChrgSpRsn";
BA_ "CompuMethodName" SG_ 2147549442 BMSPackSOH "BMSPackSOH";
BA_ "GenSigStartValue" SG_ 2147549442 BMSPackSOH 1022;
BA_ "ISignalName" SG_ 2147549442 BMSPackSOH "IBMSPackSOH";
BA_ "LongName" SG_ 2147549442 BMSPackSOH "Battery Management System Pack State Of Health";
BA_ "SysSignalName" SG_ 2147549442 BMSPackSOH "BMSPackSOH";
BA_ "CompuMethodName" SG_ 2147549442 BMSFltLamp "BMSFltLamp";
BA_ "ISignalName" SG_ 2147549442 BMSFltLamp "IBMSFltLamp";
BA_ "LongName" SG_ 2147549442 BMSFltLamp "Battery Management System Fault Lamp";
BA_ "SysSignalName" SG_ 2147549442 BMSFltLamp "BMSFltLamp";
BA_ "CompuMethodName" SG_ 2147549442 HVBatShutOff "HVBatShutOff";
BA_ "GenSigStartValue" SG_ 2147549442 HVBatShutOff 1;
BA_ "ISignalName" SG_ 2147549442 HVBatShutOff "IHVBatShutOff";
BA_ "LongName" SG_ 2147549442 HVBatShutOff "High Voltage Battery Shut Off";
BA_ "SysSignalName" SG_ 2147549442 HVBatShutOff "HVBatShutOff";
BA_ "CompuMethodName" SG_ 2147558227 HVBatSOCHiResV "HVBatSOCHiResV";
BA_ "ISignalName" SG_ 2147558227 HVBatSOCHiResV "IHVBatSOCHiResV";
BA_ "LongName" SG_ 2147558227 HVBatSOCHiResV "High Voltage Battery State Of Charge High Resolution Validity";
BA_ "SysSignalName" SG_ 2147558227 HVBatSOCHiResV "HVBatSOCHiResV";
BA_ "CompuMethodName" SG_ 2147558227 HVBatSOCMin "HVBatSOCMin";
BA_ "ISignalName" SG_ 2147558227 HVBatSOCMin "IHVBatSOCMin";
BA_ "LongName" SG_ 2147558227 HVBatSOCMin "High Voltage Battery State Of Charge Minimum";
BA_ "SysSignalName" SG_ 2147558227 HVBatSOCMin "HVBatSOCMin";
BA_ "CompuMethodName" SG_ 2147558227 HVBatSOCHiRes "HVBatSOCHiRes";
BA_ "ISignalName" SG_ 2147558227 HVBatSOCHiRes "IHVBatSOCHiRes";
BA_ "LongName" SG_ 2147558227 HVBatSOCHiRes "High Voltage Battery State Of Charge High Resolution";
BA_ "SysSignalName" SG_ 2147558227 HVBatSOCHiRes "HVBatSOCHiRes";
BA_ "CompuMethodName" SG_ 2147558227 HVBatSOCTrgtHiRes "HVBatSOCTrgtHiRes";
BA_ "ISignalName" SG_ 2147558227 HVBatSOCTrgtHiRes "IHVBatSOCTrgtHiRes";
BA_ "LongName" SG_ 2147558227 HVBatSOCTrgtHiRes "High Voltage Battery State Of Charge Target High Resolution";
BA_ "SysSignalName" SG_ 2147558227 HVBatSOCTrgtHiRes "HVBatSOCTrgtHiRes";
BA_ "CompuMethodName" SG_ 2147558232 ESS_100ms_Group58_CRC "ESS_100ms_Group58_CRC";
BA_ "ISignalName" SG_ 2147558232 ESS_100ms_Group58_CRC "IESS_100ms_Group58_CRC";
BA_ "LongName" SG_ 2147558232 ESS_100ms_Group58_CRC "ESS_100ms_Group58_CRC";
BA_ "SysSignalName" SG_ 2147558232 ESS_100ms_Group58_CRC "ESS_100ms_Group58_CRC";
BA_ "CompuMethodName" SG_ 2147558232 ESS_100ms_Group58_RC "ESS_100ms_Group58_RC";
BA_ "ISignalName" SG_ 2147558232 ESS_100ms_Group58_RC "IESS_100ms_Group58_RC";
BA_ "LongName" SG_ 2147558232 ESS_100ms_Group58_RC "ESS_100ms_Group58_RC";
BA_ "SysSignalName" SG_ 2147558232 ESS_100ms_Group58_RC "ESS_100ms_Group58_RC";
BA_ "CompuMethodName" SG_ 2147558232 BMSOfbdChrgrSktVolV "BMSOfbdChrgrSktVolV";
BA_ "ISignalName" SG_ 2147558232 BMSOfbdChrgrSktVolV "IBMSOfbdChrgrSktVolV";
BA_ "LongName" SG_ 2147558232 BMSOfbdChrgrSktVolV "Battery Management System Off-board Charger Socket Voltage Validity";
BA_ "SysSignalName" SG_ 2147558232 BMSOfbdChrgrSktVolV "BMSOfbdChrgrSktVolV";
BA_ "CompuMethodName" SG_ 2147558232 ESS_100ms_Group58_Reserved1 "ESS_100ms_Group58_Reserved1";
BA_ "GenSigStartValue" SG_ 2147558232 ESS_100ms_Group58_Reserved1 1;
BA_ "ISignalName" SG_ 2147558232 ESS_100ms_Group58_Reserved1 "IESS_100ms_Group58_Reserved1";
BA_ "SysSignalName" SG_ 2147558232 ESS_100ms_Group58_Reserved1 "ESS_100ms_Group58_Reserved1";
BA_ "CompuMethodName" SG_ 2147558232 BMSOffBdChrgrPlugOn "BMSOffBdChrgrPlugOn";
BA_ "ISignalName" SG_ 2147558232 BMSOffBdChrgrPlugOn "IBMSOffBdChrgrPlugOn";
BA_ "LongName" SG_ 2147558232 BMSOffBdChrgrPlugOn "Battery Management System Off Board Charger Plug On";
BA_ "SysSignalName" SG_ 2147558232 BMSOffBdChrgrPlugOn "BMSOffBdChrgrPlugOn";
BA_ "CompuMethodName" SG_ 2147558232 ESS_100ms_Group58_Reserved2 "ESS_100ms_Group58_Reserved2";
BA_ "GenSigStartValue" SG_ 2147558232 ESS_100ms_Group58_Reserved2 255;
BA_ "ISignalName" SG_ 2147558232 ESS_100ms_Group58_Reserved2 "IESS_100ms_Group58_Reserved2";
BA_ "SysSignalName" SG_ 2147558232 ESS_100ms_Group58_Reserved2 "ESS_100ms_Group58_Reserved2";
BA_ "CompuMethodName" SG_ 2147558232 ESS_100ms_Group58_Reserved3 "ESS_100ms_Group58_Reserved3";
BA_ "GenSigStartValue" SG_ 2147558232 ESS_100ms_Group58_Reserved3 255;
BA_ "ISignalName" SG_ 2147558232 ESS_100ms_Group58_Reserved3 "IESS_100ms_Group58_Reserved3";
BA_ "SysSignalName" SG_ 2147558232 ESS_100ms_Group58_Reserved3 "ESS_100ms_Group58_Reserved3";
BA_ "CompuMethodName" SG_ 2147558232 BMSOfbdChrgrSktVol "BMSOfbdChrgrSktVol";
BA_ "ISignalName" SG_ 2147558232 BMSOfbdChrgrSktVol "IBMSOfbdChrgrSktVol";
BA_ "LongName" SG_ 2147558232 BMSOfbdChrgrSktVol "Battery Management System Off-board Charger Socket Voltage";
BA_ "SysSignalName" SG_ 2147558232 BMSOfbdChrgrSktVol "BMSOfbdChrgrSktVol";
BA_ "CompuMethodName" SG_ 2147558232 ESS_100ms_Group58_Reserved5 "ESS_100ms_Group58_Reserved5";
BA_ "GenSigStartValue" SG_ 2147558232 ESS_100ms_Group58_Reserved5 3;
BA_ "ISignalName" SG_ 2147558232 ESS_100ms_Group58_Reserved5 "IESS_100ms_Group58_Reserved5";
BA_ "SysSignalName" SG_ 2147558232 ESS_100ms_Group58_Reserved5 "ESS_100ms_Group58_Reserved5";
BA_ "CompuMethodName" SG_ 2147558232 BMSOffBdChrgrPlugOnV "BMSOffBdChrgrPlugOnV";
BA_ "GenSigStartValue" SG_ 2147558232 BMSOffBdChrgrPlugOnV 1;
BA_ "ISignalName" SG_ 2147558232 BMSOffBdChrgrPlugOnV "IBMSOffBdChrgrPlugOnV";
BA_ "LongName" SG_ 2147558232 BMSOffBdChrgrPlugOnV "Battery Management System Off Board Charger Plug On Validity";
BA_ "SysSignalName" SG_ 2147558232 BMSOffBdChrgrPlugOnV "BMSOffBdChrgrPlugOnV";
BA_ "CompuMethodName" SG_ 2147558232 ESS_100ms_Group58_Reserved4 "ESS_100ms_Group58_Reserved4";
BA_ "GenSigStartValue" SG_ 2147558232 ESS_100ms_Group58_Reserved4 1;
BA_ "ISignalName" SG_ 2147558232 ESS_100ms_Group58_Reserved4 "IESS_100ms_Group58_Reserved4";
BA_ "SysSignalName" SG_ 2147558232 ESS_100ms_Group58_Reserved4 "ESS_100ms_Group58_Reserved4";
BA_ "CompuMethodName" SG_ 2147558232 ESS_100ms_Group58_Reserved6 "ESS_100ms_Group58_Reserved6";
BA_ "GenSigStartValue" SG_ 2147558232 ESS_100ms_Group58_Reserved6 255;
BA_ "ISignalName" SG_ 2147558232 ESS_100ms_Group58_Reserved6 "IESS_100ms_Group58_Reserved6";
BA_ "SysSignalName" SG_ 2147558232 ESS_100ms_Group58_Reserved6 "ESS_100ms_Group58_Reserved6";
BA_ "CompuMethodName" SG_ 2147558232 ESS_100ms_Group58_Reserved7 "ESS_100ms_Group58_Reserved7";
BA_ "GenSigStartValue" SG_ 2147558232 ESS_100ms_Group58_Reserved7 255;
BA_ "ISignalName" SG_ 2147558232 ESS_100ms_Group58_Reserved7 "IESS_100ms_Group58_Reserved7";
BA_ "SysSignalName" SG_ 2147558232 ESS_100ms_Group58_Reserved7 "ESS_100ms_Group58_Reserved7";
BA_ "CompuMethodName" SG_ 2157314309 RZCU_20ms_Group06_CRC "RZCU_20ms_Group06_CRC";
BA_ "ISignalName" SG_ 2157314309 RZCU_20ms_Group06_CRC "IRZCU_20ms_Group06_CRC";
BA_ "LongName" SG_ 2157314309 RZCU_20ms_Group06_CRC "RZCU_20ms_Group06_CRC";
BA_ "SysSignalName" SG_ 2157314309 RZCU_20ms_Group06_CRC "RZCU_20ms_Group06_CRC";
BA_ "CompuMethodName" SG_ 2157314309 RZCU_20ms_Group06_RC "RZCU_20ms_Group06_RC";
BA_ "ISignalName" SG_ 2157314309 RZCU_20ms_Group06_RC "IRZCU_20ms_Group06_RC";
BA_ "LongName" SG_ 2157314309 RZCU_20ms_Group06_RC "RZCU_20ms_Group06_RC";
BA_ "SysSignalName" SG_ 2157314309 RZCU_20ms_Group06_RC "RZCU_20ms_Group06_RC";
BA_ "CompuMethodName" SG_ 2157314309 TrEstdGearV "TrEstdGearV";
BA_ "ISignalName" SG_ 2157314309 TrEstdGearV "ITrEstdGearV";
BA_ "LongName" SG_ 2157314309 TrEstdGearV "Transmission Estimated Gear Validity";
BA_ "SysSignalName" SG_ 2157314309 TrEstdGearV "TrEstdGearV";
BA_ "CompuMethodName" SG_ 2157314309 EPTRdyV "EPTRdyV";
BA_ "GenSigStartValue" SG_ 2157314309 EPTRdyV 1;
BA_ "ISignalName" SG_ 2157314309 EPTRdyV "IEPTRdyV";
BA_ "LongName" SG_ 2157314309 EPTRdyV "Electric Powertrain Ready Validity";
BA_ "SysSignalName" SG_ 2157314309 EPTRdyV "EPTRdyV";
BA_ "CompuMethodName" SG_ 2157314309 EPTRdy "EPTRdy";
BA_ "ISignalName" SG_ 2157314309 EPTRdy "IEPTRdy";
BA_ "LongName" SG_ 2157314309 EPTRdy "Electric Powertrain Ready";
BA_ "SysSignalName" SG_ 2157314309 EPTRdy "EPTRdy";
BA_ "CompuMethodName" SG_ 2157314309 TrShftLvrPosV "TrShftLvrPosV";
BA_ "ISignalName" SG_ 2157314309 TrShftLvrPosV "ITrShftLvrPosV";
BA_ "LongName" SG_ 2157314309 TrShftLvrPosV "Transmission_Shift_Lever_Position_Validity";
BA_ "SysSignalName" SG_ 2157314309 TrShftLvrPosV "TrShftLvrPosV";
BA_ "CompuMethodName" SG_ 2157314309 TrEstdGear "TrEstdGear";
BA_ "ISignalName" SG_ 2157314309 TrEstdGear "ITrEstdGear";
BA_ "LongName" SG_ 2157314309 TrEstdGear "Transmission Estimated Gear";
BA_ "SysSignalName" SG_ 2157314309 TrEstdGear "TrEstdGear";
BA_ "CompuMethodName" SG_ 2157314309 TrShftLvrPos "TrShftLvrPos";
BA_ "ISignalName" SG_ 2157314309 TrShftLvrPos "ITrShftLvrPos";
BA_ "LongName" SG_ 2157314309 TrShftLvrPos "Transmission_Shift_Lever_Position";
BA_ "SysSignalName" SG_ 2157314309 TrShftLvrPos "TrShftLvrPos";
BA_ "CompuMethodName" SG_ 2157314309 RZCU_20ms_Group06_Reserved1 "RZCU_20ms_Group06_Reserved1";
BA_ "GenSigStartValue" SG_ 2157314309 RZCU_20ms_Group06_Reserved1 31;
BA_ "ISignalName" SG_ 2157314309 RZCU_20ms_Group06_Reserved1 "IRZCU_20ms_Group06_Reserved1";
BA_ "SysSignalName" SG_ 2157314309 RZCU_20ms_Group06_Reserved1 "RZCU_20ms_Group06_Reserved1";
BA_ "CompuMethodName" SG_ 2157314309 TrEngdStaV "TrEngdStaV";
BA_ "ISignalName" SG_ 2157314309 TrEngdStaV "ITrEngdStaV";
BA_ "LongName" SG_ 2157314309 TrEngdStaV "Transmission Engaged State Validity_Transmission Control Module";
BA_ "SysSignalName" SG_ 2157314309 TrEngdStaV "TrEngdStaV";
BA_ "CompuMethodName" SG_ 2157314309 TrEngdSta "TrEngdSta";
BA_ "ISignalName" SG_ 2157314309 TrEngdSta "ITrEngdSta";
BA_ "LongName" SG_ 2157314309 TrEngdSta "Transmission Engaged State_Transmission Control Module";
BA_ "SysSignalName" SG_ 2157314309 TrEngdSta "TrEngdSta";
BA_ "CompuMethodName" SG_ 2157314309 RZCU_20ms_Group06_Reserved2 "RZCU_20ms_Group06_Reserved2";
BA_ "GenSigStartValue" SG_ 2157314309 RZCU_20ms_Group06_Reserved2 255;
BA_ "ISignalName" SG_ 2157314309 RZCU_20ms_Group06_Reserved2 "IRZCU_20ms_Group06_Reserved2";
BA_ "SysSignalName" SG_ 2157314309 RZCU_20ms_Group06_Reserved2 "RZCU_20ms_Group06_Reserved2";
BA_ "CompuMethodName" SG_ 2157314309 RZCU_20ms_Group06_Reserved3 "RZCU_20ms_Group06_Reserved3";
BA_ "GenSigStartValue" SG_ 2157314309 RZCU_20ms_Group06_Reserved3 255;
BA_ "ISignalName" SG_ 2157314309 RZCU_20ms_Group06_Reserved3 "IRZCU_20ms_Group06_Reserved3";
BA_ "SysSignalName" SG_ 2157314309 RZCU_20ms_Group06_Reserved3 "RZCU_20ms_Group06_Reserved3";
BA_ "CompuMethodName" SG_ 2157314309 RZCU_20ms_Group06_Reserved4 "RZCU_20ms_Group06_Reserved4";
BA_ "GenSigStartValue" SG_ 2157314309 RZCU_20ms_Group06_Reserved4 255;
BA_ "ISignalName" SG_ 2157314309 RZCU_20ms_Group06_Reserved4 "IRZCU_20ms_Group06_Reserved4";
BA_ "SysSignalName" SG_ 2157314309 RZCU_20ms_Group06_Reserved4 "RZCU_20ms_Group06_Reserved4";
BA_ "CompuMethodName" SG_ 2157314309 RZCU_20ms_Group06_Reserved5 "RZCU_20ms_Group06_Reserved5";
BA_ "GenSigStartValue" SG_ 2157314309 RZCU_20ms_Group06_Reserved5 255;
BA_ "ISignalName" SG_ 2157314309 RZCU_20ms_Group06_Reserved5 "IRZCU_20ms_Group06_Reserved5";
BA_ "SysSignalName" SG_ 2157314309 RZCU_20ms_Group06_Reserved5 "RZCU_20ms_Group06_Reserved5";
BA_ "CompuMethodName" SG_ 2157314311 EPTRunCrkTrmlSts "EPTRunCrkTrmlSts";
BA_ "ISignalName" SG_ 2157314311 EPTRunCrkTrmlSts "IEPTRunCrkTrmlSts";
BA_ "LongName" SG_ 2157314311 EPTRunCrkTrmlSts "Electric Powertrain Run Crank Terminal Status";
BA_ "SysSignalName" SG_ 2157314311 EPTRunCrkTrmlSts "EPTRunCrkTrmlSts";
BA_ "CompuMethodName" SG_ 2157314311 EPTSimEnSpd "EPTSimEnSpd";
BA_ "ISignalName" SG_ 2157314311 EPTSimEnSpd "IEPTSimEnSpd";
BA_ "LongName" SG_ 2157314311 EPTSimEnSpd "Electric Powertrain Simulaiton Engine Speed";
BA_ "SysSignalName" SG_ 2157314311 EPTSimEnSpd "EPTSimEnSpd";
BA_ "CompuMethodName" SG_ 2148098050 RZCU_10ms_Group01_CRC "RZCU_10ms_Group01_CRC";
BA_ "ISignalName" SG_ 2148098050 RZCU_10ms_Group01_CRC "IRZCU_10ms_Group01_CRC";
BA_ "LongName" SG_ 2148098050 RZCU_10ms_Group01_CRC "RZCU_10ms_Group01_CRC";
BA_ "SysSignalName" SG_ 2148098050 RZCU_10ms_Group01_CRC "RZCU_10ms_Group01_CRC";
BA_ "CompuMethodName" SG_ 2148098050 RZCU_10ms_Group01_RC "RZCU_10ms_Group01_RC";
BA_ "ISignalName" SG_ 2148098050 RZCU_10ms_Group01_RC "IRZCU_10ms_Group01_RC";
BA_ "LongName" SG_ 2148098050 RZCU_10ms_Group01_RC "RZCU_10ms_Group01_RC";
BA_ "SysSignalName" SG_ 2148098050 RZCU_10ms_Group01_RC "RZCU_10ms_Group01_RC";
BA_ "CompuMethodName" SG_ 2148098050 ElecMotEmgcShutDwn "ElecMotEmgcShutDwn";
BA_ "ISignalName" SG_ 2148098050 ElecMotEmgcShutDwn "IElecMotEmgcShutDwn";
BA_ "LongName" SG_ 2148098050 ElecMotEmgcShutDwn "Electric_Motor_Emergency_Shut_Down";
BA_ "SysSignalName" SG_ 2148098050 ElecMotEmgcShutDwn "ElecMotEmgcShutDwn";
BA_ "CompuMethodName" SG_ 2148098050 EPTHVEmgcPwrOffReq "EPTHVEmgcPwrOffReq";
BA_ "ISignalName" SG_ 2148098050 EPTHVEmgcPwrOffReq "IEPTHVEmgcPwrOffReq";
BA_ "LongName" SG_ 2148098050 EPTHVEmgcPwrOffReq "Electric_Powertrain_High_Voltage_Emergency_Power_Off_Request";
BA_ "SysSignalName" SG_ 2148098050 EPTHVEmgcPwrOffReq "EPTHVEmgcPwrOffReq";
BA_ "CompuMethodName" SG_ 2148098050 EPTMainRelayDrvReq "EPTMainRelayDrvReq";
BA_ "ISignalName" SG_ 2148098050 EPTMainRelayDrvReq "IEPTMainRelayDrvReq";
BA_ "LongName" SG_ 2148098050 EPTMainRelayDrvReq "Electric_Powertrain_Main_Relay_Drive_Request";
BA_ "SysSignalName" SG_ 2148098050 EPTMainRelayDrvReq "EPTMainRelayDrvReq";
BA_ "CompuMethodName" SG_ 2148098050 EPTStCmdOn "EPTStCmdOn";
BA_ "ISignalName" SG_ 2148098050 EPTStCmdOn "IEPTStCmdOn";
BA_ "LongName" SG_ 2148098050 EPTStCmdOn "Electric Powertrain Start Command On";
BA_ "SysSignalName" SG_ 2148098050 EPTStCmdOn "EPTStCmdOn";
BA_ "CompuMethodName" SG_ 2148098050 EPTAccelActuPosV "EPTAccelActuPosV";
BA_ "ISignalName" SG_ 2148098050 EPTAccelActuPosV "IEPTAccelActuPosV";
BA_ "LongName" SG_ 2148098050 EPTAccelActuPosV "Electric Powertrain Accelerator Actual Position Validity";
BA_ "SysSignalName" SG_ 2148098050 EPTAccelActuPosV "EPTAccelActuPosV";
BA_ "CompuMethodName" SG_ 2148098050 AutoChrgngMngmnt "AutoChrgngMngmnt";
BA_ "ISignalName" SG_ 2148098050 AutoChrgngMngmnt "IAutoChrgngMngmnt";
BA_ "LongName" SG_ 2148098050 AutoChrgngMngmnt "Auto Charging Management";
BA_ "SysSignalName" SG_ 2148098050 AutoChrgngMngmnt "AutoChrgngMngmnt";
BA_ "CompuMethodName" SG_ 2148098050 EPTBrkPdlDscrtInptStsV "EPTBrkPdlDscrtInptStsV";
BA_ "ISignalName" SG_ 2148098050 EPTBrkPdlDscrtInptStsV "IEPTBrkPdlDscrtInptStsV";
BA_ "LongName" SG_ 2148098050 EPTBrkPdlDscrtInptStsV "Electric_Powertrain_Brake_Pedal_Discrete_Input_Status_Validity";
BA_ "SysSignalName" SG_ 2148098050 EPTBrkPdlDscrtInptStsV "EPTBrkPdlDscrtInptStsV";
BA_ "CompuMethodName" SG_ 2148098050 EPTBrkPdlDscrtInptSts "EPTBrkPdlDscrtInptSts";
BA_ "ISignalName" SG_ 2148098050 EPTBrkPdlDscrtInptSts "IEPTBrkPdlDscrtInptSts";
BA_ "LongName" SG_ 2148098050 EPTBrkPdlDscrtInptSts "Electric_Powertrain_Brake_Pedal_Discrete_Input_Status";
BA_ "SysSignalName" SG_ 2148098050 EPTBrkPdlDscrtInptSts "EPTBrkPdlDscrtInptSts";
BA_ "CompuMethodName" SG_ 2148098050 RVSEPTRdy "RVSEPTRdy";
BA_ "ISignalName" SG_ 2148098050 RVSEPTRdy "IRVSEPTRdy";
BA_ "LongName" SG_ 2148098050 RVSEPTRdy "Remote_Vehicle_Start_Electric_Powertrain_Ready";
BA_ "SysSignalName" SG_ 2148098050 RVSEPTRdy "RVSEPTRdy";
BA_ "CompuMethodName" SG_ 2148098050 EPTCrkAbotd "EPTCrkAbotd";
BA_ "ISignalName" SG_ 2148098050 EPTCrkAbotd "IEPTCrkAbotd";
BA_ "LongName" SG_ 2148098050 EPTCrkAbotd "Electric Powertrain Crank Aborted";
BA_ "SysSignalName" SG_ 2148098050 EPTCrkAbotd "EPTCrkAbotd";
BA_ "CompuMethodName" SG_ 2148098050 RZCU_10ms_Group01_Reserved1 "RZCU_10ms_Group01_Reserved1";
BA_ "GenSigStartValue" SG_ 2148098050 RZCU_10ms_Group01_Reserved1 31;
BA_ "ISignalName" SG_ 2148098050 RZCU_10ms_Group01_Reserved1 "IRZCU_10ms_Group01_Reserved1";
BA_ "SysSignalName" SG_ 2148098050 RZCU_10ms_Group01_Reserved1 "RZCU_10ms_Group01_Reserved1";
BA_ "CompuMethodName" SG_ 2148098050 EPTHVDCDCMdReq "EPTHVDCDCMdReq";
BA_ "ISignalName" SG_ 2148098050 EPTHVDCDCMdReq "IEPTHVDCDCMdReq";
BA_ "LongName" SG_ 2148098050 EPTHVDCDCMdReq "Electric Powertrain High Voltage Direct Current Direct Current Mode Request";
BA_ "SysSignalName" SG_ 2148098050 EPTHVDCDCMdReq "EPTHVDCDCMdReq";
BA_ "CompuMethodName" SG_ 2148098050 EPTAccelActuPos "EPTAccelActuPos";
BA_ "ISignalName" SG_ 2148098050 EPTAccelActuPos "IEPTAccelActuPos";
BA_ "LongName" SG_ 2148098050 EPTAccelActuPos "Electric Powertrain Accelerator Actual Position";
BA_ "SysSignalName" SG_ 2148098050 EPTAccelActuPos "EPTAccelActuPos";
BA_ "CompuMethodName" SG_ 2148098050 EPTAccelEfctvPos "EPTAccelEfctvPos";
BA_ "ISignalName" SG_ 2148098050 EPTAccelEfctvPos "IEPTAccelEfctvPos";
BA_ "LongName" SG_ 2148098050 EPTAccelEfctvPos "Electric_Powertrain_Accelerator_Effective_Position";
BA_ "SysSignalName" SG_ 2148098050 EPTAccelEfctvPos "EPTAccelEfctvPos";
BA_ "CompuMethodName" SG_ 2148098050 RZCU_10ms_Group01_Reserved2 "RZCU_10ms_Group01_Reserved2";
BA_ "GenSigStartValue" SG_ 2148098050 RZCU_10ms_Group01_Reserved2 255;
BA_ "ISignalName" SG_ 2148098050 RZCU_10ms_Group01_Reserved2 "IRZCU_10ms_Group01_Reserved2";
BA_ "SysSignalName" SG_ 2148098050 RZCU_10ms_Group01_Reserved2 "RZCU_10ms_Group01_Reserved2";
BA_ "CompuMethodName" SG_ 2148098050 RZCU_10ms_Group01_Reserved3 "RZCU_10ms_Group01_Reserved3";
BA_ "GenSigStartValue" SG_ 2148098050 RZCU_10ms_Group01_Reserved3 255;
BA_ "ISignalName" SG_ 2148098050 RZCU_10ms_Group01_Reserved3 "IRZCU_10ms_Group01_Reserved3";
BA_ "SysSignalName" SG_ 2148098050 RZCU_10ms_Group01_Reserved3 "RZCU_10ms_Group01_Reserved3";
BA_ "CompuMethodName" SG_ 2148098064 RZCU_10ms_Group02_CRC "RZCU_10ms_Group02_CRC";
BA_ "ISignalName" SG_ 2148098064 RZCU_10ms_Group02_CRC "IRZCU_10ms_Group02_CRC";
BA_ "LongName" SG_ 2148098064 RZCU_10ms_Group02_CRC "RZCU_10ms_Group02_CRC";
BA_ "SysSignalName" SG_ 2148098064 RZCU_10ms_Group02_CRC "RZCU_10ms_Group02_CRC";
BA_ "CompuMethodName" SG_ 2148098064 RZCU_10ms_Group02_RC "RZCU_10ms_Group02_RC";
BA_ "ISignalName" SG_ 2148098064 RZCU_10ms_Group02_RC "IRZCU_10ms_Group02_RC";
BA_ "LongName" SG_ 2148098064 RZCU_10ms_Group02_RC "RZCU_10ms_Group02_RC";
BA_ "SysSignalName" SG_ 2148098064 RZCU_10ms_Group02_RC "RZCU_10ms_Group02_RC";
BA_ "CompuMethodName" SG_ 2148098064 EPTTrInptShaftSpdV_R "EPTTrInptShaftSpdV_R";
BA_ "ISignalName" SG_ 2148098064 EPTTrInptShaftSpdV_R "IEPTTrInptShaftSpdV_R";
BA_ "LongName" SG_ 2148098064 EPTTrInptShaftSpdV_R "Electric_Powertrain_Transmission_Input_Shaft_Speed_Valid_Right";
BA_ "SysSignalName" SG_ 2148098064 EPTTrInptShaftSpdV_R "EPTTrInptShaftSpdV_R";
BA_ "CompuMethodName" SG_ 2148098064 RZCU_10ms_Group02_Reserved1 "RZCU_10ms_Group02_Reserved1";
BA_ "GenSigStartValue" SG_ 2148098064 RZCU_10ms_Group02_Reserved1 1;
BA_ "ISignalName" SG_ 2148098064 RZCU_10ms_Group02_Reserved1 "IRZCU_10ms_Group02_Reserved1";
BA_ "SysSignalName" SG_ 2148098064 RZCU_10ms_Group02_Reserved1 "RZCU_10ms_Group02_Reserved1";
BA_ "CompuMethodName" SG_ 2148098064 EPTTrInptShaftSpdV "EPTTrInptShaftSpdV";
BA_ "ISignalName" SG_ 2148098064 EPTTrInptShaftSpdV "IEPTTrInptShaftSpdV";
BA_ "LongName" SG_ 2148098064 EPTTrInptShaftSpdV "Electric_Powertrain_Transmission_Input_Shaft_Speed_Validity";
BA_ "SysSignalName" SG_ 2148098064 EPTTrInptShaftSpdV "EPTTrInptShaftSpdV";
BA_ "CompuMethodName" SG_ 2148098064 EPTSecyAxleInptShaftSpdV "EPTSecyAxleInptShaftSpdV";
BA_ "ISignalName" SG_ 2148098064 EPTSecyAxleInptShaftSpdV "IEPTSecyAxleInptShaftSpdV";
BA_ "LongName" SG_ 2148098064 EPTSecyAxleInptShaftSpdV "Electric_Powertrain_Secondary_Axle_Input_Shaft_Speed_Validity";
BA_ "SysSignalName" SG_ 2148098064 EPTSecyAxleInptShaftSpdV "EPTSecyAxleInptShaftSpdV";
BA_ "CompuMethodName" SG_ 2148098064 EPTSecyAxleInptShaftSpd "EPTSecyAxleInptShaftSpd";
BA_ "GenSigStartValue" SG_ 2148098064 EPTSecyAxleInptShaftSpd 32767;
BA_ "ISignalName" SG_ 2148098064 EPTSecyAxleInptShaftSpd "IEPTSecyAxleInptShaftSpd";
BA_ "LongName" SG_ 2148098064 EPTSecyAxleInptShaftSpd "Electric_Powertrain_Secondary_Axle_Input_Shaft_Speed";
BA_ "SysSignalName" SG_ 2148098064 EPTSecyAxleInptShaftSpd "EPTSecyAxleInptShaftSpd";
BA_ "CompuMethodName" SG_ 2148098064 EPTTrInptShaftSpd "EPTTrInptShaftSpd";
BA_ "GenSigStartValue" SG_ 2148098064 EPTTrInptShaftSpd 32767;
BA_ "ISignalName" SG_ 2148098064 EPTTrInptShaftSpd "IEPTTrInptShaftSpd";
BA_ "LongName" SG_ 2148098064 EPTTrInptShaftSpd "Electric_Powertrain_Transmission_Input_Shaft_Speed";
BA_ "SysSignalName" SG_ 2148098064 EPTTrInptShaftSpd "EPTTrInptShaftSpd";
BA_ "CompuMethodName" SG_ 2148098064 EPTTrInptShaftSpd_R "EPTTrInptShaftSpd_R";
BA_ "GenSigStartValue" SG_ 2148098064 EPTTrInptShaftSpd_R 32767;
BA_ "ISignalName" SG_ 2148098064 EPTTrInptShaftSpd_R "IEPTTrInptShaftSpd_R";
BA_ "LongName" SG_ 2148098064 EPTTrInptShaftSpd_R "Electric_Powertrain_Transmission_Input_Shaft_Speed_Right";
BA_ "SysSignalName" SG_ 2148098064 EPTTrInptShaftSpd_R "EPTTrInptShaftSpd_R";
VAL_ 172 VCU_ISAOvSpdOvRd 0 "VCU_ISAOvSpdOvRd_0_False" 1 "VCU_ISAOvSpdOvRd_1_True" 2 "VCU_ISAOvSpdOvRd_2_Reserve" 3 "VCU_ISAOvSpdOvRd_3_Reserve";
VAL_ 1267 RZCU_NM_BSMtoRMS_PTCANFD 0 "RZCU_NM_BSMtoRMS_PTCANFD_0_False" 1 "RZCU_NM_BSMtoRMS_PTCANFD_1_True";
VAL_ 1267 RZCU_NM_PBSMtoRMS_PTCANFD 0 "RZCU_NM_PBSMtoRMS_PTCANFD_0_False" 1 "RZCU_NM_PBSMtoRMS_PTCANFD_1_True";
VAL_ 1267 RZCU_NM_RMStoNOS_PTCANFD 0 "RZCU_NM_RMStoNOS_PTCANFD_0_False" 1 "RZCU_NM_RMStoNOS_PTCANFD_1_True";
VAL_ 1267 RZCU_NM_RSStoNOS_PTCANFD 0 "RZCU_NM_RSStoNOS_PTCANFD_0_False" 1 "RZCU_NM_RSStoNOS_PTCANFD_1_True";
VAL_ 1267 RZCU_NM_RSStoRMS_PTCANFD 0 "RZCU_NM_RSStoRMS_PTCANFD_0_False" 1 "RZCU_NM_RSStoRMS_PTCANFD_1_True";
VAL_ 1267 RZCU_NM_NOStoRMS_PTCANFD 0 "RZCU_NM_NOStoRMS_PTCANFD_0_False" 1 "RZCU_NM_NOStoRMS_PTCANFD_1_True";
VAL_ 1267 RZCU_NM_NOSSta_PTCANFD 0 "RZCU_NM_NOSSta_PTCANFD_0_False" 1 "RZCU_NM_NOSSta_PTCANFD_1_True";
VAL_ 1267 RZCU_NM_RMSSta_PTCANFD 0 "RZCU_NM_RMSSta_PTCANFD_0_False" 1 "RZCU_NM_RMSSta_PTCANFD_1_True";
VAL_ 1267 RZCU_NWI_PTCANFD 0 "RZCU_NWI_PTCANFD_0_NoWakeNetworkSource" 1 "RZCU_NWI_PTCANFD_1_PowerModeIsRuncrank" 2 "RZCU_NWI_PTCANFD_2_ThermalFaultActive" 5 "RZCU_NWI_PTCANFD_5_OffboardChargerConnected" 8 "RZCU_NWI_PTCANFD_8_PLGOpenDetectByPriMarySwitch" 9 "RZCU_NWI_PTCANFD_9_PLGCloseDetectByPriMarySwitch" 10 "RZCU_NWI_PTCANFD_10_PLGOpenDetectBySecondarySwitch" 12 "RZCU_NWI_PTCANFD_12_PwrlftgtCloseRequest" 15 "RZCU_NWI_PTCANFD_15_EasyLdSwthReqRequest" 16 "RZCU_NWI_PTCANFD_16_ChrgFlapDoorAjarSwActive" 17 "RZCU_NWI_PTCANFD_17_RrSeatBrkSwActive";
VAL_ 1267 RZCU_NOI_PTCANFD 0 "RZCU_NOI_PTCANFD_0_NoRequest" 65535 "RZCU_NOI_PTCANFD_65535_AllNetworkOperationActive";
VAL_ 1267 RZCU_NKI_PTCANFD 0 "RZCU_NKI_PTCANFD_0_NoRequest" 1 "RZCU_NKI_PTCANFD_1_PowerModeIsNonOFF" 2 "RZCU_NKI_PTCANFD_2_ThermalFaultActive" 16 "RZCU_NKI_PTCANFD_16_HVBulid" 256 "RZCU_NKI_PTCANFD_256_RWSActive" 512 "RZCU_NKI_PTCANFD_512_ChargerFlapTimeWindow" 1024 "RZCU_NKI_PTCANFD_1024_EasyLdSwthReqRequest";
VAL_ 247 VMCTarWhlTqMaxLmtV 0 "VMCTarWhlTqMaxLmtV_0_Valid" 1 "VMCTarWhlTqMaxLmtV_1_Invalid";
VAL_ 247 VMCTarReWhlTqMaxLmtV 0 "VMCTarReWhlTqMaxLmtV__0_Valid" 1 "VMCTarReWhlTqMaxLmtV__1_Invalid";
VAL_ 247 EPTTrOtptShaftTotMinAvlblToqV 0 "EPTTrOtptShaftTotMinAvlblToqV_0_Valid" 1 "EPTTrOtptShaftTotMinAvlblToqV_1_Invalid";
VAL_ 247 EPTTrOtptShaftTotMaxAvlblToqV 0 "EPTTrOtptShaftTotMaxAvlblToqV_0_Valid" 1 "EPTTrOtptShaftTotMaxAvlblToqV_1_Invalid";
VAL_ 247 EPTTrOtptShaftTotToqV 0 "EPTTrOtptShaftTotToqV_0_Valid" 1 "EPTTrOtptShaftTotToqV_1_Invalid";
VAL_ 225 PtAPAToqReqResp 0 "PtAPAToqReqResp_0_no_request" 1 "PtAPAToqReqResp_1_request_honored" 2 "PtAPAToqReqResp_2_lost_arbitration" 3 "PtAPAToqReqResp_3_control_not_allowed_for_error" 4 "PtAPAToqReqResp_4_pre_condition_not_satisfied" 5 "PtAPAToqReqResp_5_reserved5" 6 "PtAPAToqReqResp_6_reserved6" 7 "PtAPAToqReqResp_7_reserved7";
VAL_ 225 AutodDrvngToqReqResp 0 "AutodDrvngToqReqResp_0_no_request" 1 "AutodDrvngToqReqResp_1_request_hornored" 2 "AutodDrvngToqReqResp_2_lost_arbitration" 3 "AutodDrvngToqReqResp_3_control_request_not_allow_for_error" 4 "AutodDrvngToqReqResp_4_precondition_not_satisfied";
VAL_ 225 PtACCToqReqResp 0 "PtACCToqReqResp_0_NoRequest" 1 "PtACCToqReqResp_1_RequestHonored" 2 "PtACCToqReqResp_2_LostArbitration" 3 "PtACCToqReqResp_3_ControlNotAllowedForError" 4 "PtACCToqReqResp_4_Pre_conditionNotSatisfied" 5 "PtACCToqReqResp_5_reserved" 6 "PtACCToqReqResp_6_reserved" 7 "PtACCToqReqResp_7_reserved";
VAL_ 225 AIPilotSysSaBrSts 0 "AIPilotSysSaBrSts_0__0" 1 "AIPilotSysSaBrSts_1__1" 2 "AIPilotSysSaBrSts_2__2" 3 "AIPilotSysSaBrSts_3__3" 4 "AIPilotSysSaBrSts_4__4" 5 "AIPilotSysSaBrSts_5__5" 6 "AIPilotSysSaBrSts_6__6" 7 "AIPilotSysSaBrSts_7__7" 8 "AIPilotSysSaBrSts_8__8" 9 "AIPilotSysSaBrSts_9__9" 10 "AIPilotSysSaBrSts_10__10" 11 "AIPilotSysSaBrSts_11__11" 12 "AIPilotSysSaBrSts_12__12" 13 "AIPilotSysSaBrSts_13__13" 14 "AIPilotSysSaBrSts_14__14" 15 "AIPilotSysSaBrSts_15__15";
VAL_ 225 AIPilotSysSaBrInh 0 "AIPilotSysSaBrInh_0__0" 1 "AIPilotSysSaBrInh_1__1" 2 "AIPilotSysSaBrInh_2__2" 3 "AIPilotSysSaBrInh_3__3" 4 "AIPilotSysSaBrInh_4__4" 5 "AIPilotSysSaBrInh_5__5" 6 "AIPilotSysSaBrInh_6__6" 7 "AIPilotSysSaBrInh_7__7" 8 "AIPilotSysSaBrInh_8__8" 9 "AIPilotSysSaBrInh_9__9" 10 "AIPilotSysSaBrInh_10__10" 11 "AIPilotSysSaBrInh_11__11" 12 "AIPilotSysSaBrInh_12__12" 13 "AIPilotSysSaBrInh_13__13" 14 "AIPilotSysSaBrInh_14__14" 15 "AIPilotSysSaBrInh_15__15";
VAL_ 225 AccelOvrd 0 "AccelOvrd_0_False" 1 "AccelOvrd_1_True";
VAL_ 201 PtAPASts 0 "PtAPASts_0_Disable" 1 "PtAPASts_1_Standby" 2 "PtAPASts_2_SemiMinusapaActive" 3 "PtAPASts_3_FullyMinusapaActive" 4 "PtAPASts_4_Failed";
VAL_ 201 VCUAPAUnderCtrlA 0 "VCUAPAUnderCtrlA_0_Inhibit" 1 "VCUAPAUnderCtrlA_1_Available" 2 "VCUAPAUnderCtrlA_2_ActiveForSpeedControl" 3 "VCUAPAUnderCtrlA_3_ActiveForTorqueControl" 4 "VCUAPAUnderCtrlA_4_Failed";
VAL_ 201 VCUAPAFltRsn 0 "VCUAPAFltRsn_0_Normal" 1 "VCUAPAFltRsn_1_Speed_Response_over_time" 2 "VCUAPAFltRsn_2_Torque_Response_over_time" 3 "VCUAPAFltRsn_3_VCU_Internal_Fault";
VAL_ 201 EPTAPARevrDrgReqResp 0 "EPTAPARevrDrgReqResp_0_Defult" 1 "EPTAPARevrDrgReqResp_1_intervene" 2 "EPTAPARevrDrgReqResp_2_intervene_off";
VAL_ 517 RZCUeSw10Sts 0 "RZCUeSw10Sts_0_Unknown" 1 "RZCUeSw10Sts_1_Off" 2 "RZCUeSw10Sts_2_On" 3 "RZCUeSw10Sts_3_LatchOn" 4 "RZCUeSw10Sts_4_Failure" 5 "RZCUeSw10Sts_5_GoingDown";
VAL_ 517 RZCUeSw10DiagSts 0 "RZCUeSw10DiagSts_0_NoFault" 1 "RZCUeSw10DiagSts_1_OCP" 2 "RZCUeSw10DiagSts_2_OVP" 3 "RZCUeSw10DiagSts_3_UVP" 4 "RZCUeSw10DiagSts_4_OT" 5 "RZCUeSw10DiagSts_5_SPI_Fault" 6 "RZCUeSw10DiagSts_6_ChipFault" 7 "RZCUeSw10DiagSts_7_OpenCircuit" 8 "RZCUeSw10DiagSts_8_ShortToGND" 9 "RZCUeSw10DiagSts_9_ShortToBattery" 10 "RZCUeSw10DiagSts_10_OtherFault" 11 "RZCUeSw10DiagSts_11_Drive_Mismatch";
VAL_ 517 RZCUIgnSts 0 "RZCUIgnSts_0_Unknown" 1 "RZCUIgnSts_1_Off" 2 "RZCUIgnSts_2_On" 3 "RZCUIgnSts_3_LatchOn" 4 "RZCUIgnSts_4_FailureOff" 5 "RZCUIgnSts_5_Reserve";
VAL_ 517 RZCUIgnDiagSts 0 "RZCUIgnDiagSts_0_NoFault" 1 "RZCUIgnDiagSts_1_OCP" 2 "RZCUIgnDiagSts_2_OVP" 3 "RZCUIgnDiagSts_3_UVP" 4 "RZCUIgnDiagSts_4_OT" 5 "RZCUIgnDiagSts_5_SPI_Fault" 6 "RZCUIgnDiagSts_6_ChipFault" 7 "RZCUIgnDiagSts_7_OpenCircuit" 8 "RZCUIgnDiagSts_8_ShortToGND" 9 "RZCUIgnDiagSts_9_ShortToBattery" 10 "RZCUIgnDiagSts_10_OtherFault" 11 "RZCUIgnDiagSts_11_Drive_Mismatch";
VAL_ 517 RZCUeFs3Sts 0 "RZCUeFs3Sts_0_Unknown" 1 "RZCUeFs3Sts_1_Off" 2 "RZCUeFs3Sts_2_On" 3 "RZCUeFs3Sts_3_LatchOn" 4 "RZCUeFs3Sts_4_Failure" 5 "RZCUeFs3Sts_5_GoingDown";
VAL_ 517 RZCUeFs3DiagSts 0 "RZCUeFs3DiagSts_0_NoFault" 1 "RZCUeFs3DiagSts_1_OCP" 2 "RZCUeFs3DiagSts_2_OVP" 3 "RZCUeFs3DiagSts_3_UVP" 4 "RZCUeFs3DiagSts_4_OT" 5 "RZCUeFs3DiagSts_5_SPI_Fault" 6 "RZCUeFs3DiagSts_6_ChipFault" 7 "RZCUeFs3DiagSts_7_OpenCircuit" 8 "RZCUeFs3DiagSts_8_ShortToGND" 9 "RZCUeFs3DiagSts_9_ShortToBattery" 10 "RZCUeFs3DiagSts_10_OtherFault" 11 "RZCUeFs3DiagSts_11_Drive_Mismatch";
VAL_ 517 RZCUeFs2Sts 0 "RZCUeFs2Sts_0_Unknown" 1 "RZCUeFs2Sts_1_Off" 2 "RZCUeFs2Sts_2_On" 3 "RZCUeFs2Sts_3_LatchOn" 4 "RZCUeFs2Sts_4_Failure" 5 "RZCUeFs2Sts_5_GoingDown";
VAL_ 517 RZCUeFs2DiagSts 0 "RZCUeFs2DiagSts_0_NoFault" 1 "RZCUeFs2DiagSts_1_OCP" 2 "RZCUeFs2DiagSts_2_OVP" 3 "RZCUeFs2DiagSts_3_UVP" 4 "RZCUeFs2DiagSts_4_OT" 5 "RZCUeFs2DiagSts_5_SPI_Fault" 6 "RZCUeFs2DiagSts_6_ChipFault" 7 "RZCUeFs2DiagSts_7_OpenCircuit" 8 "RZCUeFs2DiagSts_8_ShortToGND" 9 "RZCUeFs2DiagSts_9_ShortToBattery" 10 "RZCUeFs2DiagSts_10_OtherFault" 11 "RZCUeFs2DiagSts_11_Drive_Mismatch";
VAL_ 517 RZCUeFs1Sts 0 "RZCUeFs1Sts_0_Unknown" 1 "RZCUeFs1Sts_1_Off" 2 "RZCUeFs1Sts_2_On" 3 "RZCUeFs1Sts_3_LatchOn" 4 "RZCUeFs1Sts_4_Failure" 5 "RZCUeFs1Sts_5_GoingDown";
VAL_ 517 RZCUeFs1DiagSts 0 "RZCUeFs1DiagSts_0_NoFault" 1 "RZCUeFs1DiagSts_1_OCP" 2 "RZCUeFs1DiagSts_2_OVP" 3 "RZCUeFs1DiagSts_3_UVP" 4 "RZCUeFs1DiagSts_4_OT" 5 "RZCUeFs1DiagSts_5_SPI_Fault" 6 "RZCUeFs1DiagSts_6_ChipFault" 7 "RZCUeFs1DiagSts_7_OpenCircuit" 8 "RZCUeFs1DiagSts_8_ShortToGND" 9 "RZCUeFs1DiagSts_9_ShortToBattery" 10 "RZCUeFs1DiagSts_10_OtherFault" 11 "RZCUeFs1DiagSts_11_Drive_Mismatch";
VAL_ 517 RZCUeSw9Sts 0 "RZCUeSw9Sts_0_Unknown" 1 "RZCUeSw9Sts_1_Off" 2 "RZCUeSw9Sts_2_On" 3 "RZCUeSw9Sts_3_LatchOn" 4 "RZCUeSw9Sts_4_Failure" 5 "RZCUeSw9Sts_5_GoingDown";
VAL_ 517 RZCUeSw9DiagSts 0 "RZCUeSw9DiagSts_0_NoFault" 1 "RZCUeSw9DiagSts_1_OCP" 2 "RZCUeSw9DiagSts_2_OVP" 3 "RZCUeSw9DiagSts_3_UVP" 4 "RZCUeSw9DiagSts_4_OT" 5 "RZCUeSw9DiagSts_5_SPI_Fault" 6 "RZCUeSw9DiagSts_6_ChipFault" 7 "RZCUeSw9DiagSts_7_OpenCircuit" 8 "RZCUeSw9DiagSts_8_ShortToGND" 9 "RZCUeSw9DiagSts_9_ShortToBattery" 10 "RZCUeSw9DiagSts_10_OtherFault" 11 "RZCUeSw9DiagSts_11_Drive_Mismatch";
VAL_ 1265 SAC_NM_BSMtoRMS_PTCANFD 0 "SAC_NM_BSMtoRMS_PTCANFD_0_SAC_NM_BSMtoRMS_0_False" 1 "SAC_NM_BSMtoRMS_PTCANFD_1_SAC_NM_BSMtoRMS_1_True";
VAL_ 1265 SAC_NM_PBSMtoRMS_PTCANFD 0 "SAC_NM_PBSMtoRMS_PTCANFD_0_SAC_NM_PBSMtoRMS_0_False" 1 "SAC_NM_PBSMtoRMS_PTCANFD_1_SAC_NM_PBSMtoRMS_1_True";
VAL_ 1265 SAC_NM_RMStoNOS_PTCANFD 0 "SAC_NM_RMStoNOS_PTCANFD_0_SAC_NM_RMStoNOS_0_False" 1 "SAC_NM_RMStoNOS_PTCANFD_1_SAC_NM_RMStoNOS_1_True";
VAL_ 1265 SAC_NM_RSStoNOS_PTCANFD 0 "SAC_NM_RSStoNOS_PTCANFD_0_SAC_NM_RSStoNOS_0_False" 1 "SAC_NM_RSStoNOS_PTCANFD_1_SAC_NM_RSStoNOS_1_True";
VAL_ 1265 SAC_NM_RSStoRMS_PTCANFD 0 "SAC_NM_RSStoRMS_PTCANFD_0_SAC_NM_RSStoRMS_0_False" 1 "SAC_NM_RSStoRMS_PTCANFD_1_SAC_NM_RSStoRMS_1_True";
VAL_ 1265 SAC_NM_NOStoRMS_PTCANFD 0 "SAC_NM_NOStoRMS_PTCANFD_0_SAC_NM_NOStoRMS_0_False" 1 "SAC_NM_NOStoRMS_PTCANFD_1_SAC_NM_NOStoRMS_1_True";
VAL_ 1265 SAC_NM_NOSSta_PTCANFD 0 "SAC_NM_NOSSta_PTCANFD_0_SAC_NM_NOSSta_0_False" 1 "SAC_NM_NOSSta_PTCANFD_1_SAC_NM_NOSSta_1_True";
VAL_ 1265 SAC_NM_RMSSta_PTCANFD 0 "SAC_NM_RMSSta_PTCANFD_0_SAC_NM_RMSSta_0_False" 1 "SAC_NM_RMSSta_PTCANFD_1_SAC_NM_RMSSta_1_True";
VAL_ 1265 SAC_NWI_PTCANFD 0 "SAC_NWI_PTCANFD_0_NoWakeNetworkSource";
VAL_ 1265 SAC_NOI_PTCANFD 0 "SAC_NOI_PTCANFD_0_NoRequest" 65535 "SAC_NOI_PTCANFD_65535_AllNetworkOperationActive";
VAL_ 1265 SAC_NKI_PTCANFD 0 "SAC_NKI_PTCANFD_0_NoRequest" 1 "SAC_NKI_PTCANFD_1_PowerModeIsNonOFF" 2 "SAC_NKI_PTCANFD_2_EOPCAfterrun";
VAL_ 396 VSELatAccV_SDM 0 "VSELatAccV_SDM_0_Valid" 1 "VSELatAccV_SDM_1_Invalid";
VAL_ 396 VehDynYawRateV_SDM 0 "VehDynYawRateV_SDM_0_Valid" 1 "VehDynYawRateV_SDM_1_Invalid";
VAL_ 396 VSELongtAccV_SDM 0 "VSELongtAccV_SDM_0_Valid" 1 "VSELongtAccV_SDM_1_Invalid";
VAL_ 485 AutocTrCmddGear_TCM 0 "AutocTrCmddGear_TCM_0_Not_Supported" 1 "AutocTrCmddGear_TCM_1_First_Gear" 2 "AutocTrCmddGear_TCM_2_Second_Gear" 3 "AutocTrCmddGear_TCM_3_Third_Gear" 4 "AutocTrCmddGear_TCM_4_Fourth_Gear" 5 "AutocTrCmddGear_TCM_5_Fifth_Gear" 6 "AutocTrCmddGear_TCM_6_Sixth_Gear" 7 "AutocTrCmddGear_TCM_7_Seventh_Gear" 8 "AutocTrCmddGear_TCM_8_Eighth_Gear" 9 "AutocTrCmddGear_TCM_9_Ninth_Gear" 10 "AutocTrCmddGear_TCM_10_reserved" 11 "AutocTrCmddGear_TCM_11_reserved" 12 "AutocTrCmddGear_TCM_12_reserved" 13 "AutocTrCmddGear_TCM_13_Neutral_Gear" 14 "AutocTrCmddGear_TCM_14_Reverse_Gear" 15 "AutocTrCmddGear_TCM_15_Park_Gear";
VAL_ 485 DrvrShftCtrlTrgtGear_TCM 0 "DrvrShftCtrlTrgtGear_TCM_0_Not_Supported" 1 "DrvrShftCtrlTrgtGear_TCM_1_First_Gear" 2 "DrvrShftCtrlTrgtGear_TCM_2_Second_Gear" 3 "DrvrShftCtrlTrgtGear_TCM_3_Third_Gear" 4 "DrvrShftCtrlTrgtGear_TCM_4_Fourth_Gear" 5 "DrvrShftCtrlTrgtGear_TCM_5_Fifth_Gear" 6 "DrvrShftCtrlTrgtGear_TCM_6_Sixth_Gear" 7 "DrvrShftCtrlTrgtGear_TCM_7_Seventh_Gear" 8 "DrvrShftCtrlTrgtGear_TCM_8_Eighth_Gear" 9 "DrvrShftCtrlTrgtGear_TCM_9_Ninth_Gear";
VAL_ 485 TrEPBAppReq 0 "TrEPBAppReq_0_False" 1 "TrEPBAppReq_1_True";
VAL_ 485 DrvrShftCtrlReqDndIO 0 "DrvrShftCtrlReqDndIO_0_False" 1 "DrvrShftCtrlReqDndIO_1_True";
VAL_ 485 TrShftLvrPos_TCM 0 "TrShftLvrPos_TCM_0__Between_Ranges" 1 "TrShftLvrPos_TCM_1__Park_Range" 2 "TrShftLvrPos_TCM_2__Reverse_Range" 3 "TrShftLvrPos_TCM_3__Neutral_Range" 4 "TrShftLvrPos_TCM_4__Forward_Range_A" 5 "TrShftLvrPos_TCM_5__Forward_Range_B" 6 "TrShftLvrPos_TCM_6__Forward_Range_C" 7 "TrShftLvrPos_TCM_7__Forward_Range_D" 8 "TrShftLvrPos_TCM_8__Forward_Range_E" 9 "TrShftLvrPos_TCM_9__Forward_Range_F" 10 "TrShftLvrPos_TCM_10__Forward_Range_G" 11 "TrShftLvrPos_TCM_11__Forward_Range_H" 12 "TrShftLvrPos_TCM_12_Reserved" 13 "TrShftLvrPos_TCM_13_Reserved" 14 "TrShftLvrPos_TCM_14_Reserved" 15 "TrShftLvrPos_TCM_15__Lever_Position_Unknown";
VAL_ 485 TrShftLvrPosV_TCM 0 "TrShftLvrPosV_TCM_0_Valid" 1 "TrShftLvrPosV_TCM_1_Invalid";
VAL_ 485 TrPrkSysF 0 "TrPrkSysF_0_False" 1 "TrPrkSysF_1_True";
VAL_ 485 TrPrkPos 0 "TrPrkPos_0_Non_Park_Position" 1 "TrPrkPos_1_Park_Position" 2 "TrPrkPos_2_Working_in_Progress" 3 "TrPrkPos_3_Unknown";
VAL_ 485 TrTrgtShftLvrPos 0 "TrTrgtShftLvrPos_0_Between_Ranges" 1 "TrTrgtShftLvrPos_1_Park_Range" 2 "TrTrgtShftLvrPos_2_Reverse_Range" 3 "TrTrgtShftLvrPos_3_Neutral_Range" 4 "TrTrgtShftLvrPos_4_Forward_Range_A" 5 "TrTrgtShftLvrPos_5_Forward_Range_B" 6 "TrTrgtShftLvrPos_6_Forward_Range_C" 7 "TrTrgtShftLvrPos_7_Forward_Range_D" 8 "TrTrgtShftLvrPos_8_Forward_Range_E" 9 "TrTrgtShftLvrPos_9_Forward_Range_F" 10 "TrTrgtShftLvrPos_10_Forward_Range_G" 11 "TrTrgtShftLvrPos_11_Forward_Range_H" 12 "TrTrgtShftLvrPos_12_Reserved" 13 "TrTrgtShftLvrPos_13_Reserved" 14 "TrTrgtShftLvrPos_14_Reserved" 15 "TrTrgtShftLvrPos_15_Lever_Position_Unknown";
VAL_ 485 TrEstdGear_TCM 0 "TrEstdGear_TCM_0_Not_Supported" 1 "TrEstdGear_TCM_1_First_Gear" 2 "TrEstdGear_TCM_2_Second_Gear" 3 "TrEstdGear_TCM_3_Third_Gear" 4 "TrEstdGear_TCM_4_Fourth_Gear" 5 "TrEstdGear_TCM_5_Fifth_Gear" 6 "TrEstdGear_TCM_6_Sixth_Gear" 7 "TrEstdGear_TCM_7_Seventh_Gear" 8 "TrEstdGear_TCM_8_Eighth_Gear" 9 "TrEstdGear_TCM_9_Ninth_Gear" 10 "TrEstdGear_TCM_10_reserved" 11 "TrEstdGear_TCM_11_reserved" 12 "TrEstdGear_TCM_12_reserved" 13 "TrEstdGear_TCM_13_Neutral_Gear" 14 "TrEstdGear_TCM_14_Reverse_Gear" 15 "TrEstdGear_TCM_15_Park_Gear";
VAL_ 485 TrTapUpTapDwnMdSts_TCM 0 "TrTapUpTapDwnMdSts_TCM_0__No_Activation" 1 "TrTapUpTapDwnMdSts_TCM_1__Driver_Shift_Control_Active" 2 "TrTapUpTapDwnMdSts_TCM_2__Electronic_Range_Select_Active";
VAL_ 485 TrShftPtrnASts_TCM 0 "TrShftPtrnASts_TCM_0__Default_Shift_Pattern_Active" 1 "TrShftPtrnASts_TCM_Shift_Pattern_1_Active" 2 "TrShftPtrnASts_TCM_Shift_Pattern_2_Active" 3 "TrShftPtrnASts_TCM_Shift_Pattern_3_Active" 4 "TrShftPtrnASts_TCM_Shift_Pattern_4_Active" 5 "TrShftPtrnASts_TCM_5__PT_Non_Protection_Pattern_Active" 6 "TrShftPtrnASts_TCM_6__PT_Protection_Pattern_Active";
VAL_ 485 TrEstdGearV_TCM 0 "TrEstdGearV_TCM_0_Valid" 1 "TrEstdGearV_TCM_1_Invalid";
VAL_ 485 TrCrpMdA_TCM 0 "TrCrpMdA_TCM_0_False" 1 "TrCrpMdA_TCM_1_True";
VAL_ 485 TrEngdSta_TCM 0 "TrEngdSta_TCM_0__Transmission_Not_Engaged" 1 "TrEngdSta_TCM_1__Transmissino_Engaged_in_Forward" 2 "TrEngdSta_TCM_2__Transmission_Engaged_in_Reverse" 3 "TrEngdSta_TCM_3__Operating_State_Not_Reached";
VAL_ 485 TrEngdStaV_TCM 0 "TrEngdStaV_TCM_0_Valid" 1 "TrEngdStaV_TCM_1_Invalid";
VAL_ 485 TrIntnlSwPos 0 "TrIntnlSwPos_0__Between_Range" 1 "TrIntnlSwPos_1__Park_Range" 2 "TrIntnlSwPos_2__Reverse_Range" 3 "TrIntnlSwPos_3__Neutral_Range" 4 "TrIntnlSwPos_4__Forward_Range_A" 5 "TrIntnlSwPos_5__Forward_Range_B" 6 "TrIntnlSwPos_6__Forward_Range_C" 7 "TrIntnlSwPos_7__Forward_Range_D" 8 "TrIntnlSwPos_8__Forward_Range_E" 9 "TrIntnlSwPos_9__Forward_Range_F" 10 "TrIntnlSwPos_10__Forward_Range_G" 11 "TrIntnlSwPos_11__Forward_Range_H" 12 "TrIntnlSwPos_12__Lever_Position_Unknown";
VAL_ 485 TrIntnlSwPosV 0 "TrIntnlSwPosV_0_Valid" 1 "TrIntnlSwPosV_1_Invalid";
VAL_ 393 TrImmdCrkshftToqRespTyp 0 "TrImmdCrkshftToqRespT_0_Inactive" 1 "TrImmdCrkshftToqRespT_1_PleasabilityLimited" 2 "TrImmdCrkshftToqRespT_2_MaximumRange" 3 "TrImmdCrkshftToqRespT_3_AutomaticActuatorSelection";
VAL_ 393 TrPrdtdCrkshftToqIntrvnTyp 0 "TrPrdtdCrkshftToqIntrvnTyp_0_NoRequest" 1 "TrPrdtdCrkshftToqIntrvnTyp_1_MaximumLimit" 2 "TrPrdtdCrkshftToqIntrvnTyp_2_MinimumLimit" 3 "TrPrdtdCrkshftToqIntrvnTyp_3_UnusedandReserved";
VAL_ 393 TrGearV 0 "TrGearV_0_Valid" 1 "TrGearV_1_Invalid";
VAL_ 340 SCUAPAUnderCtrlA_TCM 0 "SCUAPAUnderCtrlA_0_Inhibit" 1 "SCUAPAUnderCtrlA_1_Available_For_Control" 2 "SCUAPAUnderCtrlA_2_Active_For_Control" 3 "SCUAPAUnderCtrlA_3_Failed" 4 "SCUAPAUnderCtrlA_4_Reserved" 5 "SCUAPAUnderCtrlA_5_Reserved" 6 "SCUAPAUnderCtrlA_6_Reserved" 7 "SCUAPAUnderCtrlA_7_Reserved";
VAL_ 340 TrAPACanclReq 0 "TrAPACanclReq_0_False" 1 "TrAPACanclReq_1_True";
VAL_ 340 SCUDrvrIntrvnA_TCM 0 "SCUDrvrIntrvnA_0_Inactive" 1 "SCUDrvrIntrvnA_1_Active";
VAL_ 443 TrACCToqReqResp 0 "TrACCToqReqResp_0_no_request" 1 "TrACCToqReqResp_1_request_honored" 2 "TrACCToqReqResp_2_lost_arbitration" 3 "TrACCToqReqResp_3_control_request_not_allowed_for_error" 4 "TrACCToqReqResp_4_pre_condition_not_satisfied" 5 "TrACCToqReqResp_5_reserved" 6 "TrACCToqReqResp_6_reserved" 7 "TrACCToqReqResp_7_reserved";
VAL_ 410 EDUOilPmpMotEnb 0 "EDUOilPmpMotEnb_0_False" 1 "EDUOilPmpMotEnb_1_True";
VAL_ 410 EDUOilTemV 0 "EDUOilTemV_0_Valid" 1 "EDUOilTemV_1_Invalid";
VAL_ 534 SWSPB3SwStuckL 0 "SWSPB3SwStuckL_l_0_No_Stuck" 1 "SWSPB3SwStuckL_l_1_Stuck";
VAL_ 534 SWSSelRSwStuckL 0 "SWSSelRSwStuckL_l_0_No_Stuck" 1 "SWSSelRSwStuckL_l_1_Stuck";
VAL_ 534 SWSSelLSwStuckL 0 "SWSSelLSwStuckL_l_0_No_Stuck" 1 "SWSSelLSwStuckL_l_1_Stuck";
VAL_ 534 SWSPB2SwStuckL 0 "SWSPB2SwStuckL_l_0_No_Stuck" 1 "SWSPB2SwStuckL_l_1_Stuck";
VAL_ 534 SWSLFnChngSwA 0 "SWSLFnChngSwA_0_False" 1 "SWSLFnChngSwA_1_True";
VAL_ 534 SWSCnfmSwStuckL 0 "SWSCnfmSwStuckL_l_0_No_Stuck" 1 "SWSCnfmSwStuckL_l_1_Stuck";
VAL_ 534 SWSPB1SwStuckL 0 "SWSPB1SwStuckL_l_0_No_Stuck" 1 "SWSPB1SwStuckL_l_1_Stuck";
VAL_ 534 DMSSts 0 "DMSSts_0_Off" 1 "DMSSts_1_Standby" 2 "DMSSts_2_Active" 3 "DMSSts_3_Camera_Blocked" 4 "DMSSts_4_System_temporary_unavailable" 5 "DMSSts_5_Service_required" 6 "DMSSts_6_Initialization" 7 "DMSSts_7_Performance_Degradation";
VAL_ 534 VehboardSetting 0 "VehboardSetting_0_init" 1 "VehboardSetting_1_map" 2 "VehboardSetting_2_simple" 3 "VehboardSetting_3_MR";
VAL_ 534 RoughRoaddetection 0 "RoughRoaddetection_0_NotDetected" 1 "RoughRoaddetection_1_Detected";
VAL_ 1216 ZXD_NM_BSMtoRMS_PTCANFD 0 "ZXD_NM_BSMtoRMS_PTCANFD_0_False" 1 "ZXD_NM_BSMtoRMS_PTCANFD_1_True";
VAL_ 1216 ZXD_NM_PBSMtoRMS_PTCANFD 0 "ZXD_NM_PBSMtoRMS_PTCANFD_0_False" 1 "ZXD_NM_PBSMtoRMS_PTCANFD_1_True";
VAL_ 1216 ZXD_NM_RMStoNOS_PTCANFD 0 "ZXD_NM_RMStoNOS_PTCANFD_0_False" 1 "ZXD_NM_RMStoNOS_PTCANFD_1_True";
VAL_ 1216 ZXD_NM_RSStoNOS_PTCANFD 0 "ZXD_NM_RSStoNOS_PTCANFD_0_False" 1 "ZXD_NM_RSStoNOS_PTCANFD_1_True";
VAL_ 1216 ZXD_NM_RSStoRMS_PTCANFD 0 "ZXD_NM_RSStoRMS_PTCANFD_0_False" 1 "ZXD_NM_RSStoRMS_PTCANFD_1_True";
VAL_ 1216 ZXD_NM_NOStoRMS_PTCANFD 0 "ZXD_NM_NOStoRMS_PTCANFD_0_False" 1 "ZXD_NM_NOStoRMS_PTCANFD_1_True";
VAL_ 1216 ZXD_NM_NOSSta_PTCANFD 0 "ZXD_NM_NOSSta_PTCANFD_0_False" 1 "ZXD_NM_NOSSta_PTCANFD_1_True";
VAL_ 1216 ZXD_NM_RMSSta_PTCANFD 0 "ZXD_NM_RMSSta_PTCANFD_0_False" 1 "ZXD_NM_RMSSta_PTCANFD_1_True";
VAL_ 1216 ZXD_NWI_PTCANFD 0 "ZXD_NWI_PTCANFD_0_NoWakeNetworkSource" 1 "ZXD_NWI_PTCANFD_1_PowerModeIsNonOFF";
VAL_ 1216 ZXD_NOI_PTCANFD 0 "ZXD_NOI_PTCANFD_0_NoRequest" 65535 "ZXD_NOI_PTCANFD_65535_AllNetworkOperationActive";
VAL_ 1216 ZXD_NKI_PTCANFD 0 "ZXD_NKI_PTCANFD_0_NoRequest" 1 "ZXD_NKI_PTCANFD_1_PowerModeIsNonOFF";
VAL_ 2147559184 LowTemWtrPumpAfterRunLvl 0 "LowTemWtrPumpAfterRunLvl_0_level_0" 1 "LowTemWtrPumpAfterRunLvl_1_level_1" 2 "LowTemWtrPumpAfterRunLvl_2_level_2" 3 "LowTemWtrPumpAfterRunLvl_3_level_3" 4 "LowTemWtrPumpAfterRunLvl_4_level_4" 5 "LowTemWtrPumpAfterRunLvl_5_level_5" 6 "LowTemWtrPumpAfterRunLvl_6_level_6" 7 "LowTemWtrPumpAfterRunLvl_7_level_7";
VAL_ 2147559184 AmbtTemSnsrFlrStsInvsn 0 "AmbtTemSnsrFlrStsInvsn_0_Reserve" 1 "AmbtTemSnsrFlrStsInvsn_1_Signal_Not_Plausible" 2 "AmbtTemSnsrFlrStsInvsn_2_Feed_Voltage_Low" 3 "AmbtTemSnsrFlrStsInvsn_3_Feed_Voltage_High" 4 "AmbtTemSnsrFlrStsInvsn_4_Open_Circuit" 5 "AmbtTemSnsrFlrStsInvsn_5_Short_Circuit_to_Ground" 6 "AmbtTemSnsrFlrStsInvsn_6_Short_Circuit_to_Battery" 7 "AmbtTemSnsrFlrStsInvsn_7_Valid";
VAL_ 2147559184 AmbtTemSnsrFlrSts 0 "AmbtTemSnsrFlrSts_0_Valid" 1 "AmbtTemSnsrFlrSts_1_Short_Circuit_to_Battery" 2 "AmbtTemSnsrFlrSts_2_Short_Circuit_to_Ground" 3 "AmbtTemSnsrFlrSts_3_Open_Circuit" 4 "AmbtTemSnsrFlrSts_4_Feed_Voltage_High" 5 "AmbtTemSnsrFlrSts_5_Feed_Voltage_Low" 6 "AmbtTemSnsrFlrSts_6_Signal_Not_Plausible" 7 "AmbtTemSnsrFlrSts_7_Reserve";
VAL_ 2147559184 FuelSysVentCmdd 0 "FuelSysVentCmdd_0_False" 1 "FuelSysVentCmdd_1_True";
VAL_ 2147559184 PrmntDTCDrvngCycCrtra 0 "PrmntDTCDrvngCycCrtra_0_False" 1 "PrmntDTCDrvngCycCrtra_1_True";
VAL_ 2147559184 FuelSysVentFltA 0 "FuelSysVentFltA_0_False" 1 "FuelSysVentFltA_1_True";
VAL_ 2147559184 EnDrvngCycCrtra 0 "EnDrvngCycCrtra_0_False" 1 "EnDrvngCycCrtra_1_True";
VAL_ 2147559184 IUPREnStFnshd 0 "IUPREnStFnshd_0_False" 1 "IUPREnStFnshd_1_True";
VAL_ 2147559184 IUPRDnmtrIncmntd 0 "IUPRDnmtrIncmntd_0_False" 1 "IUPRDnmtrIncmntd_1_True";
VAL_ 2147559184 IUPRDnmtrInh 0 "IUPRDnmtrInh_0_False" 1 "IUPRDnmtrInh_1_True";
VAL_ 2147559184 CoolngFanLvlFdbk 0 "CoolngFanLvlFdbk_0_OFF" 1 "CoolngFanLvlFdbk_1_1Level" 2 "CoolngFanLvlFdbk_2_2Level" 3 "CoolngFanLvlFdbk_3_3Level" 4 "CoolngFanLvlFdbk_4_4Level" 5 "CoolngFanLvlFdbk_5_5Level" 6 "CoolngFanLvlFdbk_6_6Level" 7 "CoolngFanLvlFdbk_7_7Level" 8 "CoolngFanLvlFdbk_8_8Level" 9 "CoolngFanLvlFdbk_9_9Level" 10 "CoolngFanLvlFdbk_10_10Level" 11 "CoolngFanLvlFdbk_11_11Level" 12 "CoolngFanLvlFdbk_12_12Level" 13 "CoolngFanLvlFdbk_13_13Level" 14 "CoolngFanLvlFdbk_14_14Level" 15 "CoolngFanLvlFdbk_15_15Level";
VAL_ 2147559185 EPTClntPumpSta 0 "EPTCIntPumpSta_0_Initial" 1 "EPTCIntPumpSta_1__NormalOn" 2 "EPTCIntPumpSta_2_NormalOff" 3 "EPTCIntPumpSta_3_OverTem" 4 "EPTCIntPumpSta_4_OVerCrnt" 5 "EPTCIntPumpSta_5__Dry" 6 "EPTCIntPumpSta_6_Stall" 7 "EPTCIntPumpSta_7_CommErr" 8 "EPTCIntPumpSta_8_OpenCircle" 9 "EPTCIntPumpSta_9_ShortCircle" 10 "EPTCIntPumpSta_10_Driver_error" 11 "EPTCIntPumpSta_11_OverPwr" 12 "EPTClntPumpSta_12_Short_to_battery";
VAL_ 2147559185 ESSClntPumpSta 0 "ESSClntPumpSta_0_Initial" 1 "ESSClntPumpSta_1_NormalOn" 2 "ESSClntPumpSta_2_NormalOff" 3 "ESSClntPumpSta_3_OverTem" 4 "ESSClntPumpSta_4_OVerCrnt" 5 "ESSClntPumpSta_5_Dry" 6 "ESSClntPumpSta_6_Stall" 7 "ESSClntPumpSta_7_CommErr" 8 "ESSClntPumpSta_8_OpenCircle" 9 "ESSClntPumpSta_9_ShortCircle" 10 "ESSClntPumpSta_10_Driver_error" 11 "ESSClntPumpSta_11_OverPwr";
VAL_ 2147559185 EPTElecWtrPumpTrgtSpd 255 "EPTElecWtrPumpTrgtSpd_255_invalid";
VAL_ 2147559185 ESSElecWtrPumpTrgtSpd 255 "ESSElecWtrPumpTrgtSpd_255_invalid";
VAL_ 2147559185 CoolngFanWorkSta 0 "CoolngFanWorkSta_0_Normal_Work" 1 "CoolngFanWorkSta_1_Cooling_Fan_Short_Circuit_to_GND" 2 "CoolngFanWorkSta_2_Cooling_Fan_Short_Circuit_to_Batt" 3 "CoolngFanWorkSta_3_Cooling_Fan_Open_Circuit" 4 "CoolngFanWorkSta_4_Cooling_Fan_PCB_over_temperature" 5 "CoolngFanWorkSta_5_Cooling_Fan_Stall_Detected" 6 "CoolngFanWorkSta_6_Cooling_Fan_PreDriver_error" 7 "CoolngFanWorkSta_7_Cooling_Fan_Over_Current" 8 "CoolngFanWorkSta_8_Cooling_Fan_Over_Voltage" 9 "CoolngFanWorkSta_9_Cooling_Fan_Under_Voltage" 10 "CoolngFanWorkSta_10_Cooling_Fan_Over_Speed" 11 "CoolngFanWorkSta_11_Cooling_Fan_PreDriver_over_temperature";
VAL_ 2147559185 LowTemWtrPumpTrgtSpd 255 "LowTemWtrPumpTrgtSpd_255_invalid";
VAL_ 2147559186 RVSPtRunAbotdRsn 0 "RVSPtRunAbotdRsn_0__No_Aborted" 1 "RVSPtRunAbotdRsn_1__shifter_non_park" 2 "RVSPtRunAbotdRsn_2__Vehicle_speed_Limit" 3 "RVSPtRunAbotdRsn_3__MIL_Related_DTC" 4 "RVSPtRunAbotdRsn_4__Lost_communication_with_BCM_or_GW_or_SCS_ABS_or_TCM" 5 "RVSPtRunAbotdRsn_5__In_post_collision" 6 "RVSPtRunAbotdRsn_6__Engine_overheating" 7 "RVSPtRunAbotdRsn_7__KL15_disconnected" 8 "RVSPtRunAbotdRsn_8__Low_Oil_Pressure" 9 "RVSPtRunAbotdRsn_9__Engine_speed_Limit" 10 "RVSPtRunAbotdRsn_10__Accelerator_pedal_Limit" 11 "RVSPtRunAbotdRsn_11__Authentication_Failure" 12 "RVSPtRunAbotdRsn_12__Max_Run_time_expire" 13 "RVSPtRunAbotdRsn_13_Reserved" 14 "RVSPtRunAbotdRsn_14_Reserved" 15 "RVSPtRunAbotdRsn_15__Unknown_Reason";
VAL_ 2147559186 EnGPFLampOnSts 0 "EnGPFLampOnSts_0_Off" 1 "EnGPFLampOnSts_1_GPF_RegeneratiOn_Reminder" 2 "EnGPFLampOnSts_2_GPF_Regenerating_Active" 3 "EnGPFLampOnSts_3_GPF_Full_Reminder";
VAL_ 2147559186 RVSPtCrkAbotdRsn 0 "RVSPtCrkAbotdRsn_0__No_Aborted" 1 "RVSPtCrkAbotdRsn_1__shifter_non_park_or_Transmission_Crank_not_permit" 2 "RVSPtCrkAbotdRsn_2__Vehicle_speed_Limit" 3 "RVSPtCrkAbotdRsn_3__MIL_Related_DTC" 4 "RVSPtCrkAbotdRsn_4__Lost_communication_with_BCM_or_GW_or_SCS_ABS_or_TCM" 5 "RVSPtCrkAbotdRsn_5__In_post_collision" 6 "RVSPtCrkAbotdRsn_6__Fuel_level_low" 7 "RVSPtCrkAbotdRsn_7__KL15_disconnected" 8 "RVSPtCrkAbotdRsn_8__Max_Crank_time_expire" 9 "RVSPtCrkAbotdRsn_9__In_Charging" 10 "RVSPtCrkAbotdRsn_10_Reserved" 11 "RVSPtCrkAbotdRsn_11_Reserved" 12 "RVSPtCrkAbotdRsn_12_Reserved" 13 "RVSPtCrkAbotdRsn_13_Reserved" 14 "RVSPtCrkAbotdRsn_14_Reserved" 15 "RVSPtCrkAbotdRsn_15__Unknown_Reason";
VAL_ 2147559186 VehRfulSta 0 "VehRfulSta_0_Inactive" 1 "VehRfulSta_1_Wait_To_Refuel" 2 "VehRfulSta_2_Ready_To_Refuel" 3 "VehRfulSta_3_Fail_To_Refuel";
VAL_ 2147559186 ECMCoolngFanPWMReqV 0 "ECMCoolngFanPWMReqV_0_valid" 1 "ECMCoolngFanPWMReqV_1_invalid";
VAL_ 2147631108 BMSEmsnRltdMalfA 0 "BMSEmsnRltdMalfA_0_False" 1 "BMSEmsnRltdMalfA_1_True";
VAL_ 2147631108 BMSOdoFctV 0 "BMSOdoFctV_0_Valid" 1 "BMSOdoFctV_1_Invalid";
VAL_ 2147631108 BMSStdAvlblEnrgV 0 "BMSStdAvlblEnrgV_0_Valid" 1 "BMSStdAvlblEnrgV_1_Invalid";
VAL_ 2147631108 BMSChrgTrgtStdAvlblEnrgV 0 "BMSChrgTrgtStdAvlblEnrgV_0_Valid" 1 "BMSChrgTrgtStdAvlblEnrgV_1_Invalid";
VAL_ 2147631108 BMSDisTrgtStdAvlblEnrgV 0 "BMSDisTrgtStdAvlblEnrgV_0_Valid" 1 "BMSDisTrgtStdAvlblEnrgV_1_Invalid";
VAL_ 2147549444 BMSPosPtIsltnRstcV 0 "BMSPosPtIsltnRstcV_0_Valid" 1 "BMSPosPtIsltnRstcV_1_Invalid";
VAL_ 2147549444 BMSNegPtIsltnRstcV 0 "BMSNegPtIsltnRstcV_0_Valid" 1 "BMSNegPtIsltnRstcV_1_Invalid";
VAL_ 2147549442 BMSOnbdChrgSpRsn 0 "BMSOnbdChrgSpRsn_0_None" 1 "BMSOnbdChrgSpRsn_1_ChargerSatusAbnormal" 2 "BMSOnbdChrgSpRsn_2_ChargerPortOverTemperature" 3 "BMSOnbdChrgSpRsn_3_ChargingGunNotProperlyPluggedIn" 4 "BMSOnbdChrgSpRsn_4_ChargerVoltageMismatch";
VAL_ 2147549442 BMSPackSOH 1022 "BMSPackSOH_1022_Init" 1023 "BMSPackSOH_1023_Error";
VAL_ 2147549442 BMSFltLamp 0 "BMSFltLamp_0_No_lamp" 1 "BMSFltLamp_1_Yellow_Lamp" 2 "BMSFltLamp_2_Red_Lamp" 3 "BMSFltLamp_3_Flashing_Yellow_Lamp" 4 "BMSFltLamp_4_Flashing_Red_Lamp" 5 "BMSFltLamp_5_Reservered1" 6 "BMSFltLamp_6_Reservered2" 7 "BMSFltLamp_7_Reservered3";
VAL_ 2147549442 HVBatShutOff 0 "HVBatShutOff_0_False" 1 "HVBatShutOff_1_True";
VAL_ 2147558227 HVBatSOCHiResV 0 "HVBatSOCHiResV_0_Valid" 1 "HVBatSOCHiResV_1_Invalid";
VAL_ 2147558232 BMSOfbdChrgrSktVolV 0 "BMSOfbdChrgrSktVolV_0_Valid" 1 "BMSOfbdChrgrSktVolV_1_Invalid";
VAL_ 2147558232 BMSOffBdChrgrPlugOn 0 "BMSOffBdChrgrPlugOn_0_Disconnected" 1 "BMSOffBdChrgrPlugOn_1_Connected" 2 "BMSOffBdChrgrPlugOn_2_Semi_connected" 3 "BMSOffBdChrgrPlugOn_3_Abnormal_connected";
VAL_ 2147558232 BMSOffBdChrgrPlugOnV 0 "BMSOffBdChrgrPlugOnV_0_Valid" 1 "BMSOffBdChrgrPlugOnV_1_Invalid";
VAL_ 2157314309 TrEstdGearV 0 "TrEstdGearV_0_Valid" 1 "TrEstdGearV_1_Invalid";
VAL_ 2157314309 EPTRdyV 0 "EPTRdyV_0_Valid" 1 "EPTRdyV_1_Invalid";
VAL_ 2157314309 EPTRdy 0 "EPTRdy_0_NotReady" 1 "EPTRdy_1_Ready";
VAL_ 2157314309 TrShftLvrPosV 0 "TrShftLvrPosV_0_Valid" 1 "TrShftLvrPosV_1_Invalid";
VAL_ 2157314309 TrEstdGear 0 "TrEstdGear_0_NotSupported" 1 "TrEstdGear_1_FirstGear" 2 "TrEstdGear_2_SecondGear" 3 "TrEstdGear_3_ThirdGear" 4 "TrEstdGear_4_FourthGear" 5 "TrEstdGear_5_FifthGear" 6 "TrEstdGear_6_SixthGear" 7 "TrEstdGear_7_SeventhGear" 8 "TrEstdGear_8_EighthGear" 13 "TrEstdGear_13_NeutralGear" 14 "TrEstdGear_14_ReverseGear" 15 "TrEstdGear_15_ParkGear";
VAL_ 2157314309 TrShftLvrPos 0 "TrShftLvrPos_0_Between_Ranges" 1 "TrShftLvrPos_1_Park_Range" 2 "TrShftLvrPos_2_Reverse_Range" 3 "TrShftLvrPos_3_Neutral_Range" 4 "TrShftLvrPos_4_Forward_Range_A" 5 "TrShftLvrPos_5_Forward_Range_B" 6 "TrShftLvrPos_6_Forward_Range_C" 7 "TrShftLvrPos_7_Forward_Range_D" 8 "TrShftLvrPos_8_Forward_Range_E" 9 "TrShftLvrPos_9_Forward_Range_F" 10 "TrShftLvrPos_10_Forward_Range_G" 11 "TrShftLvrPos_11_Forward_Range_H" 12 "TrShftLvrPos_12_reserved" 13 "TrShftLvrPos_13_reserved" 14 "TrShftLvrPos_14_reserved" 15 "TrShftLvrPos_15_Lever_Position_Unknown";
VAL_ 2157314309 TrEngdStaV 0 "TrEngdStaV_0_Valid" 1 "TrEngdStaV_1_Invalid";
VAL_ 2157314309 TrEngdSta 0 "TrEngdSta_0_Transmission_Not_Engaged" 1 "TrEngdSta_1_Transmissino_Engaged_in_Forward" 2 "TrEngdSta_2_Transmission_Engaged_in_Reverse" 3 "TrEngdSta_3_Operating_State_Not_Reached";
VAL_ 2157314311 EPTRunCrkTrmlSts 0 "EPTRunCrkTrmlSts_0_Inactive" 1 "EPTRunCrkTrmlSts_1_Active" 2 "EPTRunCrkTrmlSts_2_Reserved" 3 "EPTRunCrkTrmlSts_3_Reserved";
VAL_ 2148098050 ElecMotEmgcShutDwn 0 "ElecMotEmgcShutDwn_0_False" 1 "ElecMotEmgcShutDwn_1_True";
VAL_ 2148098050 EPTHVEmgcPwrOffReq 0 "EPTHVEmgcPwrOffReq_0_NoRequest" 1 "EPTHVEmgcPwrOffReq_1_request";
VAL_ 2148098050 EPTMainRelayDrvReq 0 "EPTMainRelayDrvReq_0_OpenRequest" 1 "EPTMainRelayDrvReq_1_CloseMainRelay" 2 "EPTMainRelayDrvReq_2_CloseFastChargeRelay" 3 "EPTMainRelayDrvReq_3_Reserved";
VAL_ 2148098050 EPTStCmdOn 0 "EPTStCmdOn_0_False" 1 "EPTStCmdOn_1_True";
VAL_ 2148098050 EPTAccelActuPosV 0 "EPTAccelActuPosV_0_Valid" 1 "EPTAccelActuPosV_1_Invalid";
VAL_ 2148098050 AutoChrgngMngmnt 0 "AutoChrgngMngmnt_0_Default" 1 "AutoChrgngMngmnt_1_Hold" 2 "AutoChrgngMngmnt_2_Stop_and_Enable" 3 "AutoChrgngMngmnt_3_Stop_and_Inhibited";
VAL_ 2148098050 EPTBrkPdlDscrtInptStsV 0 "EPTBrkPdlDscrtInptStsV_0_Valid" 1 "EPTBrkPdlDscrtInptStsV_1_Invalid";
VAL_ 2148098050 EPTBrkPdlDscrtInptSts 0 "EPTBrkPdlDscrtInptSts_0_BrakeNotApplied" 1 "EPTBrkPdlDscrtInptSts_1_BrakeApplied";
VAL_ 2148098050 RVSEPTRdy 0 "RVSEPTRdy_0_False" 1 "RVSEPTRdy_1_True";
VAL_ 2148098050 EPTCrkAbotd 0 "EPTCrkAbotd_0_False" 1 "EPTCrkAbotd_1_True";
VAL_ 2148098050 EPTHVDCDCMdReq 0 "EPTHVDCDCMdReq_0_Standby" 1 "EPTHVDCDCMdReq_1_Boost" 2 "EPTHVDCDCMdReq_2_Buck" 3 "EPTHVDCDCMdReq_3_DC_link_discharge" 4 "EPTHVDCDCMdReq_4_Reserved" 5 "EPTHVDCDCMdReq_5_Reserved" 6 "EPTHVDCDCMdReq_6_Reserved" 7 "EPTHVDCDCMdReq_7_Reserved";
VAL_ 2148098064 EPTTrInptShaftSpdV_R 0 "EPTTrInptShaftSpdV_R_0_Valid" 1 "EPTTrInptShaftSpdV_R_1_Invalid";
VAL_ 2148098064 EPTTrInptShaftSpdV 0 "EPTTrInptShaftSpdV_0_Valid" 1 "EPTTrInptShaftSpdV_1_Invalid";
VAL_ 2148098064 EPTSecyAxleInptShaftSpdV 0 "EPTSecyAxleInptShaftSpdV_0_Valid" 1 "EPTSecyAxleInptShaftSpdV_1_Invalid";
SIG_GROUP_ 172 IRZCU_10ms_Group90 1 : RZCU_10ms_Group90_CRC RZCU_10ms_Group90_RC RZCU_10ms_Group90_Reserved103 RZCU_10ms_Group90_Reserved111 RZCU_10ms_Group90_Reserved119 RZCU_10ms_Group90_Reserved127 RZCU_10ms_Group90_Reserved135 RZCU_10ms_Group90_Reserved143 RZCU_10ms_Group90_Reserved15 RZCU_10ms_Group90_Reserved151 RZCU_10ms_Group90_Reserved159 RZCU_10ms_Group90_Reserved23 RZCU_10ms_Group90_Reserved31 RZCU_10ms_Group90_Reserved39 RZCU_10ms_Group90_Reserved47 RZCU_10ms_Group90_Reserved55 RZCU_10ms_Group90_Reserved63 RZCU_10ms_Group90_Reserved71 RZCU_10ms_Group90_Reserved79 RZCU_10ms_Group90_Reserved83 RZCU_10ms_Group90_Reserved87 RZCU_10ms_Group90_Reserved95 VCU_ISAOvSpdOvRd;
SIG_GROUP_ 247 IRZCU_10ms_Group22 1 : EPTTrOtptShaftTotMaxAvlblToq EPTTrOtptShaftTotMaxAvlblToqV EPTTrOtptShaftTotMinAvlblToq EPTTrOtptShaftTotMinAvlblToqV EPTTrOtptShaftTotToq EPTTrOtptShaftTotToqV RZCU_10ms_Group22_CRC RZCU_10ms_Group22_RC RZCU_10ms_Group22_Reserved47 RZCU_10ms_Group22_Reserved95 VMCTarReWhlTqMaxLmt VMCTarReWhlTqMaxLmtV VMCTarWhlTqMaxLmt VMCTarWhlTqMaxLmtV;
SIG_GROUP_ 225 IRZCU_10ms_Group23 1 : AIPilotSysSaBrInh AIPilotSysSaBrSts AccelOvrd AutodDrvngToqReqResp PtACCToqReqResp PtAPAToqReqResp RZCU_10ms_Group23_CRC RZCU_10ms_Group23_RC RZCU_10ms_Group23_Reserved1 RZCU_10ms_Group23_Reserved10 RZCU_10ms_Group23_Reserved11 RZCU_10ms_Group23_Reserved12 RZCU_10ms_Group23_Reserved13 RZCU_10ms_Group23_Reserved14 RZCU_10ms_Group23_Reserved15 RZCU_10ms_Group23_Reserved2 RZCU_10ms_Group23_Reserved3 RZCU_10ms_Group23_Reserved4 RZCU_10ms_Group23_Reserved5 RZCU_10ms_Group23_Reserved6 RZCU_10ms_Group23_Reserved7 RZCU_10ms_Group23_Reserved8 RZCU_10ms_Group23_Reserved9;
SIG_GROUP_ 201 IRZCU_10ms_Group24 1 : EPTAPARevrDrgReqResp PtAPASts RZCU_10ms_Group24_CRC RZCU_10ms_Group24_RC RZCU_10ms_Group24_Reserved1 RZCU_10ms_Group24_Reserved2 RZCU_10ms_Group24_Reserved3 RZCU_10ms_Group24_Reserved4 RZCU_10ms_Group24_Reserved5 RZCU_10ms_Group24_Reserved6 VCUAPAFltRsn VCUAPAUnderCtrlA;
SIG_GROUP_ 396 ISDM_20ms_Group03 1 : SDM_20ms_Group03_CRC SDM_20ms_Group03_RC SDM_20ms_Group03_Reserved1 SDM_20ms_Group03_Reserved2 SDM_20ms_Group03_Reserved3 SDM_20ms_Group03_Reserved4 VSELatAccV_SDM VSELatAcc_SDM VSELongtAccV_SDM VSELongtAcc_SDM VehDynYawRateV_SDM VehDynYawRate_SDM;
SIG_GROUP_ 485 ITCM_025ms_Group02 1 : AutocTrCmddGear_TCM DrvrShftCtrlReqDndIO DrvrShftCtrlTrgtGear_TCM TCM_025ms_Group02_Reserved1 TCM_025ms_Group02_Reserved2 TCM_025ms_Group02_Reserved3 TCM_025ms_PDU02_CRC TCM_025ms_PDU02_RC TrCrpMdA_TCM TrEPBAppReq TrEngdStaV_TCM TrEngdSta_TCM TrEstdGearV_TCM TrEstdGear_TCM TrIntnlSwPos TrIntnlSwPosV TrPrkPos TrPrkSysF TrShftLvrPosV_TCM TrShftLvrPos_TCM TrShftPtrnASts_TCM TrTapUpTapDwnMdSts_TCM TrTrgtShftLvrPos;
SIG_GROUP_ 393 ITCM_PTCAN_FrP05 1 : TCM_025ms_PDU05_CRC TCM_025ms_PDU05_RC TCM_025ms_PDU05_Reserve01 TrGear TrGearV TrImmdCrkshftToqReqVal TrImmdCrkshftToqRespTyp TrPrdtdCrkshftToqIntrvnTyp TrPrdtdCrkshftToqReqV;
SIG_GROUP_ 340 ITCM_020ms_PDU18 1 : CluActTorq SCUAPAUnderCtrlA_TCM SCUDrvrIntrvnA_TCM TCM_020ms_PDU18_CRC TCM_020ms_PDU18_RC TCM_020ms_PDU18_Reserve01 TCM_020ms_PDU18_Reserve02 TCM_020ms_PDU18_Reserve03 TrAPACanclReq;
SIG_GROUP_ 443 ITCM_025ms_PDU20 1 : TCM_025ms_PDU20_CRC TCM_025ms_PDU20_RC TCM_025ms_PDU20_Reserve01 TCM_025ms_PDU20_Reserve02 TCM_025ms_PDU20_Reserve03 TCM_025ms_PDU20_Reserve04 TrACCToqReqResp;
SIG_GROUP_ 534 IICBVC_50ms_Group256 1 : DMSSts ICBVC_50ms_Group256_CRC ICBVC_50ms_Group256_RC ICBVC_50ms_Group256_Reserved100 ICBVC_50ms_Group256_Reserved103 ICBVC_50ms_Group256_Reserved111 ICBVC_50ms_Group256_Reserved119 ICBVC_50ms_Group256_Reserved127 ICBVC_50ms_Group256_Reserved85 ICBVC_50ms_Group256_Reserved95 ICBVC_50ms_Group256_Reserved96 RoadCrvt RoadCrvtDist RoadSlope RoadSlopeDist RoughRoaddetection RoughRoaddetectionDist SWSCnfmSwStuckL SWSLFnChngSwA SWSPB1SwStuckL SWSPB2SwStuckL SWSPB3SwStuckL SWSSelLSwStuckL SWSSelRSwStuckL VehboardSetting;
